VERSION ""

NS_ :

BS_:

BU_: VCM TCM ECM EBS ACM

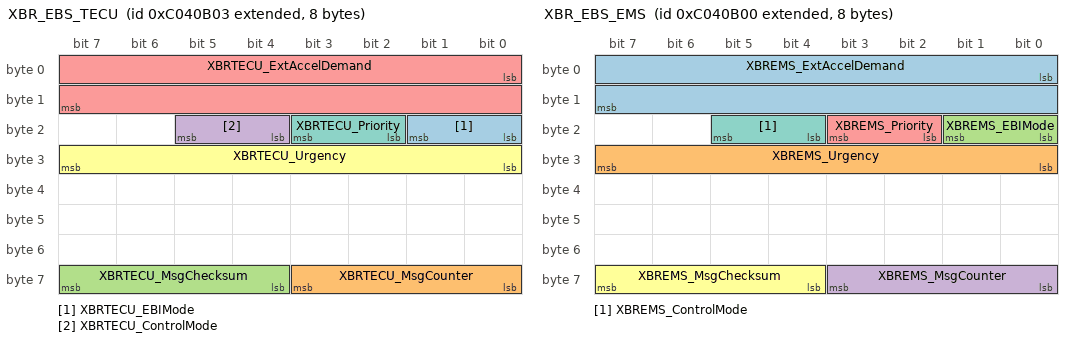
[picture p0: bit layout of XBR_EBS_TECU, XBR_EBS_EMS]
BO_ 2349075203 XBR_EBS_TECU: 8 TCM
 SG_ XBRTECU_EBIMode : 16|2@1+ (1,0) [0|0] ""  ECM,EBS,VCM
 SG_ XBRTECU_MsgCounter : 56|4@1+ (1,0) [0|15] "Count"  VCM,EBS,ECM
 SG_ XBRTECU_MsgChecksum : 60|4@1+ (1,0) [0|15] "Count"  EBS,VCM,ECM
 SG_ XBRTECU_ControlMode : 20|2@1+ (1,0) [0|0] ""  VCM,ECM,EBS
 SG_ XBRTECU_ExtAccelDemand : 0|16@1+ (0.00048828125,-15.687) [-15.687|16.31251171875] "m_per_s_squared"  ECM,VCM,EBS
 SG_ XBRTECU_Urgency : 24|8@1+ (0.4,0) [0|102] "Percent"  ECM,EBS,VCM
 SG_ XBRTECU_Priority : 18|2@1+ (1,0) [0|0] ""  EBS,VCM,ECM

BO_ 2349075200 XBR_EBS_EMS: 8 ECM
 SG_ XBREMS_ExtAccelDemand : 0|16@1+ (0.00048828125,-15.687) [-15.687|16.31251171875] "m_per_s_squared"  VCM,EBS
 SG_ XBREMS_Urgency : 24|8@1+ (0.4,0) [0|102] "Percent"  EBS,VCM
 SG_ XBREMS_EBIMode : 16|2@1+ (1,0) [0|0] ""  VCM,EBS
 SG_ XBREMS_MsgCounter : 56|4@1+ (1,0) [0|15] "Count"  VCM,EBS
 SG_ XBREMS_Priority : 18|2@1+ (1,0) [0|0] ""  VCM,EBS
 SG_ XBREMS_MsgChecksum : 60|4@1+ (1,0) [0|15] "Count"  EBS,VCM
 SG_ XBREMS_ControlMode : 20|2@1+ (1,0) [0|0] ""  EBS,VCM

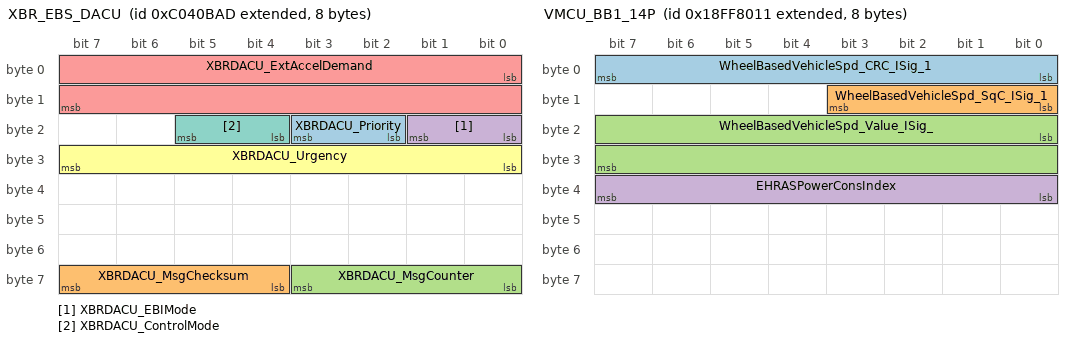
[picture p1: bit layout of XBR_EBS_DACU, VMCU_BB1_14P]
BO_ 2349075373 XBR_EBS_DACU: 8 VCM
 SG_ XBRDACU_Priority : 18|2@1+ (1,0) [0|0] ""  EBS,TCM
 SG_ XBRDACU_MsgChecksum : 60|4@1+ (1,0) [0|15] "Count"  EBS,TCM
 SG_ XBRDACU_MsgCounter : 56|4@1+ (1,0) [0|15] "Count"  EBS,TCM
 SG_ XBRDACU_EBIMode : 16|2@1+ (1,0) [0|0] ""  EBS,TCM
 SG_ XBRDACU_ExtAccelDemand : 0|16@1+ (0.00048828125,-15.687) [-15.687|16.31251171875] "m_per_s_squared"  EBS,TCM
 SG_ XBRDACU_Urgency : 24|8@1+ (0.4,0) [0|102] "Percent"  EBS,TCM
 SG_ XBRDACU_ControlMode : 20|2@1+ (1,0) [0|0] ""  TCM,EBS

BO_ 2566848256 WFI_X_EMS: 8 ECM
 SG_ WaterInFuelAlarm : 0|2@1+ (1,0) [0|0] ""  VCM

BO_ 2566845201 VP1_X_VMCU: 8 VCM
 SG_ VehiclePosSAE_Longitude : 32|32@1+ (1E-007,-210) [-210|219.4967295] "deg"  TCM
 SG_ VehiclePosSAE_Latitude : 0|32@1+ (1E-007,-210) [-210|219.4967295] "deg"  TCM

BO_ 2566881297 VMCU_BB1_14P: 8 VCM
 SG_ WheelBasedVehicleSpd_CRC_ISig_1 : 0|8@1+ (1,0) [0|255] ""  EBS
 SG_ WheelBasedVehicleSpd_SqC_ISig_1 : 8|4@1+ (1,0) [0|14] "NotApplicable"  EBS
 SG_ WheelBasedVehicleSpd_Value_ISig_ : 16|16@1+ (0.00390625,0) [0|255.99609375] "Km_per_h"  EBS
 SG_ EHRASPowerConsIndex : 32|8@1+ (0.5,0) [0|127.5] "Percent"  EBS

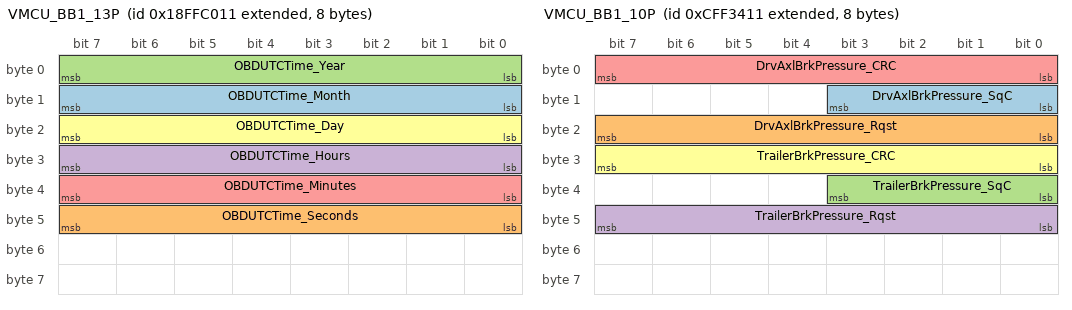
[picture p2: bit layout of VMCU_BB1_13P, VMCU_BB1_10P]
BO_ 2566897681 VMCU_BB1_13P: 8 VCM
 SG_ OBDUTCTime_Month : 8|8@1+ (1,0) [0|255] "Months"  ECM,ACM
 SG_ OBDUTCTime_Seconds : 40|8@1+ (0.25,0) [0|63.75] "s"  ECM,ACM
 SG_ OBDUTCTime_Year : 0|8@1+ (1,1985) [1985|2240] "Years"  ACM,ECM
 SG_ OBDUTCTime_Hours : 24|8@1+ (1,0) [0|255] "h"  ECM,ACM
 SG_ OBDUTCTime_Minutes : 32|8@1+ (1,0) [0|255] "min"  ECM,ACM
 SG_ OBDUTCTime_Day : 16|8@1+ (0.25,0) [0|63.75] "Days"  ACM,ECM

BO_ 2365535249 VMCU_BB1_10P: 8 VCM
 SG_ DrvAxlBrkPressure_SqC : 8|4@1+ (1,0) [0|14] "NotApplicable"  EBS
 SG_ DrvAxlBrkPressure_Rqst : 16|8@1+ (5,0) [0|1275] "kPa"  EBS
 SG_ TrailerBrkPressure_SqC : 32|4@1+ (1,0) [0|14] "NotApplicable"  EBS
 SG_ TrailerBrkPressure_Rqst : 40|8@1+ (5,0) [0|1275] "kPa"  EBS
 SG_ DrvAxlBrkPressure_CRC : 0|8@1+ (1,0) [0|255] ""  EBS
 SG_ TrailerBrkPressure_CRC : 24|8@1+ (1,0) [0|255] ""  EBS

BO_ 2499788567 VMCU_BB1_08P: 8 VCM
 SG_ DrvrRetarderBrakeBlending_rqst_I : 10|2@1+ (1,0) [0|0] ""  TCM,EBS
 SG_ Trailer2LiftAxle2PosReq : 44|2@1+ (1,0) [0|0] ""  EBS
 SG_ Trailer4LiftAxle2PosReq : 52|2@1+ (1,0) [0|0] ""  EBS
 SG_ GearLeverPositionBackup : 12|4@1+ (1,0) [0|0] ""  TCM
 SG_ Trailer2LiftAxle1PosReq : 42|2@1+ (1,0) [0|0] ""  EBS
 SG_ Trailer5LiftAxle2PosReq : 56|2@1+ (1,0) [0|0] ""  EBS
 SG_ GearLeverPos2Backup_CRC : 16|8@1+ (1,0) [0|255] ""  TCM
 SG_ DriverRetarderRequest_ISig_1 : 3|3@1+ (1,0) [0|0] ""  EBS,ECM,TCM,ACM
 SG_ Trailer1LiftAxl2ePosReq : 40|2@1+ (1,0) [0|0] ""  EBS
 SG_ GearLeverPos2Backup_SqC : 24|4@1+ (1,0) [0|14] "NotApplicable"  TCM
 SG_ Trailer1LiftAxle1PosReq : 38|2@1+ (1,0) [0|0] ""  EBS
 SG_ DrvrRetarderBrakeProgram_rqst_IS : 8|2@1+ (1,0) [0|0] ""  TCM
 SG_ Trailer4LiftAxle1PosReq : 50|2@1+ (1,0) [0|0] ""  EBS
 SG_ EHERearAxleSteeringFuncStatus : 35|3@1+ (1,0) [0|0] ""  EBS
 SG_ EHRearAxleSteeringFuncStatus : 32|3@1+ (1,0) [0|0] ""  EBS
 SG_ Trailer5LiftAxle1PosReq : 54|2@1+ (1,0) [0|0] ""  EBS
 SG_ Trailer3LiftAxle1PosReq : 46|2@1+ (1,0) [0|0] ""  EBS
 SG_ GearLeverPos2Backup_Rqst : 28|4@1+ (1,0) [0|0] ""  TCM
 SG_ Trailer3LiftAxle2PosReq : 48|2@1+ (1,0) [0|0] ""  EBS

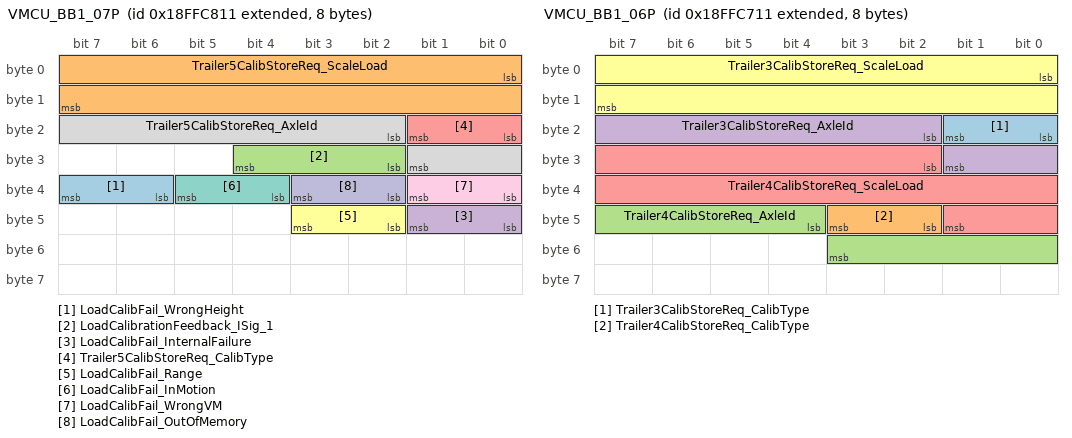
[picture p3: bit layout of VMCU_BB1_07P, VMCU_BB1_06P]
BO_ 2566899729 VMCU_BB1_07P: 8 VCM
 SG_ LoadCalibFail_WrongHeight : 38|2@1+ (1,0) [0|0] ""  EBS
 SG_ Trailer5CalibStoreReq_ScaleLoad : 0|16@1+ (1,0) [0|65535] "kg"  EBS
 SG_ LoadCalibrationFeedback_ISig_1 : 26|3@1+ (1,0) [0|0] ""  EBS
 SG_ LoadCalibFail_InternalFailure : 40|2@1+ (1,0) [0|0] ""  EBS
 SG_ Trailer5CalibStoreReq_CalibType : 16|2@1+ (1,0) [0|0] ""  EBS
 SG_ LoadCalibFail_Range : 42|2@1+ (1,0) [0|0] ""  EBS
 SG_ LoadCalibFail_InMotion : 36|2@1+ (1,0) [0|0] ""  EBS
 SG_ Trailer5CalibStoreReq_AxleId : 18|8@1+ (1,0) [0|255] "NotApplicable"  EBS
 SG_ LoadCalibFail_WrongVM : 32|2@1+ (1,0) [0|0] ""  EBS
 SG_ LoadCalibFail_OutOfMemory : 34|2@1+ (1,0) [0|0] ""  EBS

BO_ 2566899473 VMCU_BB1_06P: 8 VCM
 SG_ Trailer3CalibStoreReq_CalibType : 16|2@1+ (1,0) [0|0] ""  EBS
 SG_ Trailer4CalibStoreReq_CalibType : 42|2@1+ (1,0) [0|0] ""  EBS
 SG_ Trailer4CalibStoreReq_AxleId : 44|8@1+ (1,0) [0|255] "NotApplicable"  EBS
 SG_ Trailer3CalibStoreReq_AxleId : 18|8@1+ (1,0) [0|255] "NotApplicable"  EBS
 SG_ Trailer4CalibStoreReq_ScaleLoad : 26|16@1+ (1,0) [0|65535] "kg"  EBS
 SG_ Trailer3CalibStoreReq_ScaleLoad : 0|16@1+ (1,0) [0|65535] "kg"  EBS

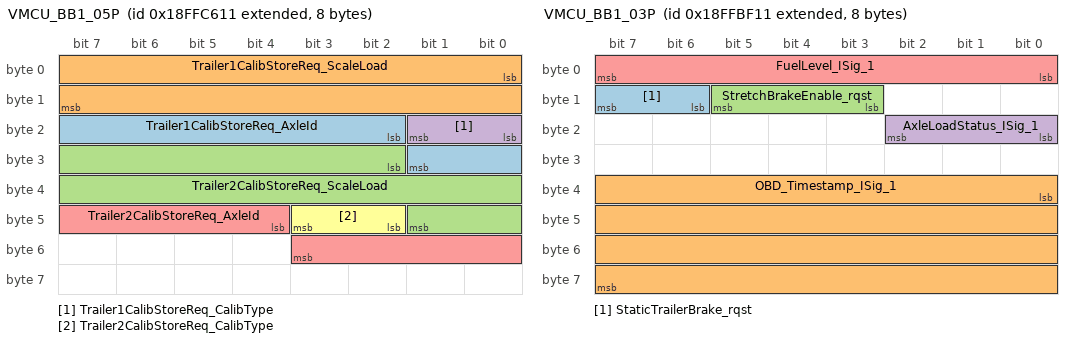
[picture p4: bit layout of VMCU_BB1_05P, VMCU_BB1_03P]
BO_ 2566899217 VMCU_BB1_05P: 8 VCM
 SG_ Trailer1CalibStoreReq_AxleId : 18|8@1+ (1,0) [0|255] "NotApplicable"  EBS
 SG_ Trailer1CalibStoreReq_ScaleLoad : 0|16@1+ (1,0) [0|65535] "kg"  EBS
 SG_ Trailer2CalibStoreReq_ScaleLoad : 26|16@1+ (1,0) [0|65535] "kg"  EBS
 SG_ Trailer1CalibStoreReq_CalibType : 16|2@1+ (1,0) [0|0] ""  EBS
 SG_ Trailer2CalibStoreReq_AxleId : 44|8@1+ (1,0) [0|255] "NotApplicable"  EBS
 SG_ Trailer2CalibStoreReq_CalibType : 42|2@1+ (1,0) [0|0] ""  EBS

BO_ 2499751697 VMCU_BB1_04P: 8 VCM
 SG_ EngineStopReqBackup : 12|2@1+ (1,0) [0|0] ""  ECM
 SG_ TrailerWithoutABS_ISig_1 : 18|2@1+ (1,0) [0|0] ""  ECM,TCM,EBS
 SG_ LowAirPressureAlert_ISig_1 : 10|2@1+ (1,0) [0|0] ""  ECM
 SG_ ACC_SGO_Status_ISig_1 : 14|4@1+ (1,0) [0|0] ""  EBS,TCM
 SG_ DifferentialLockStateFrAxle2 : 38|2@1+ (1,0) [0|0] ""  EBS
 SG_ SetHSAOperation_ISig_1 : 40|3@1+ (1,0) [0|0] ""  EBS
 SG_ CtaBs_HSABbRequest : 36|2@1+ (1,0) [0|0] ""  EBS
 SG_ AWBEnableRequest_ISig_1 : 43|2@1+ (1,0) [0|0] ""  ECM,TCM
 SG_ RearPropulsionStat_Rear2Axle_ISi : 28|4@1+ (1,0) [0|0] ""  TCM,ECM,EBS
 SG_ DifferentialLockStateCentral_ISi : 6|2@1+ (1,0) [0|0] ""  TCM,ECM,EBS
 SG_ CentralRearDiffLock_stat_ISig_1 : 4|2@1+ (1,0) [0|0] ""  TCM
 SG_ ACCHSARequest : 45|3@1+ (1,0) [0|0] ""  EBS
 SG_ DifferentialLockStateFrAxle1_ISi : 8|2@1+ (1,0) [0|0] ""  EBS
 SG_ RearAxle2DiffLock_stat_ISig_1 : 2|2@1+ (1,0) [0|0] ""  TCM
 SG_ TrailerConnected_ISig_1 : 21|2@1+ (1,0) [0|0] ""  EBS
 SG_ DifferentialLockStateCentral2 : 48|2@1+ (1,0) [0|0] ""  EBS
 SG_ RearPropulsionStat_Rear3Axle_ISi : 32|4@1+ (1,0) [0|0] ""  EBS,ECM,TCM
 SG_ RearPropulsionStat_Rear1Axle_ISi : 24|4@1+ (1,0) [0|0] ""  EBS,ECM,TCM
 SG_ RearAxle1DiffLock_stat_ISig_1 : 0|2@1+ (1,0) [0|0] ""  TCM

BO_ 2566897425 VMCU_BB1_03P: 8 VCM
 SG_ StaticTrailerBrake_rqst : 14|2@1+ (1,0) [0|0] ""  EBS
 SG_ OBD_Timestamp_ISig_1 : 32|32@1+ (1,0) [0|4294967295] "s"  EBS
 SG_ StretchBrakeEnable_rqst : 11|3@1+ (1,0) [0|0] ""  EBS
 SG_ AxleLoadStatus_ISig_1 : 16|3@1+ (1,0) [0|0] ""  TCM,EBS
 SG_ FuelLevel_ISig_1 : 0|8@1+ (0.4,0) [0|102] "Percent"  ECM,EBS

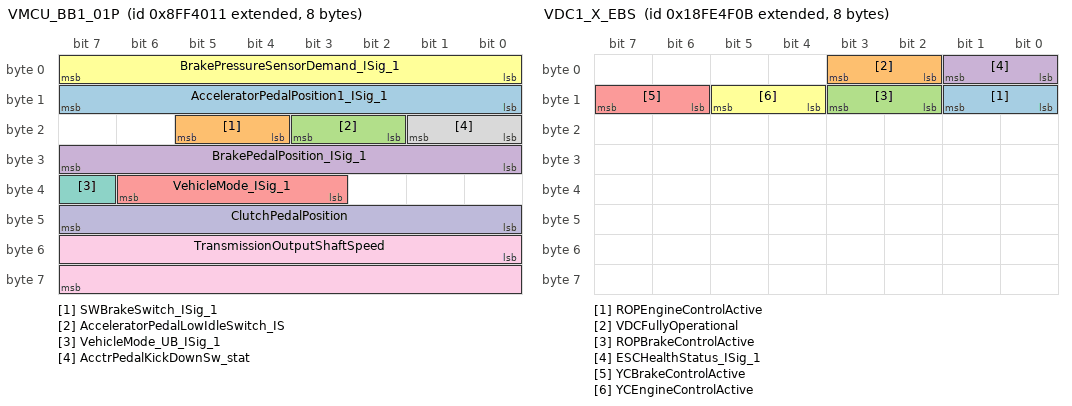
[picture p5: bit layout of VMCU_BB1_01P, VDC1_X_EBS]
BO_ 2298429457 VMCU_BB1_01P: 8 VCM
 SG_ AcceleratorPedalPosition1_ISig_1 : 8|8@1+ (0.4,0) [0|102] "Percent"  EBS,TCM,ECM
 SG_ SWBrakeSwitch_ISig_1 : 20|2@1+ (1,0) [0|0] ""  EBS
 SG_ AcceleratorPedalLowIdleSwitch_IS : 18|2@1+ (1,0) [0|0] ""  TCM
 SG_ BrakePedalPosition_ISig_1 : 24|8@1+ (0.4,0) [0|102] "Percent"  TCM,EBS
 SG_ VehicleMode_ISig_1 : 35|4@1+ (1,0) [0|0] ""  ACM,TCM,ECM,EBS
 SG_ BrakePressureSensorDemand_ISig_1 : 0|8@1+ (1,0) [0|255] "Percent"  EBS
 SG_ VehicleMode_UB_ISig_1 : 39|1@1+ (1,0) [0|0] ""  ACM,ECM,EBS,TCM
 SG_ AcctrPedalKickDownSw_stat : 16|2@1+ (1,0) [0|0] ""  TCM,ECM
 SG_ TransmissionOutputShaftSpeed : 48|16@1+ (0.125,0) [0|8191.875] "rpm"  ECM,ACM
 SG_ ClutchPedalPosition : 40|8@1+ (0.4,0) [0|102] "Percent"  EBS

BO_ 2566832401 VDHR_X_VMCU: 8 VCM
 SG_ TotalVehicleDistanceHighRes_ISig : 0|32@1+ (5,0) [0|21474836475] "m"  TCM,EBS,ACM,ECM

BO_ 2364541195 VDC2_X_EBS: 8 EBS
 SG_ SteeringWheelAngle_ISig_1 : 0|16@1+ (0.0009765625,-31.374) [-31.374|32.6250234375] "rad"  ECM
 SG_ YawRate_ISig_1 : 24|16@1+ (0.000122,-3.92) [-3.92|4.07527] "Rad_per_s"  TCM

BO_ 2566803211 VDC1_X_EBS: 8 EBS
 SG_ ROPEngineControlActive : 8|2@1+ (1,0) [0|0] ""  TCM,VCM
 SG_ VDCFullyOperational : 2|2@1+ (1,0) [0|0] ""  VCM
 SG_ ROPBrakeControlActive : 10|2@1+ (1,0) [0|0] ""  VCM,TCM
 SG_ ESCHealthStatus_ISig_1 : 0|2@1+ (1,0) [0|0] ""  VCM
 SG_ YCBrakeControlActive : 14|2@1+ (1,0) [0|0] ""  TCM,VCM
 SG_ YCEngineControlActive : 12|2@1+ (1,0) [0|0] ""  TCM,VCM

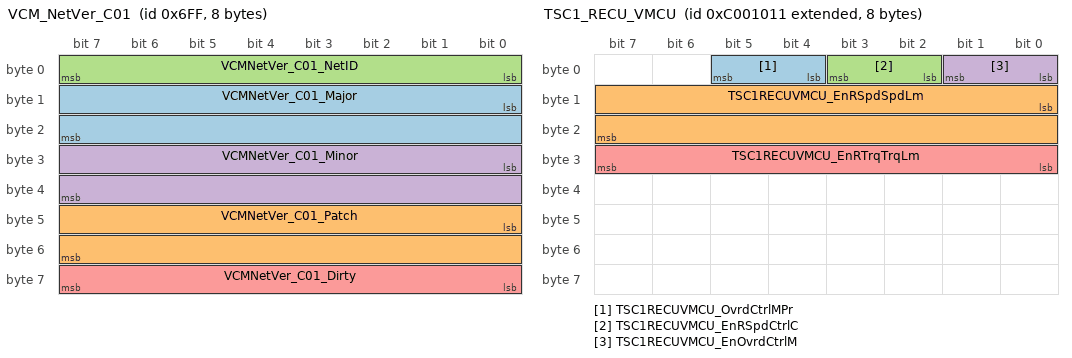
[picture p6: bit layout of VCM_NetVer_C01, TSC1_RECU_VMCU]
BO_ 1791 VCM_NetVer_C01: 8 VCM
 SG_ VCMNetVer_C01_Major : 8|16@1+ (1,0) [0|65535] "Not Applicable" Vector__XXX
 SG_ VCMNetVer_C01_Patch : 40|16@1+ (1,0) [0|65535] "Not Applicable" Vector__XXX
 SG_ VCMNetVer_C01_NetID : 0|8@1+ (1,0) [0|255] "NotApplicable" Vector__XXX
 SG_ VCMNetVer_C01_Minor : 24|16@1+ (1,0) [0|65535] "Not Applicable" Vector__XXX
 SG_ VCMNetVer_C01_Dirty : 56|8@1+ (1,0) [0|255] "NotApplicable" Vector__XXX

BO_ 2365524497 VCM_02P_C01: 8 VCM
 SG_ DoorsAjar_stat_ISig_1 : 3|3@1+ (1,0) [0|0] ""  EBS

BO_ 2671902706 TesterFuncDiagMsg_C01: 8 VCM
 SG_ FuncDiagDataTester_ISig_1 : 0|64@1+ (1,0) [0|0] ""  EBS,ACM

BO_ 2671902708 TesterFuncDiagMsgF4_C01: 8 VCM
 SG_ FuncDiagDataIntTesterF4_ISig_1 : 0|64@1+ (1,0) [0|0] ""  ACM,EBS

BO_ 2348814353 TSC1_RECU_VMCU: 8 VCM
 SG_ TSC1RECUVMCU_OvrdCtrlMPr : 4|2@1+ (1,0) [0|0] ""  ACM,EBS
 SG_ TSC1RECUVMCU_EnRSpdSpdLm : 8|16@1+ (0.125,0) [0|8191.875] "rpm"  EBS,ACM
 SG_ TSC1RECUVMCU_EnRSpdCtrlC : 2|2@1+ (1,0) [0|0] ""  EBS,ACM
 SG_ TSC1RECUVMCU_EnOvrdCtrlM : 0|2@1+ (1,0) [0|0] ""  EBS,ACM
 SG_ TSC1RECUVMCU_EnRTrqTrqLm : 24|8@1+ (1,-125) [-125|130] "Percent"  EBS,ACM

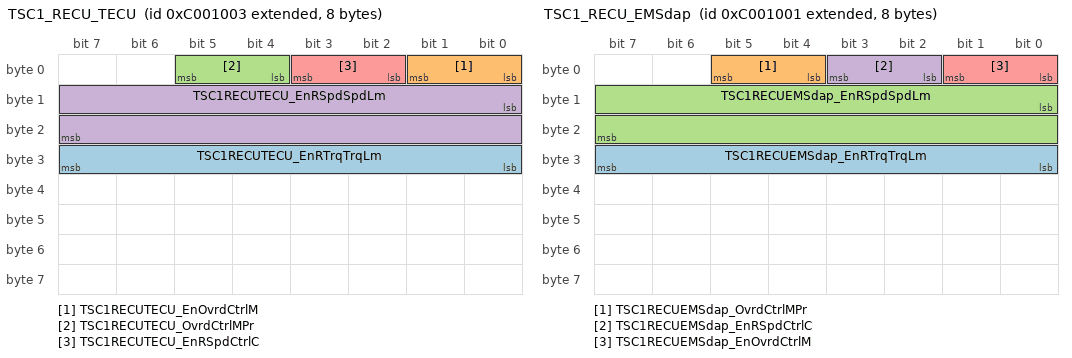
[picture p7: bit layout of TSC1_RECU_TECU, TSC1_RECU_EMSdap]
BO_ 2348814339 TSC1_RECU_TECU: 8 TCM
 SG_ TSC1RECUTECU_EnRTrqTrqLm : 24|8@1+ (1,-125) [-125|130] "Percent"  VCM,ECM,ACM
 SG_ TSC1RECUTECU_EnOvrdCtrlM : 0|2@1+ (1,0) [0|0] ""  ECM,ACM,VCM
 SG_ TSC1RECUTECU_OvrdCtrlMPr : 4|2@1+ (1,0) [0|0] ""  ECM,VCM,ACM
 SG_ TSC1RECUTECU_EnRSpdSpdLm : 8|16@1+ (0.125,0) [0|8191.875] "rpm"  VCM,ACM,ECM
 SG_ TSC1RECUTECU_EnRSpdCtrlC : 2|2@1+ (1,0) [0|0] ""  ACM,VCM,ECM

BO_ 2348814337 TSC1_RECU_EMSdap: 8 ECM
 SG_ TSC1RECUEMSdap_EnRTrqTrqLm : 24|8@1+ (1,-125) [-125|130] "Percent"  ACM,VCM
 SG_ TSC1RECUEMSdap_OvrdCtrlMPr : 4|2@1+ (1,0) [0|0] ""  ACM,VCM
 SG_ TSC1RECUEMSdap_EnRSpdSpdLm : 8|16@1+ (0.125,0) [0|8191.875] "rpm"  VCM,ACM
 SG_ TSC1RECUEMSdap_EnRSpdCtrlC : 2|2@1+ (1,0) [0|0] ""  ACM,VCM
 SG_ TSC1RECUEMSdap_EnOvrdCtrlM : 0|2@1+ (1,0) [0|0] ""  VCM,ACM

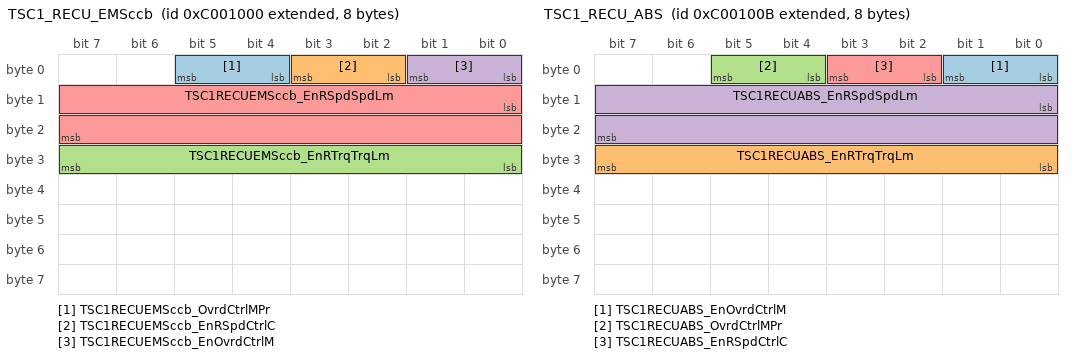
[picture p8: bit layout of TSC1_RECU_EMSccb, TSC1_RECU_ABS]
BO_ 2348814336 TSC1_RECU_EMSccb: 8 ECM
 SG_ TSC1RECUEMSccb_OvrdCtrlMPr : 4|2@1+ (1,0) [0|0] ""  ACM,VCM
 SG_ TSC1RECUEMSccb_EnRSpdCtrlC : 2|2@1+ (1,0) [0|0] ""  VCM,ACM
 SG_ TSC1RECUEMSccb_EnRTrqTrqLm : 24|8@1+ (1,-125) [-125|130] "Percent"  ACM,VCM
 SG_ TSC1RECUEMSccb_EnOvrdCtrlM : 0|2@1+ (1,0) [0|0] ""  VCM,ACM
 SG_ TSC1RECUEMSccb_EnRSpdSpdLm : 8|16@1+ (0.125,0) [0|8191.875] "rpm"  ACM,VCM

BO_ 2348814347 TSC1_RECU_ABS: 8 EBS
 SG_ TSC1RECUABS_EnOvrdCtrlM : 0|2@1+ (1,0) [0|0] ""  TCM,ACM
 SG_ TSC1RECUABS_EnRTrqTrqLm : 24|8@1+ (1,-125) [-125|130] "Percent"  ACM,TCM
 SG_ TSC1RECUABS_OvrdCtrlMPr : 4|2@1+ (1,0) [0|0] ""  ACM,TCM
 SG_ TSC1RECUABS_EnRSpdSpdLm : 8|16@1+ (0.125,0) [0|8191.875] "rpm"  ACM,TCM
 SG_ TSC1RECUABS_EnRSpdCtrlC : 2|2@1+ (1,0) [0|0] ""  ACM,TCM

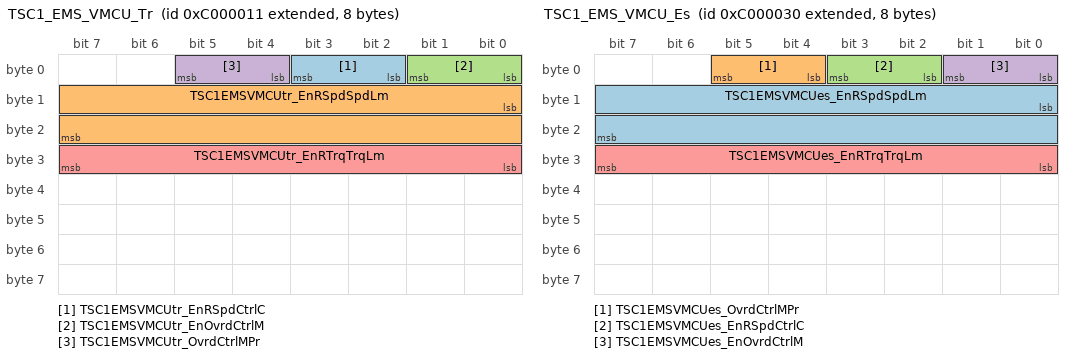
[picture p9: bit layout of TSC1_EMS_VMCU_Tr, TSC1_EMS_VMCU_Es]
BO_ 2348810257 TSC1_EMS_VMCU_Tr: 8 VCM
 SG_ TSC1EMSVMCUtr_EnRSpdCtrlC : 2|2@1+ (1,0) [0|0] ""  ECM
 SG_ TSC1EMSVMCUtr_EnRSpdSpdLm : 8|16@1+ (0.125,0) [0|8191.875] "rpm"  ECM
 SG_ TSC1EMSVMCUtr_EnOvrdCtrlM : 0|2@1+ (1,0) [0|0] ""  ECM
 SG_ TSC1EMSVMCUtr_OvrdCtrlMPr : 4|2@1+ (1,0) [0|0] ""  ECM
 SG_ TSC1EMSVMCUtr_EnRTrqTrqLm : 24|8@1+ (1,-125) [-125|130] "Percent"  ECM

BO_ 2348810288 TSC1_EMS_VMCU_Es: 8 VCM
 SG_ TSC1EMSVMCUes_EnRSpdSpdLm : 8|16@1+ (0.125,0) [0|8191.875] "rpm"  TCM,ECM
 SG_ TSC1EMSVMCUes_OvrdCtrlMPr : 4|2@1+ (1,0) [0|0] ""  ECM,TCM
 SG_ TSC1EMSVMCUes_EnRSpdCtrlC : 2|2@1+ (1,0) [0|0] ""  ECM,TCM
 SG_ TSC1EMSVMCUes_EnOvrdCtrlM : 0|2@1+ (1,0) [0|0] ""  ECM,TCM
 SG_ TSC1EMSVMCUes_EnRTrqTrqLm : 24|8@1+ (1,-125) [-125|130] "Percent"  ECM,TCM

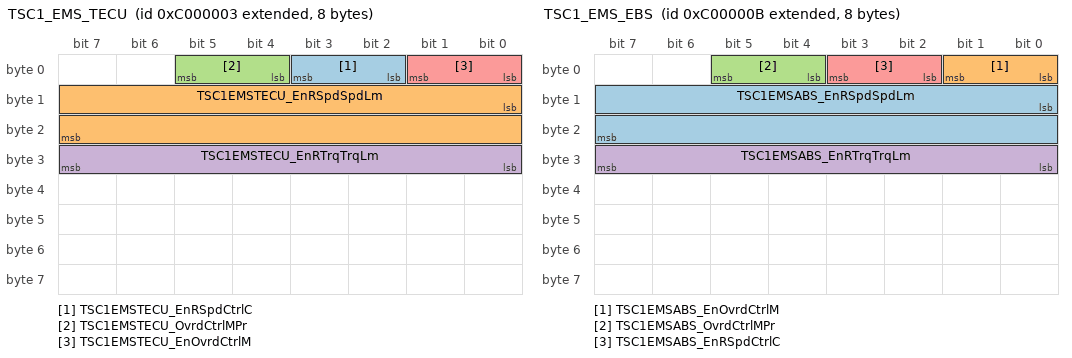
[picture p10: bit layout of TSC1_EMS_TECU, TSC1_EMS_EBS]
BO_ 2348810243 TSC1_EMS_TECU: 8 TCM
 SG_ TSC1EMSTECU_EnRSpdCtrlC : 2|2@1+ (1,0) [0|0] ""  VCM,ECM
 SG_ TSC1EMSTECU_EnRSpdSpdLm : 8|16@1+ (0.125,0) [0|8191.875] "rpm"  VCM,ECM
 SG_ TSC1EMSTECU_OvrdCtrlMPr : 4|2@1+ (1,0) [0|0] ""  VCM,ECM
 SG_ TSC1EMSTECU_EnRTrqTrqLm : 24|8@1+ (1,-125) [-125|130] "Percent"  VCM,ECM
 SG_ TSC1EMSTECU_EnOvrdCtrlM : 0|2@1+ (1,0) [0|0] ""  VCM,ECM

BO_ 2348810251 TSC1_EMS_EBS: 8 EBS
 SG_ TSC1EMSABS_EnRSpdSpdLm : 8|16@1+ (0.125,0) [0|8191.875] "rpm"  ECM
 SG_ TSC1EMSABS_EnOvrdCtrlM : 0|2@1+ (1,0) [0|0] ""  ECM
 SG_ TSC1EMSABS_OvrdCtrlMPr : 4|2@1+ (1,0) [0|0] ""  ECM
 SG_ TSC1EMSABS_EnRTrqTrqLm : 24|8@1+ (1,-125) [-125|130] "Percent"  ECM
 SG_ TSC1EMSABS_EnRSpdCtrlC : 2|2@1+ (1,0) [0|0] ""  ECM

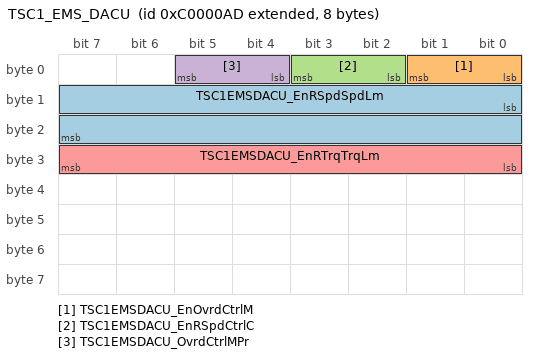
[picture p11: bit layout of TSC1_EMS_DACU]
BO_ 2348810413 TSC1_EMS_DACU: 8 VCM
 SG_ TSC1EMSDACU_EnRSpdSpdLm : 8|16@1+ (0.125,0) [0|8191.875] "rpm"  ECM
 SG_ TSC1EMSDACU_EnOvrdCtrlM : 0|2@1+ (1,0) [0|0] ""  ECM
 SG_ TSC1EMSDACU_EnRSpdCtrlC : 2|2@1+ (1,0) [0|0] ""  ECM
 SG_ TSC1EMSDACU_OvrdCtrlMPr : 4|2@1+ (1,0) [0|0] ""  ECM
 SG_ TSC1EMSDACU_EnRTrqTrqLm : 24|8@1+ (1,-125) [-125|130] "Percent"  ECM

CM_ "COM_MATRIX_T3_2.3.0";
CM_ BU_ VCM "Vehicle Control Module";
CM_ BU_ TCM "Transmission Control Module";
CM_ BU_ ECM "Engine Control Module";
CM_ BU_ EBS "Electronic Braking System";
CM_ BU_ ACM "Aftertreatment Control Module";
CM_ BO_ 2349075203 "PGN 1024 External Brake Request";
CM_ SG_ 2349075203 XBRTECU_ExtAccelDemand "65024 - 65279 Error ; 65280 - 65535 Not available";
CM_ SG_ 2349075203 XBRTECU_Urgency "254 Error ; 255 Not available";
CM_ BO_ 2349075200 "PGN 1024 External Brake Request";
CM_ BO_ 2349075373 "PGN 1024 External Brake Request";
CM_ SG_ 2349075373 XBRDACU_ExtAccelDemand "65024 - 65279 Error ; 65280 - 65535 Not available";
CM_ SG_ 2349075373 XBRDACU_Urgency "254 Error ; 255 Not available";
CM_ BO_ 2566848256 "PGN 65279 Water in Fuel Indicator";
CM_ BO_ 2566845201 "PGN 65267 Vehicle Position";
CM_ BO_ 2566832401 "PGN 65217 High Resolution Vehicle Distance";
CM_ BO_ 2364541195 "PGN 61449 Vehicle Dynamic Stability Control 2";
CM_ BO_ 2566803211 "PGN 65103 Vehicle Dynamic Stability Control 1";
CM_ BO_ 2348814353 "PGN 0 Torque/Speed Control 1, From VMCU to RECU";
CM_ SG_ 2348814353 TSC1RECUVMCU_EnRSpdSpdLm "65024 - 65279 Error ; 65280 - 65535 Not available";
CM_ SG_ 2348814353 TSC1RECUVMCU_EnRTrqTrqLm "254 Error ; 255 Not available";
CM_ BO_ 2348814339 "PGN 0 Torque/Speed Control 1";
CM_ BO_ 2348814337 "PGN 0 Torque/Speed Control 1";
CM_ SG_ 2348814337 TSC1RECUEMSdap_EnRTrqTrqLm "254 Error ; 255 Not available";
CM_ SG_ 2348814337 TSC1RECUEMSdap_EnRSpdSpdLm "65024 - 65279 Error ; 65280 - 65535 Not available";
CM_ BO_ 2348814336 "PGN 0 Torque/Speed Control 1";
CM_ SG_ 2348814336 TSC1RECUEMSccb_EnRTrqTrqLm "254 Error ; 255 Not available";
CM_ SG_ 2348814336 TSC1RECUEMSccb_EnRSpdSpdLm "65024 - 65279 Error ; 65280 - 65535 Not available";
CM_ SG_ 2348814347 TSC1RECUABS_EnRTrqTrqLm "254 Error ; 255 Not available";
CM_ SG_ 2348814347 TSC1RECUABS_EnRSpdSpdLm "65024 - 65279 Error ; 65280 - 65535 Not available";
CM_ BO_ 2348810257 "PGN 0 Torque/Speed Control 1, Torque control, From VMCU to EMS";
CM_ SG_ 2348810257 TSC1EMSVMCUtr_EnRSpdSpdLm "65024 - 65279 Error ; 65280 - 65535 Not available";
CM_ SG_ 2348810257 TSC1EMSVMCUtr_EnRTrqTrqLm "254 Error ; 255 Not available";
CM_ BO_ 2348810288 "PGN 0 Torque/Speed Control 1, Engine speed control, From VMCU to EMS";
CM_ SG_ 2348810288 TSC1EMSVMCUes_EnRSpdSpdLm "65024 - 65279 Error ; 65280 - 65535 Not available";
CM_ SG_ 2348810288 TSC1EMSVMCUes_EnRTrqTrqLm "254 Error ; 255 Not available";
CM_ BO_ 2348810243 "PGN 0 Torque/Speed Control 1, From TECU to EMS";
CM_ SG_ 2348810243 TSC1EMSTECU_EnRSpdSpdLm "65024 - 65279 Error ; 65280 - 65535 Not available";
CM_ SG_ 2348810243 TSC1EMSTECU_EnRTrqTrqLm "254 Error ; 255 Not available";
CM_ BO_ 2348810251 "PGN 0 Torque/Speed Control 1, From EBS to EMS";
CM_ SG_ 2348810251 TSC1EMSABS_EnRSpdSpdLm "65024 - 65279 Error ; 65280 - 65535 Not available";
CM_ SG_ 2348810251 TSC1EMSABS_EnRTrqTrqLm "254 Error ; 255 Not available";
CM_ BO_ 2348810413 "PGN 0 Torque/Speed Control 1, From DACU to EMS";
CM_ SG_ 2348810413 TSC1EMSDACU_EnRSpdSpdLm "65024 - 65279 Error ; 65280 - 65535 Not available";
CM_ SG_ 2348810413 TSC1EMSDACU_EnRTrqTrqLm "254 Error ; 255 Not available";
BA_DEF_ BO_  "GenMsgStartDelayTime" INT 0 0;
BA_DEF_ BO_  "GenMsgDelayTime" INT 0 0;
BA_DEF_ BO_  "GenMsgNrOfRepetition" INT 0 0;
BA_DEF_ BO_  "GenMsgCycleTimeFast" INT 0 0;
BA_DEF_ BO_  "GenMsgCycleTime" INT 0 0;
BA_DEF_ BO_  "GenMsgSendType" ENUM  "Cyclic","NotUsed","NotUsed","NotUsed","NotUsed","NotUsed","NotUsed","IfActive","NoMsgSendType","NotUsed";
BA_DEF_ SG_  "GenSigStartValue" INT 0 0;
BA_DEF_ SG_  "GenSigCycleTimeActive" INT 0 0;
BA_DEF_ SG_  "GenSigCycleTime" INT 0 0;
BA_DEF_ SG_  "GenSigSendType" ENUM  "Cyclic","OnWrite","OnWriteWithRepetition","OnChange","OnChangeWithRepetition","IfActive","IfActiveWithRepetition","NoSigSendType","NotUsed","NotUsed","NotUsed","NotUsed","NotUsed";
BA_DEF_  "Baudrate" INT 0 1000000;
BA_DEF_  "NmType" STRING ;
BA_DEF_  "Manufacturer" STRING ;
BA_DEF_  "VersionYear" INT 0 99;
BA_DEF_  "VersionNumber" INT 0 99;
BA_DEF_  "VersionMonth" INT 1 12;
BA_DEF_  "VersionDay" INT 1 31;
BA_DEF_ BO_  "VFrameFormat" ENUM  "StandardCAN","ExtendedCAN","reserved","J1939PG","reserved","reserved","reserved","reserved","reserved","reserved","reserved","reserved","reserved","reserved","StandardCAN_FD","ExtendedCAN_FD";
BA_DEF_ BU_  "TpOwnSystemEcuNumber" HEX 0 255;
BA_DEF_ BO_  "TpJ1939VarDlc" ENUM  "No","Yes";
BA_DEF_ SG_  "SigType" ENUM  "Default","Range","RangeSigned","ASCII","Discrete","Control","ReferencePGN","DTC","StringDelimiter","StringLength","StringLengthControl";
BA_DEF_ SG_  "SeToolVersion_SIGNAL" STRING ;
BA_DEF_ SG_  "SeToolUniqueID_SIGNAL" STRING ;
BA_DEF_ SG_  "SeToolOwnerSigGroup_SIGNAL" STRING ;
BA_DEF_ SG_  "SeToolOwnerSigGroupID_SIGNAL" STRING ;
BA_DEF_ SG_  "SeToolName_SIGNAL" STRING ;
BA_DEF_ SG_  "SeToolItemID_SIGNAL" STRING ;
BA_DEF_ SG_  "SeToolAncestorID_SIGNAL" STRING ;
BA_DEF_ BU_  "ReRoutJ1939ToCom" ENUM  "No","Yes";
BA_DEF_  "ProtocolType" STRING ;
BA_DEF_ SG_  "Platform_VMCU1_Sig" ENUM  "No","Yes";
BA_DEF_ BU_  "NmStationAddress" INT 0 255;
BA_DEF_ BU_  "NmJ1939IdentityNumber" INT 0 2097151;
BA_DEF_  "NmAsrWaitBusSleepTime" INT 0 65535;
BA_DEF_  "NmAsrTimeoutTime" INT 0 65535;
BA_DEF_  "NmAsrRepeatMessageTime" INT 0 65535;
BA_DEF_ BU_  "NmAsrNodeIdentifier" HEX 0 253;
BA_DEF_ BU_  "NmAsrNode" ENUM  "No","Yes";
BA_DEF_  "NmAsrMessageCount" INT 1 256;
BA_DEF_  "NmAsrCanMsgCycleTime" INT 0 65535;
BA_DEF_  "NmAsrBaseAddress" HEX 0 536870911;
BA_DEF_ SG_  "NeedsUpdateBit" ENUM  "No","Yes";
BA_DEF_ BU_  "IsOBDrelevant" ENUM  "No","Yes";
BA_DEF_ SG_  "GenSigMaxLatency" INT 0 65535;
BA_DEF_ SG_  "GenSigILSupport" ENUM  "Yes","No";
BA_DEF_ BO_  "GenMsgILSupport" ENUM  "No","Yes";
BA_DEF_ SG_  "E2EProfile" STRING ;
BA_DEF_  "E2EP05WindowSize" INT 0 65535;
BA_DEF_  "E2EP05ProfileName" STRING ;
BA_DEF_  "E2EP05MinOkStateValid" INT 0 65535;
BA_DEF_  "E2EP05MinOkStateInvalid" INT 0 65535;
BA_DEF_  "E2EP05MinOkStateInit" INT 0 65535;
BA_DEF_  "E2EP05MaxErrorStateValid" INT 0 65535;
BA_DEF_  "E2EP05MaxErrorStateInvalid" INT 0 65535;
BA_DEF_  "E2EP05MaxErrorStateInit" INT 0 65535;
BA_DEF_  "E2EP05MaxDeltaCounter" INT 0 65535;
BA_DEF_  "E2EP01WindowSize" INT 0 65535;
BA_DEF_  "E2EP01SyncCounterInit" INT 0 65535;
BA_DEF_  "E2EP01ProfileName" STRING ;
BA_DEF_  "E2EP01MinOkStateValid" INT 0 65535;
BA_DEF_  "E2EP01MinOkStateInvalid" INT 0 65535;
BA_DEF_  "E2EP01MinOkStateInit" INT 0 65535;
BA_DEF_  "E2EP01MaxNoNewOrRepeatedData" INT 0 65535;
BA_DEF_  "E2EP01MaxErrorStateValid" INT 0 65535;
BA_DEF_  "E2EP01MaxErrorStateInvalid" INT 0 65535;
BA_DEF_  "E2EP01MaxErrorStateInit" INT 0 65535;
BA_DEF_  "E2EP01MaxDeltaCounter" INT 0 65535;
BA_DEF_  "E2EP01DataIdMode" ENUM  "all16Bit","alternating8Bit","lower12Bit","lower8Bit";
BA_DEF_  "E2EP01CounterOffset" INT 0 65535;
BA_DEF_ SG_  "E2EDataLength" INT 0 65535;
BA_DEF_ SG_  "E2EDataId" INT 0 65535;
BA_DEF_ BU_  "DiagnosticClientAddress" HEX 0 255;
BA_DEF_ BO_  "DiagUUDTResponse" ENUM  "No","Yes";
BA_DEF_ BO_  "DiagState" ENUM  "No","Yes";
BA_DEF_ BU_  "DiagRole" ENUM  "None","OBDTester","ExternalTester","InternalTester";
BA_DEF_ BO_  "DiagResponse" ENUM  "No","Yes";
BA_DEF_ BO_  "DiagRequest" ENUM  "No","Yes";
BA_DEF_ BO_  "DiagConnection" HEX 0 65535;
BA_DEF_  "DBName" STRING ;
BA_DEF_ BO_  "CanTpFcFrameId" HEX 0 2147483647;
BA_DEF_ BO_  "CanTpBs" INT 0 255;
BA_DEF_  "BusType" STRING ;
BA_DEF_ SG_  "SystemSignalLongSymbol" STRING ;
BA_DEF_REL_ BU_SG_REL_  "GenSigTimeoutTime" INT 0 65535;
BA_DEF_REL_ BU_SG_REL_  "GenSigFirstTimeoutTime" INT 0 65535;
BA_DEF_DEF_  "GenMsgStartDelayTime" 0;
BA_DEF_DEF_  "GenMsgDelayTime" 0;
BA_DEF_DEF_  "GenMsgNrOfRepetition" 0;
BA_DEF_DEF_  "GenMsgCycleTimeFast" 0;
BA_DEF_DEF_  "GenMsgCycleTime" 0;
BA_DEF_DEF_  "GenMsgSendType" "Cyclic";
BA_DEF_DEF_  "GenSigStartValue" 0;
BA_DEF_DEF_  "GenSigCycleTimeActive" 0;
BA_DEF_DEF_  "GenSigCycleTime" 0;
BA_DEF_DEF_  "GenSigSendType" "Cyclic";
BA_DEF_DEF_  "Baudrate" 500000;
BA_DEF_DEF_  "NmType" "";
BA_DEF_DEF_  "Manufacturer" "VOLVO_AB";
BA_DEF_DEF_  "VersionYear" 0;
BA_DEF_DEF_  "VersionNumber" 0;
BA_DEF_DEF_  "VersionMonth" 1;
BA_DEF_DEF_  "VersionDay" 1;
BA_DEF_DEF_  "VFrameFormat" "ExtendedCAN";
BA_DEF_DEF_  "TpOwnSystemEcuNumber" 0;
BA_DEF_DEF_  "TpJ1939VarDlc" "No";
BA_DEF_DEF_  "SigType" "Default";
BA_DEF_DEF_  "SeToolVersion_SIGNAL" "";
BA_DEF_DEF_  "SeToolUniqueID_SIGNAL" "";
BA_DEF_DEF_  "SeToolOwnerSigGroup_SIGNAL" "";
BA_DEF_DEF_  "SeToolOwnerSigGroupID_SIGNAL" "";
BA_DEF_DEF_  "SeToolName_SIGNAL" "";
BA_DEF_DEF_  "SeToolItemID_SIGNAL" "";
BA_DEF_DEF_  "SeToolAncestorID_SIGNAL" "";
BA_DEF_DEF_  "ReRoutJ1939ToCom" "No";
BA_DEF_DEF_  "ProtocolType" "";
BA_DEF_DEF_  "Platform_VMCU1_Sig" "No";
BA_DEF_DEF_  "NmStationAddress" 254;
BA_DEF_DEF_  "NmJ1939IdentityNumber" 0;
BA_DEF_DEF_  "NmAsrWaitBusSleepTime" 750;
BA_DEF_DEF_  "NmAsrTimeoutTime" 5000;
BA_DEF_DEF_  "NmAsrRepeatMessageTime" 300;
BA_DEF_DEF_  "NmAsrNodeIdentifier" 0;
BA_DEF_DEF_  "NmAsrNode" "Yes";
BA_DEF_DEF_  "NmAsrMessageCount" 256;
BA_DEF_DEF_  "NmAsrCanMsgCycleTime" 200;
BA_DEF_DEF_  "NmAsrBaseAddress" 486506496;
BA_DEF_DEF_  "NeedsUpdateBit" "No";
BA_DEF_DEF_  "IsOBDrelevant" "No";
BA_DEF_DEF_  "GenSigMaxLatency" 0;
BA_DEF_DEF_  "GenSigILSupport" "Yes";
BA_DEF_DEF_  "GenMsgILSupport" "Yes";
BA_DEF_DEF_  "E2EProfile" "none";
BA_DEF_DEF_  "E2EP05WindowSize" 5;
BA_DEF_DEF_  "E2EP05ProfileName" "PROFILE_05";
BA_DEF_DEF_  "E2EP05MinOkStateValid" 1;
BA_DEF_DEF_  "E2EP05MinOkStateInvalid" 3;
BA_DEF_DEF_  "E2EP05MinOkStateInit" 1;
BA_DEF_DEF_  "E2EP05MaxErrorStateValid" 3;
BA_DEF_DEF_  "E2EP05MaxErrorStateInvalid" 1;
BA_DEF_DEF_  "E2EP05MaxErrorStateInit" 2;
BA_DEF_DEF_  "E2EP05MaxDeltaCounter" 3;
BA_DEF_DEF_  "E2EP01WindowSize" 5;
BA_DEF_DEF_  "E2EP01SyncCounterInit" 1;
BA_DEF_DEF_  "E2EP01ProfileName" "PROFILE_01";
BA_DEF_DEF_  "E2EP01MinOkStateValid" 1;
BA_DEF_DEF_  "E2EP01MinOkStateInvalid" 3;
BA_DEF_DEF_  "E2EP01MinOkStateInit" 1;
BA_DEF_DEF_  "E2EP01MaxNoNewOrRepeatedData" 5;
BA_DEF_DEF_  "E2EP01MaxErrorStateValid" 3;
BA_DEF_DEF_  "E2EP01MaxErrorStateInvalid" 1;
BA_DEF_DEF_  "E2EP01MaxErrorStateInit" 2;
BA_DEF_DEF_  "E2EP01MaxDeltaCounter" 3;
BA_DEF_DEF_  "E2EP01DataIdMode" "all16Bit";
BA_DEF_DEF_  "E2EP01CounterOffset" 8;
BA_DEF_DEF_  "E2EDataLength" 0;
BA_DEF_DEF_  "E2EDataId" 0;
BA_DEF_DEF_  "DiagnosticClientAddress" 0;
BA_DEF_DEF_  "DiagUUDTResponse" "No";
BA_DEF_DEF_  "DiagState" "No";
BA_DEF_DEF_  "DiagRole" "None";
BA_DEF_DEF_  "DiagResponse" "No";
BA_DEF_DEF_  "DiagRequest" "No";
BA_DEF_DEF_  "DiagConnection" 0;
BA_DEF_DEF_  "DBName" "";
BA_DEF_DEF_  "CanTpFcFrameId" 2147483647;
BA_DEF_DEF_  "CanTpBs" 255;
BA_DEF_DEF_  "BusType" "";
BA_DEF_DEF_REL_ "GenSigTimeoutTime" 0;
BA_DEF_DEF_REL_ "GenSigFirstTimeoutTime" 0;
BA_DEF_DEF_  "SystemSignalLongSymbol" "";
BA_ "BusType" "CAN";
BA_ "ProtocolType" "J1939";
BA_ "VersionDay" 27;
BA_ "VersionMonth" 2;
BA_ "VersionNumber" 1;
BA_ "VersionYear" 23;
BA_ "DBName" "CAN01";
BA_ "DiagRole" BU_ VCM 3;
BA_ "DiagnosticClientAddress" BU_ VCM 244;
BA_ "IsOBDrelevant" BU_ VCM 1;
BA_ "TpOwnSystemEcuNumber" BU_ VCM 36;
BA_ "NmAsrNode" BU_ VCM 0;
BA_ "NmAsrNodeIdentifier" BU_ VCM 36;
BA_ "NmJ1939IdentityNumber" BU_ VCM 17;
BA_ "NmStationAddress" BU_ VCM 17;
BA_ "TpOwnSystemEcuNumber" BU_ TCM 24;
BA_ "NmAsrNode" BU_ TCM 0;
BA_ "NmAsrNodeIdentifier" BU_ TCM 24;
BA_ "NmJ1939IdentityNumber" BU_ TCM 3;
BA_ "NmStationAddress" BU_ TCM 3;
BA_ "ReRoutJ1939ToCom" BU_ TCM 1;
BA_ "IsOBDrelevant" BU_ ECM 1;
BA_ "TpOwnSystemEcuNumber" BU_ ECM 16;
BA_ "NmAsrNode" BU_ ECM 0;
BA_ "NmAsrNodeIdentifier" BU_ ECM 16;
BA_ "NmStationAddress" BU_ ECM 0;
BA_ "ReRoutJ1939ToCom" BU_ ECM 1;
BA_ "TpOwnSystemEcuNumber" BU_ EBS 40;
BA_ "NmAsrNode" BU_ EBS 0;
BA_ "NmAsrNodeIdentifier" BU_ EBS 40;
BA_ "NmJ1939IdentityNumber" BU_ EBS 11;
BA_ "NmStationAddress" BU_ EBS 11;
BA_ "IsOBDrelevant" BU_ ACM 1;
BA_ "TpOwnSystemEcuNumber" BU_ ACM 17;
BA_ "NmAsrNode" BU_ ACM 0;
BA_ "NmAsrNodeIdentifier" BU_ ACM 17;
BA_ "NmJ1939IdentityNumber" BU_ ACM 61;
BA_ "NmStationAddress" BU_ ACM 61;
BA_ "ReRoutJ1939ToCom" BU_ ACM 1;
BA_ "GenMsgSendType" BO_ 2349075203 8;
BA_ "GenMsgDelayTime" BO_ 2349075203 15;
BA_ "VFrameFormat" BO_ 2349075203 3;
BA_ "GenMsgSendType" BO_ 2349075200 8;
BA_ "GenMsgDelayTime" BO_ 2349075200 15;
BA_ "VFrameFormat" BO_ 2349075200 3;
BA_ "GenMsgSendType" BO_ 2349075373 8;
BA_ "GenMsgDelayTime" BO_ 2349075373 15;
BA_ "VFrameFormat" BO_ 2349075373 3;
BA_ "GenMsgCycleTime" BO_ 2566848256 10000;
BA_ "GenMsgStartDelayTime" BO_ 2566848256 2660;
BA_ "VFrameFormat" BO_ 2566848256 3;
BA_ "GenMsgCycleTime" BO_ 2566845201 250;
BA_ "GenMsgStartDelayTime" BO_ 2566845201 50;
BA_ "VFrameFormat" BO_ 2566845201 3;
BA_ "GenMsgCycleTime" BO_ 2566881297 100;
BA_ "GenMsgStartDelayTime" BO_ 2566881297 25;
BA_ "VFrameFormat" BO_ 2566881297 3;
BA_ "GenMsgCycleTime" BO_ 2566897681 500;
BA_ "GenMsgStartDelayTime" BO_ 2566897681 230;
BA_ "VFrameFormat" BO_ 2566897681 3;
BA_ "GenMsgCycleTime" BO_ 2365535249 50;
BA_ "GenMsgStartDelayTime" BO_ 2365535249 30;
BA_ "VFrameFormat" BO_ 2365535249 3;
BA_ "GenMsgCycleTime" BO_ 2499788567 75;
BA_ "GenMsgStartDelayTime" BO_ 2499788567 15;
BA_ "VFrameFormat" BO_ 2499788567 3;
BA_ "GenMsgCycleTime" BO_ 2566899729 1000;
BA_ "GenMsgStartDelayTime" BO_ 2566899729 250;
BA_ "VFrameFormat" BO_ 2566899729 3;
BA_ "GenMsgCycleTime" BO_ 2566899473 1000;
BA_ "GenMsgStartDelayTime" BO_ 2566899473 225;
BA_ "VFrameFormat" BO_ 2566899473 3;
BA_ "GenMsgCycleTime" BO_ 2566899217 1000;
BA_ "GenMsgStartDelayTime" BO_ 2566899217 110;
BA_ "VFrameFormat" BO_ 2566899217 3;
BA_ "GenMsgCycleTime" BO_ 2499751697 100;
BA_ "GenMsgStartDelayTime" BO_ 2499751697 40;
BA_ "VFrameFormat" BO_ 2499751697 3;
BA_ "GenMsgCycleTime" BO_ 2566897425 500;
BA_ "GenMsgStartDelayTime" BO_ 2566897425 15;
BA_ "VFrameFormat" BO_ 2566897425 3;
BA_ "GenMsgCycleTime" BO_ 2298429457 10;
BA_ "GenMsgStartDelayTime" BO_ 2298429457 5;
BA_ "VFrameFormat" BO_ 2298429457 3;
BA_ "GenMsgCycleTime" BO_ 2566832401 1000;
BA_ "GenMsgStartDelayTime" BO_ 2566832401 335;
BA_ "VFrameFormat" BO_ 2566832401 3;
BA_ "GenMsgCycleTime" BO_ 2364541195 10;
BA_ "GenMsgStartDelayTime" BO_ 2364541195 5;
BA_ "VFrameFormat" BO_ 2364541195 3;
BA_ "GenMsgCycleTime" BO_ 2566803211 100;
BA_ "GenMsgStartDelayTime" BO_ 2566803211 55;
BA_ "VFrameFormat" BO_ 2566803211 3;
BA_ "VFrameFormat" BO_ 1791 0;
BA_ "GenMsgCycleTime" BO_ 1791 1000;
BA_ "GenMsgCycleTime" BO_ 2365524497 25;
BA_ "GenMsgStartDelayTime" BO_ 2365524497 10;
BA_ "VFrameFormat" BO_ 2365524497 3;
BA_ "DiagConnection" BO_ 2671902706 61992;
BA_ "DiagState" BO_ 2671902706 1;
BA_ "GenMsgILSupport" BO_ 2671902706 0;
BA_ "GenMsgSendType" BO_ 2671902706 8;
BA_ "VFrameFormat" BO_ 2671902706 3;
BA_ "DiagConnection" BO_ 2671902708 62719;
BA_ "DiagState" BO_ 2671902708 1;
BA_ "GenMsgILSupport" BO_ 2671902708 0;
BA_ "GenMsgSendType" BO_ 2671902708 8;
BA_ "VFrameFormat" BO_ 2671902708 3;
BA_ "GenMsgSendType" BO_ 2348814353 7;
BA_ "GenMsgCycleTimeFast" BO_ 2348814353 50;
BA_ "GenMsgNrOfRepetition" BO_ 2348814353 3;
BA_ "VFrameFormat" BO_ 2348814353 3;
BA_ "GenMsgSendType" BO_ 2348814339 7;
BA_ "GenMsgCycleTimeFast" BO_ 2348814339 50;
BA_ "GenMsgNrOfRepetition" BO_ 2348814339 3;
BA_ "VFrameFormat" BO_ 2348814339 3;
BA_ "GenMsgSendType" BO_ 2348814337 7;
BA_ "GenMsgCycleTimeFast" BO_ 2348814337 50;
BA_ "GenMsgNrOfRepetition" BO_ 2348814337 3;
BA_ "VFrameFormat" BO_ 2348814337 3;
BA_ "GenMsgSendType" BO_ 2348814336 7;
BA_ "GenMsgCycleTimeFast" BO_ 2348814336 50;
BA_ "GenMsgNrOfRepetition" BO_ 2348814336 3;
BA_ "VFrameFormat" BO_ 2348814336 3;
BA_ "GenMsgSendType" BO_ 2348814347 7;
BA_ "GenMsgCycleTimeFast" BO_ 2348814347 50;
BA_ "GenMsgNrOfRepetition" BO_ 2348814347 3;
BA_ "VFrameFormat" BO_ 2348814347 3;
BA_ "GenMsgSendType" BO_ 2348810257 7;
BA_ "GenMsgCycleTimeFast" BO_ 2348810257 20;
BA_ "GenMsgNrOfRepetition" BO_ 2348810257 3;
BA_ "VFrameFormat" BO_ 2348810257 3;
BA_ "GenMsgSendType" BO_ 2348810288 7;
BA_ "GenMsgCycleTimeFast" BO_ 2348810288 20;
BA_ "GenMsgNrOfRepetition" BO_ 2348810288 3;
BA_ "VFrameFormat" BO_ 2348810288 3;
BA_ "GenMsgSendType" BO_ 2348810243 7;
BA_ "GenMsgCycleTimeFast" BO_ 2348810243 10;
BA_ "GenMsgNrOfRepetition" BO_ 2348810243 3;
BA_ "VFrameFormat" BO_ 2348810243 3;
BA_ "GenMsgSendType" BO_ 2348810251 7;
BA_ "GenMsgCycleTimeFast" BO_ 2348810251 10;
BA_ "GenMsgNrOfRepetition" BO_ 2348810251 3;
BA_ "VFrameFormat" BO_ 2348810251 3;
BA_ "GenMsgSendType" BO_ 2348810413 7;
BA_ "GenMsgCycleTimeFast" BO_ 2348810413 20;
BA_ "GenMsgNrOfRepetition" BO_ 2348810413 3;
BA_ "VFrameFormat" BO_ 2348810413 3;
BA_ "GenSigSendType" SG_ 2349075203 XBRTECU_EBIMode 1;
BA_ "GenSigCycleTime" SG_ 2349075203 XBRTECU_EBIMode 100;
BA_ "GenSigCycleTimeActive" SG_ 2349075203 XBRTECU_EBIMode 100;
BA_ "GenSigStartValue" SG_ 2349075203 XBRTECU_EBIMode 3;
BA_ "SeToolAncestorID_SIGNAL" SG_ 2349075203 XBRTECU_EBIMode "x0000001D0410D0BE";
BA_ "SeToolItemID_SIGNAL" SG_ 2349075203 XBRTECU_EBIMode "x0000001D0410D0BE";
BA_ "SeToolName_SIGNAL" SG_ 2349075203 XBRTECU_EBIMode "EBIMode";
BA_ "SeToolOwnerSigGroupID_SIGNAL" SG_ 2349075203 XBRTECU_EBIMode "x0000001D043D6E5C";
BA_ "SeToolOwnerSigGroup_SIGNAL" SG_ 2349075203 XBRTECU_EBIMode "XBRTECU";
BA_ "SeToolVersion_SIGNAL" SG_ 2349075203 XBRTECU_EBIMode "1";
BA_ "GenSigSendType" SG_ 2349075203 XBRTECU_MsgCounter 1;
BA_ "GenSigCycleTime" SG_ 2349075203 XBRTECU_MsgCounter 100;
BA_ "GenSigCycleTimeActive" SG_ 2349075203 XBRTECU_MsgCounter 100;
BA_ "SeToolAncestorID_SIGNAL" SG_ 2349075203 XBRTECU_MsgCounter "x0000001D043103C8";
BA_ "SeToolItemID_SIGNAL" SG_ 2349075203 XBRTECU_MsgCounter "x0000001D043103C8";
BA_ "SeToolName_SIGNAL" SG_ 2349075203 XBRTECU_MsgCounter "MsgCounter";
BA_ "SeToolOwnerSigGroupID_SIGNAL" SG_ 2349075203 XBRTECU_MsgCounter "x0000001D043D6E5C";
BA_ "SeToolOwnerSigGroup_SIGNAL" SG_ 2349075203 XBRTECU_MsgCounter "XBRTECU";
BA_ "SeToolVersion_SIGNAL" SG_ 2349075203 XBRTECU_MsgCounter "1";
BA_ "GenSigSendType" SG_ 2349075203 XBRTECU_MsgChecksum 1;
BA_ "GenSigCycleTime" SG_ 2349075203 XBRTECU_MsgChecksum 100;
BA_ "GenSigCycleTimeActive" SG_ 2349075203 XBRTECU_MsgChecksum 100;
BA_ "SeToolAncestorID_SIGNAL" SG_ 2349075203 XBRTECU_MsgChecksum "x0000001D043103C0";
BA_ "SeToolItemID_SIGNAL" SG_ 2349075203 XBRTECU_MsgChecksum "x0000001D043103C0";
BA_ "SeToolName_SIGNAL" SG_ 2349075203 XBRTECU_MsgChecksum "MsgChecksum";
BA_ "SeToolOwnerSigGroupID_SIGNAL" SG_ 2349075203 XBRTECU_MsgChecksum "x0000001D043D6E5C";
BA_ "SeToolOwnerSigGroup_SIGNAL" SG_ 2349075203 XBRTECU_MsgChecksum "XBRTECU";
BA_ "SeToolVersion_SIGNAL" SG_ 2349075203 XBRTECU_MsgChecksum "1";
BA_ "GenSigSendType" SG_ 2349075203 XBRTECU_ControlMode 1;
BA_ "GenSigCycleTime" SG_ 2349075203 XBRTECU_ControlMode 100;
BA_ "GenSigCycleTimeActive" SG_ 2349075203 XBRTECU_ControlMode 100;
BA_ "GenSigStartValue" SG_ 2349075203 XBRTECU_ControlMode 3;
BA_ "SeToolAncestorID_SIGNAL" SG_ 2349075203 XBRTECU_ControlMode "x0000001D0415DF83";
BA_ "SeToolItemID_SIGNAL" SG_ 2349075203 XBRTECU_ControlMode "x0000001D0415DF83";
BA_ "SeToolName_SIGNAL" SG_ 2349075203 XBRTECU_ControlMode "ControlMode";
BA_ "SeToolOwnerSigGroupID_SIGNAL" SG_ 2349075203 XBRTECU_ControlMode "x0000001D043D6E5C";
BA_ "SeToolOwnerSigGroup_SIGNAL" SG_ 2349075203 XBRTECU_ControlMode "XBRTECU";
BA_ "SeToolVersion_SIGNAL" SG_ 2349075203 XBRTECU_ControlMode "1";
BA_ "GenSigSendType" SG_ 2349075203 XBRTECU_ExtAccelDemand 1;
BA_ "GenSigCycleTime" SG_ 2349075203 XBRTECU_ExtAccelDemand 100;
BA_ "GenSigCycleTimeActive" SG_ 2349075203 XBRTECU_ExtAccelDemand 100;
BA_ "GenSigStartValue" SG_ 2349075203 XBRTECU_ExtAccelDemand 65535;
BA_ "SeToolAncestorID_SIGNAL" SG_ 2349075203 XBRTECU_ExtAccelDemand "x0000001D0410D936";
BA_ "SeToolItemID_SIGNAL" SG_ 2349075203 XBRTECU_ExtAccelDemand "x0000001D0410D936";
BA_ "SeToolName_SIGNAL" SG_ 2349075203 XBRTECU_ExtAccelDemand "ExtAccelDemand";
BA_ "SeToolOwnerSigGroupID_SIGNAL" SG_ 2349075203 XBRTECU_ExtAccelDemand "x0000001D043D6E5C";
BA_ "SeToolOwnerSigGroup_SIGNAL" SG_ 2349075203 XBRTECU_ExtAccelDemand "XBRTECU";
BA_ "SeToolVersion_SIGNAL" SG_ 2349075203 XBRTECU_ExtAccelDemand "1";
BA_ "GenSigSendType" SG_ 2349075203 XBRTECU_Urgency 1;
BA_ "GenSigCycleTime" SG_ 2349075203 XBRTECU_Urgency 100;
BA_ "GenSigCycleTimeActive" SG_ 2349075203 XBRTECU_Urgency 100;
BA_ "GenSigStartValue" SG_ 2349075203 XBRTECU_Urgency 255;
BA_ "SeToolAncestorID_SIGNAL" SG_ 2349075203 XBRTECU_Urgency "x0000001D04162231";
BA_ "SeToolItemID_SIGNAL" SG_ 2349075203 XBRTECU_Urgency "x0000001D04162231";
BA_ "SeToolName_SIGNAL" SG_ 2349075203 XBRTECU_Urgency "Urgency";
BA_ "SeToolOwnerSigGroupID_SIGNAL" SG_ 2349075203 XBRTECU_Urgency "x0000001D043D6E5C";
BA_ "SeToolOwnerSigGroup_SIGNAL" SG_ 2349075203 XBRTECU_Urgency "XBRTECU";
BA_ "SeToolVersion_SIGNAL" SG_ 2349075203 XBRTECU_Urgency "1";
BA_ "GenSigSendType" SG_ 2349075203 XBRTECU_Priority 1;
BA_ "GenSigCycleTime" SG_ 2349075203 XBRTECU_Priority 100;
BA_ "GenSigCycleTimeActive" SG_ 2349075203 XBRTECU_Priority 100;
BA_ "GenSigStartValue" SG_ 2349075203 XBRTECU_Priority 3;
BA_ "SeToolAncestorID_SIGNAL" SG_ 2349075203 XBRTECU_Priority "x0000001D0415DF81";
BA_ "SeToolItemID_SIGNAL" SG_ 2349075203 XBRTECU_Priority "x0000001D0415DF81";
BA_ "SeToolName_SIGNAL" SG_ 2349075203 XBRTECU_Priority "Priority";
BA_ "SeToolOwnerSigGroupID_SIGNAL" SG_ 2349075203 XBRTECU_Priority "x0000001D043D6E5C";
BA_ "SeToolOwnerSigGroup_SIGNAL" SG_ 2349075203 XBRTECU_Priority "XBRTECU";
BA_ "SeToolVersion_SIGNAL" SG_ 2349075203 XBRTECU_Priority "1";
BA_ "GenSigSendType" SG_ 2349075200 XBREMS_ExtAccelDemand 1;
BA_ "GenSigCycleTime" SG_ 2349075200 XBREMS_ExtAccelDemand 100;
BA_ "GenSigCycleTimeActive" SG_ 2349075200 XBREMS_ExtAccelDemand 100;
BA_ "GenSigStartValue" SG_ 2349075200 XBREMS_ExtAccelDemand 65535;
BA_ "GenSigSendType" SG_ 2349075200 XBREMS_Urgency 1;
BA_ "GenSigCycleTime" SG_ 2349075200 XBREMS_Urgency 100;
BA_ "GenSigCycleTimeActive" SG_ 2349075200 XBREMS_Urgency 100;
BA_ "GenSigStartValue" SG_ 2349075200 XBREMS_Urgency 255;
BA_ "GenSigSendType" SG_ 2349075200 XBREMS_EBIMode 1;
BA_ "GenSigCycleTime" SG_ 2349075200 XBREMS_EBIMode 100;
BA_ "GenSigCycleTimeActive" SG_ 2349075200 XBREMS_EBIMode 100;
BA_ "GenSigStartValue" SG_ 2349075200 XBREMS_EBIMode 3;
BA_ "GenSigSendType" SG_ 2349075200 XBREMS_MsgCounter 1;
BA_ "GenSigCycleTime" SG_ 2349075200 XBREMS_MsgCounter 100;
BA_ "GenSigCycleTimeActive" SG_ 2349075200 XBREMS_MsgCounter 100;
BA_ "GenSigStartValue" SG_ 2349075200 XBREMS_MsgCounter 15;
BA_ "GenSigSendType" SG_ 2349075200 XBREMS_Priority 1;
BA_ "GenSigCycleTime" SG_ 2349075200 XBREMS_Priority 100;
BA_ "GenSigCycleTimeActive" SG_ 2349075200 XBREMS_Priority 100;
BA_ "GenSigStartValue" SG_ 2349075200 XBREMS_Priority 3;
BA_ "GenSigSendType" SG_ 2349075200 XBREMS_MsgChecksum 1;
BA_ "GenSigCycleTime" SG_ 2349075200 XBREMS_MsgChecksum 100;
BA_ "GenSigCycleTimeActive" SG_ 2349075200 XBREMS_MsgChecksum 100;
BA_ "GenSigStartValue" SG_ 2349075200 XBREMS_MsgChecksum 15;
BA_ "GenSigSendType" SG_ 2349075200 XBREMS_ControlMode 1;
BA_ "GenSigCycleTime" SG_ 2349075200 XBREMS_ControlMode 100;
BA_ "GenSigCycleTimeActive" SG_ 2349075200 XBREMS_ControlMode 100;
BA_ "GenSigStartValue" SG_ 2349075200 XBREMS_ControlMode 3;
BA_ "GenSigSendType" SG_ 2349075373 XBRDACU_Priority 1;
BA_ "GenSigCycleTime" SG_ 2349075373 XBRDACU_Priority 100;
BA_ "GenSigCycleTimeActive" SG_ 2349075373 XBRDACU_Priority 100;
BA_ "GenSigStartValue" SG_ 2349075373 XBRDACU_Priority 3;
BA_ "SeToolAncestorID_SIGNAL" SG_ 2349075373 XBRDACU_Priority "x0000001D0415DF81";
BA_ "SeToolItemID_SIGNAL" SG_ 2349075373 XBRDACU_Priority "x0000001D0415DF81";
BA_ "SeToolName_SIGNAL" SG_ 2349075373 XBRDACU_Priority "Priority";
BA_ "SeToolOwnerSigGroupID_SIGNAL" SG_ 2349075373 XBRDACU_Priority "x0000001D043D6E8E";
BA_ "SeToolOwnerSigGroup_SIGNAL" SG_ 2349075373 XBRDACU_Priority "XBRDACU";
BA_ "SeToolVersion_SIGNAL" SG_ 2349075373 XBRDACU_Priority "1";
BA_ "GenSigSendType" SG_ 2349075373 XBRDACU_MsgChecksum 1;
BA_ "GenSigCycleTime" SG_ 2349075373 XBRDACU_MsgChecksum 100;
BA_ "GenSigCycleTimeActive" SG_ 2349075373 XBRDACU_MsgChecksum 100;
BA_ "SeToolAncestorID_SIGNAL" SG_ 2349075373 XBRDACU_MsgChecksum "x0000001D043103C0";
BA_ "SeToolItemID_SIGNAL" SG_ 2349075373 XBRDACU_MsgChecksum "x0000001D043103C0";
BA_ "SeToolName_SIGNAL" SG_ 2349075373 XBRDACU_MsgChecksum "MsgChecksum";
BA_ "SeToolOwnerSigGroupID_SIGNAL" SG_ 2349075373 XBRDACU_MsgChecksum "x0000001D043D6E8E";
BA_ "SeToolOwnerSigGroup_SIGNAL" SG_ 2349075373 XBRDACU_MsgChecksum "XBRDACU";
BA_ "SeToolVersion_SIGNAL" SG_ 2349075373 XBRDACU_MsgChecksum "1";
BA_ "GenSigSendType" SG_ 2349075373 XBRDACU_MsgCounter 1;
BA_ "GenSigCycleTime" SG_ 2349075373 XBRDACU_MsgCounter 100;
BA_ "GenSigCycleTimeActive" SG_ 2349075373 XBRDACU_MsgCounter 100;
BA_ "SeToolAncestorID_SIGNAL" SG_ 2349075373 XBRDACU_MsgCounter "x0000001D043103C8";
BA_ "SeToolItemID_SIGNAL" SG_ 2349075373 XBRDACU_MsgCounter "x0000001D043103C8";
BA_ "SeToolName_SIGNAL" SG_ 2349075373 XBRDACU_MsgCounter "MsgCounter";
BA_ "SeToolOwnerSigGroupID_SIGNAL" SG_ 2349075373 XBRDACU_MsgCounter "x0000001D043D6E8E";
BA_ "SeToolOwnerSigGroup_SIGNAL" SG_ 2349075373 XBRDACU_MsgCounter "XBRDACU";
BA_ "SeToolVersion_SIGNAL" SG_ 2349075373 XBRDACU_MsgCounter "1";
BA_ "GenSigSendType" SG_ 2349075373 XBRDACU_EBIMode 1;
BA_ "GenSigCycleTime" SG_ 2349075373 XBRDACU_EBIMode 100;
BA_ "GenSigCycleTimeActive" SG_ 2349075373 XBRDACU_EBIMode 100;
BA_ "GenSigStartValue" SG_ 2349075373 XBRDACU_EBIMode 3;
BA_ "SeToolAncestorID_SIGNAL" SG_ 2349075373 XBRDACU_EBIMode "x0000001D0410D0BE";
BA_ "SeToolItemID_SIGNAL" SG_ 2349075373 XBRDACU_EBIMode "x0000001D0410D0BE";
BA_ "SeToolName_SIGNAL" SG_ 2349075373 XBRDACU_EBIMode "EBIMode";
BA_ "SeToolOwnerSigGroupID_SIGNAL" SG_ 2349075373 XBRDACU_EBIMode "x0000001D043D6E8E";
BA_ "SeToolOwnerSigGroup_SIGNAL" SG_ 2349075373 XBRDACU_EBIMode "XBRDACU";
BA_ "SeToolVersion_SIGNAL" SG_ 2349075373 XBRDACU_EBIMode "1";
BA_ "GenSigSendType" SG_ 2349075373 XBRDACU_ExtAccelDemand 1;
BA_ "GenSigCycleTime" SG_ 2349075373 XBRDACU_ExtAccelDemand 100;
BA_ "GenSigCycleTimeActive" SG_ 2349075373 XBRDACU_ExtAccelDemand 100;
BA_ "GenSigStartValue" SG_ 2349075373 XBRDACU_ExtAccelDemand 65535;
BA_ "SeToolAncestorID_SIGNAL" SG_ 2349075373 XBRDACU_ExtAccelDemand "x0000001D0410D936";
BA_ "SeToolItemID_SIGNAL" SG_ 2349075373 XBRDACU_ExtAccelDemand "x0000001D0410D936";
BA_ "SeToolName_SIGNAL" SG_ 2349075373 XBRDACU_ExtAccelDemand "ExtAccelDemand";
BA_ "SeToolOwnerSigGroupID_SIGNAL" SG_ 2349075373 XBRDACU_ExtAccelDemand "x0000001D043D6E8E";
BA_ "SeToolOwnerSigGroup_SIGNAL" SG_ 2349075373 XBRDACU_ExtAccelDemand "XBRDACU";
BA_ "SeToolVersion_SIGNAL" SG_ 2349075373 XBRDACU_ExtAccelDemand "1";
BA_ "GenSigSendType" SG_ 2349075373 XBRDACU_Urgency 1;
BA_ "GenSigCycleTime" SG_ 2349075373 XBRDACU_Urgency 100;
BA_ "GenSigCycleTimeActive" SG_ 2349075373 XBRDACU_Urgency 100;
BA_ "GenSigStartValue" SG_ 2349075373 XBRDACU_Urgency 255;
BA_ "SeToolAncestorID_SIGNAL" SG_ 2349075373 XBRDACU_Urgency "x0000001D04162231";
BA_ "SeToolItemID_SIGNAL" SG_ 2349075373 XBRDACU_Urgency "x0000001D04162231";
BA_ "SeToolName_SIGNAL" SG_ 2349075373 XBRDACU_Urgency "Urgency";
BA_ "SeToolOwnerSigGroupID_SIGNAL" SG_ 2349075373 XBRDACU_Urgency "x0000001D043D6E8E";
BA_ "SeToolOwnerSigGroup_SIGNAL" SG_ 2349075373 XBRDACU_Urgency "XBRDACU";
BA_ "SeToolVersion_SIGNAL" SG_ 2349075373 XBRDACU_Urgency "1";
BA_ "GenSigSendType" SG_ 2349075373 XBRDACU_ControlMode 1;
BA_ "GenSigCycleTime" SG_ 2349075373 XBRDACU_ControlMode 100;
BA_ "GenSigCycleTimeActive" SG_ 2349075373 XBRDACU_ControlMode 100;
BA_ "GenSigStartValue" SG_ 2349075373 XBRDACU_ControlMode 3;
BA_ "SeToolAncestorID_SIGNAL" SG_ 2349075373 XBRDACU_ControlMode "x0000001D0415DF83";
BA_ "SeToolItemID_SIGNAL" SG_ 2349075373 XBRDACU_ControlMode "x0000001D0415DF83";
BA_ "SeToolName_SIGNAL" SG_ 2349075373 XBRDACU_ControlMode "ControlMode";
BA_ "SeToolOwnerSigGroupID_SIGNAL" SG_ 2349075373 XBRDACU_ControlMode "x0000001D043D6E8E";
BA_ "SeToolOwnerSigGroup_SIGNAL" SG_ 2349075373 XBRDACU_ControlMode "XBRDACU";
BA_ "SeToolVersion_SIGNAL" SG_ 2349075373 XBRDACU_ControlMode "1";
BA_ "GenSigCycleTime" SG_ 2566848256 WaterInFuelAlarm 100;
BA_ "GenSigCycleTimeActive" SG_ 2566848256 WaterInFuelAlarm 100;
BA_ "GenSigStartValue" SG_ 2566848256 WaterInFuelAlarm 3;
BA_ "GenSigCycleTime" SG_ 2566845201 VehiclePosSAE_Longitude 100;
BA_ "GenSigCycleTimeActive" SG_ 2566845201 VehiclePosSAE_Longitude 100;
BA_ "GenSigStartValue" SG_ 2566845201 VehiclePosSAE_Longitude 4294967295;
BA_ "GenSigCycleTime" SG_ 2566845201 VehiclePosSAE_Latitude 100;
BA_ "GenSigCycleTimeActive" SG_ 2566845201 VehiclePosSAE_Latitude 100;
BA_ "GenSigStartValue" SG_ 2566845201 VehiclePosSAE_Latitude 4294967295;
BA_ "GenSigCycleTime" SG_ 2566881297 WheelBasedVehicleSpd_CRC_ISig_1 100;
BA_ "GenSigCycleTimeActive" SG_ 2566881297 WheelBasedVehicleSpd_CRC_ISig_1 100;
BA_ "GenSigStartValue" SG_ 2566881297 WheelBasedVehicleSpd_CRC_ISig_1 255;
BA_ "E2EDataId" SG_ 2566881297 WheelBasedVehicleSpd_CRC_ISig_1 178;
BA_ "E2EDataLength" SG_ 2566881297 WheelBasedVehicleSpd_CRC_ISig_1 32;
BA_ "E2EProfile" SG_ 2566881297 WheelBasedVehicleSpd_CRC_ISig_1 "P01";
BA_ "GenSigCycleTime" SG_ 2566881297 WheelBasedVehicleSpd_SqC_ISig_1 100;
BA_ "GenSigCycleTimeActive" SG_ 2566881297 WheelBasedVehicleSpd_SqC_ISig_1 100;
BA_ "GenSigStartValue" SG_ 2566881297 WheelBasedVehicleSpd_SqC_ISig_1 14;
BA_ "GenSigCycleTime" SG_ 2566881297 WheelBasedVehicleSpd_Value_ISig_ 100;
BA_ "GenSigCycleTimeActive" SG_ 2566881297 WheelBasedVehicleSpd_Value_ISig_ 100;
BA_ "GenSigStartValue" SG_ 2566881297 WheelBasedVehicleSpd_Value_ISig_ 65535;
BA_ "SystemSignalLongSymbol" SG_ 2566881297 WheelBasedVehicleSpd_Value_ISig_ "WheelBasedVehicleSpd_Value_ISig_1";
BA_ "GenSigCycleTime" SG_ 2566881297 EHRASPowerConsIndex 100;
BA_ "GenSigCycleTimeActive" SG_ 2566881297 EHRASPowerConsIndex 100;
BA_ "GenSigStartValue" SG_ 2566881297 EHRASPowerConsIndex 255;
BA_ "Platform_VMCU1_Sig" SG_ 2566881297 EHRASPowerConsIndex 1;
BA_ "GenSigCycleTime" SG_ 2566897681 OBDUTCTime_Month 100;
BA_ "GenSigCycleTimeActive" SG_ 2566897681 OBDUTCTime_Month 100;
BA_ "GenSigStartValue" SG_ 2566897681 OBDUTCTime_Month 255;
BA_ "GenSigCycleTime" SG_ 2566897681 OBDUTCTime_Seconds 100;
BA_ "GenSigCycleTimeActive" SG_ 2566897681 OBDUTCTime_Seconds 100;
BA_ "GenSigStartValue" SG_ 2566897681 OBDUTCTime_Seconds 255;
BA_ "GenSigCycleTime" SG_ 2566897681 OBDUTCTime_Year 100;
BA_ "GenSigCycleTimeActive" SG_ 2566897681 OBDUTCTime_Year 100;
BA_ "GenSigStartValue" SG_ 2566897681 OBDUTCTime_Year 255;
BA_ "GenSigCycleTime" SG_ 2566897681 OBDUTCTime_Hours 100;
BA_ "GenSigCycleTimeActive" SG_ 2566897681 OBDUTCTime_Hours 100;
BA_ "GenSigStartValue" SG_ 2566897681 OBDUTCTime_Hours 255;
BA_ "GenSigCycleTime" SG_ 2566897681 OBDUTCTime_Minutes 100;
BA_ "GenSigCycleTimeActive" SG_ 2566897681 OBDUTCTime_Minutes 100;
BA_ "GenSigStartValue" SG_ 2566897681 OBDUTCTime_Minutes 255;
BA_ "GenSigCycleTime" SG_ 2566897681 OBDUTCTime_Day 100;
BA_ "GenSigCycleTimeActive" SG_ 2566897681 OBDUTCTime_Day 100;
BA_ "GenSigStartValue" SG_ 2566897681 OBDUTCTime_Day 255;
BA_ "GenSigCycleTime" SG_ 2365535249 DrvAxlBrkPressure_SqC 100;
BA_ "GenSigCycleTimeActive" SG_ 2365535249 DrvAxlBrkPressure_SqC 100;
BA_ "GenSigStartValue" SG_ 2365535249 DrvAxlBrkPressure_SqC 14;
BA_ "GenSigCycleTime" SG_ 2365535249 DrvAxlBrkPressure_Rqst 100;
BA_ "GenSigCycleTimeActive" SG_ 2365535249 DrvAxlBrkPressure_Rqst 100;
BA_ "GenSigStartValue" SG_ 2365535249 DrvAxlBrkPressure_Rqst 255;
BA_ "GenSigCycleTime" SG_ 2365535249 TrailerBrkPressure_SqC 100;
BA_ "GenSigCycleTimeActive" SG_ 2365535249 TrailerBrkPressure_SqC 100;
BA_ "GenSigStartValue" SG_ 2365535249 TrailerBrkPressure_SqC 14;
BA_ "GenSigCycleTime" SG_ 2365535249 TrailerBrkPressure_Rqst 100;
BA_ "GenSigCycleTimeActive" SG_ 2365535249 TrailerBrkPressure_Rqst 100;
BA_ "GenSigStartValue" SG_ 2365535249 TrailerBrkPressure_Rqst 255;
BA_ "GenSigCycleTime" SG_ 2365535249 DrvAxlBrkPressure_CRC 100;
BA_ "GenSigCycleTimeActive" SG_ 2365535249 DrvAxlBrkPressure_CRC 100;
BA_ "GenSigStartValue" SG_ 2365535249 DrvAxlBrkPressure_CRC 255;
BA_ "E2EDataId" SG_ 2365535249 DrvAxlBrkPressure_CRC 16;
BA_ "E2EDataLength" SG_ 2365535249 DrvAxlBrkPressure_CRC 24;
BA_ "E2EProfile" SG_ 2365535249 DrvAxlBrkPressure_CRC "P01";
BA_ "GenSigCycleTime" SG_ 2365535249 TrailerBrkPressure_CRC 100;
BA_ "GenSigCycleTimeActive" SG_ 2365535249 TrailerBrkPressure_CRC 100;
BA_ "GenSigStartValue" SG_ 2365535249 TrailerBrkPressure_CRC 255;
BA_ "E2EDataId" SG_ 2365535249 TrailerBrkPressure_CRC 15;
BA_ "E2EDataLength" SG_ 2365535249 TrailerBrkPressure_CRC 24;
BA_ "E2EProfile" SG_ 2365535249 TrailerBrkPressure_CRC "P01";
BA_ "GenSigCycleTime" SG_ 2499788567 DrvrRetarderBrakeBlending_rqst_I 100;
BA_ "GenSigCycleTimeActive" SG_ 2499788567 DrvrRetarderBrakeBlending_rqst_I 100;
BA_ "GenSigStartValue" SG_ 2499788567 DrvrRetarderBrakeBlending_rqst_I 3;
BA_ "SystemSignalLongSymbol" SG_ 2499788567 DrvrRetarderBrakeBlending_rqst_I "DrvrRetarderBrakeBlending_rqst_ISig_1";
BA_ "GenSigCycleTime" SG_ 2499788567 Trailer2LiftAxle2PosReq 100;
BA_ "GenSigCycleTimeActive" SG_ 2499788567 Trailer2LiftAxle2PosReq 100;
BA_ "GenSigStartValue" SG_ 2499788567 Trailer2LiftAxle2PosReq 3;
BA_ "GenSigCycleTime" SG_ 2499788567 Trailer4LiftAxle2PosReq 100;
BA_ "GenSigCycleTimeActive" SG_ 2499788567 Trailer4LiftAxle2PosReq 100;
BA_ "GenSigStartValue" SG_ 2499788567 Trailer4LiftAxle2PosReq 3;
BA_ "GenSigCycleTime" SG_ 2499788567 GearLeverPositionBackup 100;
BA_ "GenSigCycleTimeActive" SG_ 2499788567 GearLeverPositionBackup 100;
BA_ "GenSigStartValue" SG_ 2499788567 GearLeverPositionBackup 15;
BA_ "GenSigCycleTime" SG_ 2499788567 Trailer2LiftAxle1PosReq 100;
BA_ "GenSigCycleTimeActive" SG_ 2499788567 Trailer2LiftAxle1PosReq 100;
BA_ "GenSigStartValue" SG_ 2499788567 Trailer2LiftAxle1PosReq 3;
BA_ "GenSigCycleTime" SG_ 2499788567 Trailer5LiftAxle2PosReq 100;
BA_ "GenSigCycleTimeActive" SG_ 2499788567 Trailer5LiftAxle2PosReq 100;
BA_ "GenSigStartValue" SG_ 2499788567 Trailer5LiftAxle2PosReq 3;
BA_ "GenSigCycleTime" SG_ 2499788567 GearLeverPos2Backup_CRC 100;
BA_ "GenSigCycleTimeActive" SG_ 2499788567 GearLeverPos2Backup_CRC 100;
BA_ "E2EDataId" SG_ 2499788567 GearLeverPos2Backup_CRC 12;
BA_ "E2EDataLength" SG_ 2499788567 GearLeverPos2Backup_CRC 16;
BA_ "E2EProfile" SG_ 2499788567 GearLeverPos2Backup_CRC "P01";
BA_ "GenSigCycleTime" SG_ 2499788567 DriverRetarderRequest_ISig_1 100;
BA_ "GenSigCycleTimeActive" SG_ 2499788567 DriverRetarderRequest_ISig_1 100;
BA_ "GenSigStartValue" SG_ 2499788567 DriverRetarderRequest_ISig_1 7;
BA_ "GenSigCycleTime" SG_ 2499788567 Trailer1LiftAxl2ePosReq 100;
BA_ "GenSigCycleTimeActive" SG_ 2499788567 Trailer1LiftAxl2ePosReq 100;
BA_ "GenSigStartValue" SG_ 2499788567 Trailer1LiftAxl2ePosReq 3;
BA_ "GenSigCycleTime" SG_ 2499788567 GearLeverPos2Backup_SqC 100;
BA_ "GenSigCycleTimeActive" SG_ 2499788567 GearLeverPos2Backup_SqC 100;
BA_ "GenSigCycleTime" SG_ 2499788567 Trailer1LiftAxle1PosReq 100;
BA_ "GenSigCycleTimeActive" SG_ 2499788567 Trailer1LiftAxle1PosReq 100;
BA_ "GenSigStartValue" SG_ 2499788567 Trailer1LiftAxle1PosReq 3;
BA_ "GenSigCycleTime" SG_ 2499788567 DrvrRetarderBrakeProgram_rqst_IS 100;
BA_ "GenSigCycleTimeActive" SG_ 2499788567 DrvrRetarderBrakeProgram_rqst_IS 100;
BA_ "GenSigStartValue" SG_ 2499788567 DrvrRetarderBrakeProgram_rqst_IS 3;
BA_ "SystemSignalLongSymbol" SG_ 2499788567 DrvrRetarderBrakeProgram_rqst_IS "DrvrRetarderBrakeProgram_rqst_ISig_1";
BA_ "GenSigCycleTime" SG_ 2499788567 Trailer4LiftAxle1PosReq 100;
BA_ "GenSigCycleTimeActive" SG_ 2499788567 Trailer4LiftAxle1PosReq 100;
BA_ "GenSigStartValue" SG_ 2499788567 Trailer4LiftAxle1PosReq 3;
BA_ "GenSigCycleTime" SG_ 2499788567 EHERearAxleSteeringFuncStatus 100;
BA_ "GenSigCycleTimeActive" SG_ 2499788567 EHERearAxleSteeringFuncStatus 100;
BA_ "GenSigStartValue" SG_ 2499788567 EHERearAxleSteeringFuncStatus 7;
BA_ "GenSigCycleTime" SG_ 2499788567 EHRearAxleSteeringFuncStatus 100;
BA_ "GenSigCycleTimeActive" SG_ 2499788567 EHRearAxleSteeringFuncStatus 100;
BA_ "GenSigStartValue" SG_ 2499788567 EHRearAxleSteeringFuncStatus 7;
BA_ "GenSigCycleTime" SG_ 2499788567 Trailer5LiftAxle1PosReq 100;
BA_ "GenSigCycleTimeActive" SG_ 2499788567 Trailer5LiftAxle1PosReq 100;
BA_ "GenSigStartValue" SG_ 2499788567 Trailer5LiftAxle1PosReq 3;
BA_ "GenSigCycleTime" SG_ 2499788567 Trailer3LiftAxle1PosReq 100;
BA_ "GenSigCycleTimeActive" SG_ 2499788567 Trailer3LiftAxle1PosReq 100;
BA_ "GenSigStartValue" SG_ 2499788567 Trailer3LiftAxle1PosReq 3;
BA_ "GenSigCycleTime" SG_ 2499788567 GearLeverPos2Backup_Rqst 100;
BA_ "GenSigCycleTimeActive" SG_ 2499788567 GearLeverPos2Backup_Rqst 100;
BA_ "GenSigStartValue" SG_ 2499788567 GearLeverPos2Backup_Rqst 15;
BA_ "GenSigCycleTime" SG_ 2499788567 Trailer3LiftAxle2PosReq 100;
BA_ "GenSigCycleTimeActive" SG_ 2499788567 Trailer3LiftAxle2PosReq 100;
BA_ "GenSigStartValue" SG_ 2499788567 Trailer3LiftAxle2PosReq 3;
BA_ "GenSigCycleTime" SG_ 2566899729 LoadCalibFail_WrongHeight 100;
BA_ "GenSigCycleTimeActive" SG_ 2566899729 LoadCalibFail_WrongHeight 100;
BA_ "GenSigStartValue" SG_ 2566899729 LoadCalibFail_WrongHeight 3;
BA_ "GenSigCycleTime" SG_ 2566899729 Trailer5CalibStoreReq_ScaleLoad 100;
BA_ "GenSigCycleTimeActive" SG_ 2566899729 Trailer5CalibStoreReq_ScaleLoad 100;
BA_ "GenSigStartValue" SG_ 2566899729 Trailer5CalibStoreReq_ScaleLoad 65535;
BA_ "GenSigCycleTime" SG_ 2566899729 LoadCalibrationFeedback_ISig_1 100;
BA_ "GenSigCycleTimeActive" SG_ 2566899729 LoadCalibrationFeedback_ISig_1 100;
BA_ "GenSigStartValue" SG_ 2566899729 LoadCalibrationFeedback_ISig_1 7;
BA_ "GenSigCycleTime" SG_ 2566899729 LoadCalibFail_InternalFailure 100;
BA_ "GenSigCycleTimeActive" SG_ 2566899729 LoadCalibFail_InternalFailure 100;
BA_ "GenSigStartValue" SG_ 2566899729 LoadCalibFail_InternalFailure 3;
BA_ "GenSigCycleTime" SG_ 2566899729 Trailer5CalibStoreReq_CalibType 100;
BA_ "GenSigCycleTimeActive" SG_ 2566899729 Trailer5CalibStoreReq_CalibType 100;
BA_ "GenSigStartValue" SG_ 2566899729 Trailer5CalibStoreReq_CalibType 3;
BA_ "GenSigCycleTime" SG_ 2566899729 LoadCalibFail_Range 100;
BA_ "GenSigCycleTimeActive" SG_ 2566899729 LoadCalibFail_Range 100;
BA_ "GenSigStartValue" SG_ 2566899729 LoadCalibFail_Range 3;
BA_ "GenSigCycleTime" SG_ 2566899729 LoadCalibFail_InMotion 100;
BA_ "GenSigCycleTimeActive" SG_ 2566899729 LoadCalibFail_InMotion 100;
BA_ "GenSigStartValue" SG_ 2566899729 LoadCalibFail_InMotion 3;
BA_ "GenSigCycleTime" SG_ 2566899729 Trailer5CalibStoreReq_AxleId 100;
BA_ "GenSigCycleTimeActive" SG_ 2566899729 Trailer5CalibStoreReq_AxleId 100;
BA_ "GenSigStartValue" SG_ 2566899729 Trailer5CalibStoreReq_AxleId 255;
BA_ "GenSigCycleTime" SG_ 2566899729 LoadCalibFail_WrongVM 100;
BA_ "GenSigCycleTimeActive" SG_ 2566899729 LoadCalibFail_WrongVM 100;
BA_ "GenSigStartValue" SG_ 2566899729 LoadCalibFail_WrongVM 3;
BA_ "GenSigCycleTime" SG_ 2566899729 LoadCalibFail_OutOfMemory 100;
BA_ "GenSigCycleTimeActive" SG_ 2566899729 LoadCalibFail_OutOfMemory 100;
BA_ "GenSigStartValue" SG_ 2566899729 LoadCalibFail_OutOfMemory 3;
BA_ "GenSigCycleTime" SG_ 2566899473 Trailer3CalibStoreReq_CalibType 100;
BA_ "GenSigCycleTimeActive" SG_ 2566899473 Trailer3CalibStoreReq_CalibType 100;
BA_ "GenSigStartValue" SG_ 2566899473 Trailer3CalibStoreReq_CalibType 3;
BA_ "GenSigCycleTime" SG_ 2566899473 Trailer4CalibStoreReq_CalibType 100;
BA_ "GenSigCycleTimeActive" SG_ 2566899473 Trailer4CalibStoreReq_CalibType 100;
BA_ "GenSigStartValue" SG_ 2566899473 Trailer4CalibStoreReq_CalibType 3;
BA_ "GenSigCycleTime" SG_ 2566899473 Trailer4CalibStoreReq_AxleId 100;
BA_ "GenSigCycleTimeActive" SG_ 2566899473 Trailer4CalibStoreReq_AxleId 100;
BA_ "GenSigStartValue" SG_ 2566899473 Trailer4CalibStoreReq_AxleId 255;
BA_ "GenSigCycleTime" SG_ 2566899473 Trailer3CalibStoreReq_AxleId 100;
BA_ "GenSigCycleTimeActive" SG_ 2566899473 Trailer3CalibStoreReq_AxleId 100;
BA_ "GenSigStartValue" SG_ 2566899473 Trailer3CalibStoreReq_AxleId 255;
BA_ "GenSigCycleTime" SG_ 2566899473 Trailer4CalibStoreReq_ScaleLoad 100;
BA_ "GenSigCycleTimeActive" SG_ 2566899473 Trailer4CalibStoreReq_ScaleLoad 100;
BA_ "GenSigStartValue" SG_ 2566899473 Trailer4CalibStoreReq_ScaleLoad 65535;
BA_ "GenSigCycleTime" SG_ 2566899473 Trailer3CalibStoreReq_ScaleLoad 100;
BA_ "GenSigCycleTimeActive" SG_ 2566899473 Trailer3CalibStoreReq_ScaleLoad 100;
BA_ "GenSigStartValue" SG_ 2566899473 Trailer3CalibStoreReq_ScaleLoad 65535;
BA_ "GenSigCycleTime" SG_ 2566899217 Trailer1CalibStoreReq_AxleId 100;
BA_ "GenSigCycleTimeActive" SG_ 2566899217 Trailer1CalibStoreReq_AxleId 100;
BA_ "GenSigStartValue" SG_ 2566899217 Trailer1CalibStoreReq_AxleId 255;
BA_ "GenSigCycleTime" SG_ 2566899217 Trailer1CalibStoreReq_ScaleLoad 100;
BA_ "GenSigCycleTimeActive" SG_ 2566899217 Trailer1CalibStoreReq_ScaleLoad 100;
BA_ "GenSigStartValue" SG_ 2566899217 Trailer1CalibStoreReq_ScaleLoad 65535;
BA_ "GenSigCycleTime" SG_ 2566899217 Trailer2CalibStoreReq_ScaleLoad 100;
BA_ "GenSigCycleTimeActive" SG_ 2566899217 Trailer2CalibStoreReq_ScaleLoad 100;
BA_ "GenSigStartValue" SG_ 2566899217 Trailer2CalibStoreReq_ScaleLoad 65535;
BA_ "GenSigCycleTime" SG_ 2566899217 Trailer1CalibStoreReq_CalibType 100;
BA_ "GenSigCycleTimeActive" SG_ 2566899217 Trailer1CalibStoreReq_CalibType 100;
BA_ "GenSigStartValue" SG_ 2566899217 Trailer1CalibStoreReq_CalibType 3;
BA_ "GenSigCycleTime" SG_ 2566899217 Trailer2CalibStoreReq_AxleId 100;
BA_ "GenSigCycleTimeActive" SG_ 2566899217 Trailer2CalibStoreReq_AxleId 100;
BA_ "GenSigStartValue" SG_ 2566899217 Trailer2CalibStoreReq_AxleId 255;
BA_ "GenSigCycleTime" SG_ 2566899217 Trailer2CalibStoreReq_CalibType 100;
BA_ "GenSigCycleTimeActive" SG_ 2566899217 Trailer2CalibStoreReq_CalibType 100;
BA_ "GenSigStartValue" SG_ 2566899217 Trailer2CalibStoreReq_CalibType 3;
BA_ "GenSigCycleTime" SG_ 2499751697 EngineStopReqBackup 100;
BA_ "GenSigCycleTimeActive" SG_ 2499751697 EngineStopReqBackup 100;
BA_ "GenSigStartValue" SG_ 2499751697 EngineStopReqBackup 3;
BA_ "GenSigCycleTime" SG_ 2499751697 TrailerWithoutABS_ISig_1 100;
BA_ "GenSigCycleTimeActive" SG_ 2499751697 TrailerWithoutABS_ISig_1 100;
BA_ "GenSigStartValue" SG_ 2499751697 TrailerWithoutABS_ISig_1 3;
BA_ "GenSigCycleTime" SG_ 2499751697 LowAirPressureAlert_ISig_1 100;
BA_ "GenSigCycleTimeActive" SG_ 2499751697 LowAirPressureAlert_ISig_1 100;
BA_ "GenSigStartValue" SG_ 2499751697 LowAirPressureAlert_ISig_1 3;
BA_ "GenSigCycleTime" SG_ 2499751697 ACC_SGO_Status_ISig_1 100;
BA_ "GenSigCycleTimeActive" SG_ 2499751697 ACC_SGO_Status_ISig_1 100;
BA_ "GenSigStartValue" SG_ 2499751697 ACC_SGO_Status_ISig_1 15;
BA_ "GenSigMaxLatency" SG_ 2499751697 ACC_SGO_Status_ISig_1 100;
BA_ "GenSigCycleTime" SG_ 2499751697 DifferentialLockStateFrAxle2 100;
BA_ "GenSigCycleTimeActive" SG_ 2499751697 DifferentialLockStateFrAxle2 100;
BA_ "GenSigStartValue" SG_ 2499751697 DifferentialLockStateFrAxle2 3;
BA_ "GenSigCycleTime" SG_ 2499751697 SetHSAOperation_ISig_1 100;
BA_ "GenSigCycleTimeActive" SG_ 2499751697 SetHSAOperation_ISig_1 100;
BA_ "GenSigStartValue" SG_ 2499751697 SetHSAOperation_ISig_1 7;
BA_ "GenSigCycleTime" SG_ 2499751697 CtaBs_HSABbRequest 100;
BA_ "GenSigCycleTimeActive" SG_ 2499751697 CtaBs_HSABbRequest 100;
BA_ "GenSigStartValue" SG_ 2499751697 CtaBs_HSABbRequest 3;
BA_ "GenSigMaxLatency" SG_ 2499751697 CtaBs_HSABbRequest 100;
BA_ "GenSigCycleTime" SG_ 2499751697 AWBEnableRequest_ISig_1 100;
BA_ "GenSigCycleTimeActive" SG_ 2499751697 AWBEnableRequest_ISig_1 100;
BA_ "GenSigStartValue" SG_ 2499751697 AWBEnableRequest_ISig_1 3;
BA_ "GenSigMaxLatency" SG_ 2499751697 AWBEnableRequest_ISig_1 500;
BA_ "GenSigCycleTime" SG_ 2499751697 RearPropulsionStat_Rear2Axle_ISi 100;
BA_ "GenSigCycleTimeActive" SG_ 2499751697 RearPropulsionStat_Rear2Axle_ISi 100;
BA_ "GenSigStartValue" SG_ 2499751697 RearPropulsionStat_Rear2Axle_ISi 15;
BA_ "SystemSignalLongSymbol" SG_ 2499751697 RearPropulsionStat_Rear2Axle_ISi "RearPropulsionStat_Rear2Axle_ISig_1";
BA_ "GenSigCycleTime" SG_ 2499751697 DifferentialLockStateCentral_ISi 100;
BA_ "GenSigCycleTimeActive" SG_ 2499751697 DifferentialLockStateCentral_ISi 100;
BA_ "GenSigStartValue" SG_ 2499751697 DifferentialLockStateCentral_ISi 3;
BA_ "SystemSignalLongSymbol" SG_ 2499751697 DifferentialLockStateCentral_ISi "DifferentialLockStateCentral_ISig_1";
BA_ "GenSigCycleTime" SG_ 2499751697 CentralRearDiffLock_stat_ISig_1 100;
BA_ "GenSigCycleTimeActive" SG_ 2499751697 CentralRearDiffLock_stat_ISig_1 100;
BA_ "GenSigStartValue" SG_ 2499751697 CentralRearDiffLock_stat_ISig_1 3;
BA_ "GenSigCycleTime" SG_ 2499751697 ACCHSARequest 100;
BA_ "GenSigCycleTimeActive" SG_ 2499751697 ACCHSARequest 100;
BA_ "GenSigStartValue" SG_ 2499751697 ACCHSARequest 7;
BA_ "GenSigMaxLatency" SG_ 2499751697 ACCHSARequest 100;
BA_ "GenSigCycleTime" SG_ 2499751697 DifferentialLockStateFrAxle1_ISi 100;
BA_ "GenSigCycleTimeActive" SG_ 2499751697 DifferentialLockStateFrAxle1_ISi 100;
BA_ "GenSigStartValue" SG_ 2499751697 DifferentialLockStateFrAxle1_ISi 3;
BA_ "SystemSignalLongSymbol" SG_ 2499751697 DifferentialLockStateFrAxle1_ISi "DifferentialLockStateFrAxle1_ISig_1";
BA_ "GenSigCycleTime" SG_ 2499751697 RearAxle2DiffLock_stat_ISig_1 100;
BA_ "GenSigCycleTimeActive" SG_ 2499751697 RearAxle2DiffLock_stat_ISig_1 100;
BA_ "GenSigStartValue" SG_ 2499751697 RearAxle2DiffLock_stat_ISig_1 3;
BA_ "GenSigCycleTime" SG_ 2499751697 TrailerConnected_ISig_1 100;
BA_ "GenSigCycleTimeActive" SG_ 2499751697 TrailerConnected_ISig_1 100;
BA_ "GenSigStartValue" SG_ 2499751697 TrailerConnected_ISig_1 3;
BA_ "GenSigCycleTime" SG_ 2499751697 DifferentialLockStateCentral2 100;
BA_ "GenSigCycleTimeActive" SG_ 2499751697 DifferentialLockStateCentral2 100;
BA_ "GenSigStartValue" SG_ 2499751697 DifferentialLockStateCentral2 3;
BA_ "GenSigCycleTime" SG_ 2499751697 RearPropulsionStat_Rear3Axle_ISi 100;
BA_ "GenSigCycleTimeActive" SG_ 2499751697 RearPropulsionStat_Rear3Axle_ISi 100;
BA_ "GenSigStartValue" SG_ 2499751697 RearPropulsionStat_Rear3Axle_ISi 15;
BA_ "SystemSignalLongSymbol" SG_ 2499751697 RearPropulsionStat_Rear3Axle_ISi "RearPropulsionStat_Rear3Axle_ISig_1";
BA_ "GenSigCycleTime" SG_ 2499751697 RearPropulsionStat_Rear1Axle_ISi 100;
BA_ "GenSigCycleTimeActive" SG_ 2499751697 RearPropulsionStat_Rear1Axle_ISi 100;
BA_ "GenSigStartValue" SG_ 2499751697 RearPropulsionStat_Rear1Axle_ISi 15;
BA_ "SystemSignalLongSymbol" SG_ 2499751697 RearPropulsionStat_Rear1Axle_ISi "RearPropulsionStat_Rear1Axle_ISig_1";
BA_ "GenSigCycleTime" SG_ 2499751697 RearAxle1DiffLock_stat_ISig_1 100;
BA_ "GenSigCycleTimeActive" SG_ 2499751697 RearAxle1DiffLock_stat_ISig_1 100;
BA_ "GenSigStartValue" SG_ 2499751697 RearAxle1DiffLock_stat_ISig_1 3;
BA_ "GenSigCycleTime" SG_ 2566897425 StaticTrailerBrake_rqst 100;
BA_ "GenSigCycleTimeActive" SG_ 2566897425 StaticTrailerBrake_rqst 100;
BA_ "GenSigStartValue" SG_ 2566897425 StaticTrailerBrake_rqst 3;
BA_ "GenSigCycleTime" SG_ 2566897425 OBD_Timestamp_ISig_1 100;
BA_ "GenSigCycleTimeActive" SG_ 2566897425 OBD_Timestamp_ISig_1 100;
BA_ "GenSigStartValue" SG_ 2566897425 OBD_Timestamp_ISig_1 4294967295;
BA_ "GenSigCycleTime" SG_ 2566897425 StretchBrakeEnable_rqst 100;
BA_ "GenSigCycleTimeActive" SG_ 2566897425 StretchBrakeEnable_rqst 100;
BA_ "GenSigStartValue" SG_ 2566897425 StretchBrakeEnable_rqst 7;
BA_ "GenSigCycleTime" SG_ 2566897425 AxleLoadStatus_ISig_1 100;
BA_ "GenSigCycleTimeActive" SG_ 2566897425 AxleLoadStatus_ISig_1 100;
BA_ "GenSigStartValue" SG_ 2566897425 AxleLoadStatus_ISig_1 7;
BA_ "GenSigCycleTime" SG_ 2566897425 FuelLevel_ISig_1 100;
BA_ "GenSigCycleTimeActive" SG_ 2566897425 FuelLevel_ISig_1 100;
BA_ "GenSigStartValue" SG_ 2566897425 FuelLevel_ISig_1 255;
BA_ "GenSigCycleTime" SG_ 2298429457 AcceleratorPedalPosition1_ISig_1 100;
BA_ "GenSigCycleTimeActive" SG_ 2298429457 AcceleratorPedalPosition1_ISig_1 100;
BA_ "GenSigStartValue" SG_ 2298429457 AcceleratorPedalPosition1_ISig_1 255;
BA_ "GenSigCycleTime" SG_ 2298429457 SWBrakeSwitch_ISig_1 100;
BA_ "GenSigCycleTimeActive" SG_ 2298429457 SWBrakeSwitch_ISig_1 100;
BA_ "GenSigStartValue" SG_ 2298429457 SWBrakeSwitch_ISig_1 3;
BA_ "GenSigCycleTime" SG_ 2298429457 AcceleratorPedalLowIdleSwitch_IS 100;
BA_ "GenSigCycleTimeActive" SG_ 2298429457 AcceleratorPedalLowIdleSwitch_IS 100;
BA_ "GenSigStartValue" SG_ 2298429457 AcceleratorPedalLowIdleSwitch_IS 3;
BA_ "SystemSignalLongSymbol" SG_ 2298429457 AcceleratorPedalLowIdleSwitch_IS "AcceleratorPedalLowIdleSwitch_ISig_1";
BA_ "GenSigCycleTime" SG_ 2298429457 BrakePedalPosition_ISig_1 100;
BA_ "GenSigCycleTimeActive" SG_ 2298429457 BrakePedalPosition_ISig_1 100;
BA_ "GenSigStartValue" SG_ 2298429457 BrakePedalPosition_ISig_1 255;
BA_ "GenSigCycleTime" SG_ 2298429457 VehicleMode_ISig_1 100;
BA_ "GenSigCycleTimeActive" SG_ 2298429457 VehicleMode_ISig_1 100;
BA_ "GenSigStartValue" SG_ 2298429457 VehicleMode_ISig_1 15;
BA_ "NeedsUpdateBit" SG_ 2298429457 VehicleMode_ISig_1 1;
BA_ "GenSigCycleTime" SG_ 2298429457 BrakePressureSensorDemand_ISig_1 100;
BA_ "GenSigCycleTimeActive" SG_ 2298429457 BrakePressureSensorDemand_ISig_1 100;
BA_ "GenSigStartValue" SG_ 2298429457 BrakePressureSensorDemand_ISig_1 255;
BA_ "GenSigSendType" SG_ 2298429457 VehicleMode_UB_ISig_1 7;
BA_ "GenSigCycleTime" SG_ 2298429457 AcctrPedalKickDownSw_stat 100;
BA_ "GenSigCycleTimeActive" SG_ 2298429457 AcctrPedalKickDownSw_stat 100;
BA_ "GenSigStartValue" SG_ 2298429457 AcctrPedalKickDownSw_stat 3;
BA_ "GenSigCycleTime" SG_ 2298429457 TransmissionOutputShaftSpeed 100;
BA_ "GenSigCycleTimeActive" SG_ 2298429457 TransmissionOutputShaftSpeed 100;
BA_ "GenSigStartValue" SG_ 2298429457 TransmissionOutputShaftSpeed 65535;
BA_ "GenSigCycleTime" SG_ 2298429457 ClutchPedalPosition 100;
BA_ "GenSigCycleTimeActive" SG_ 2298429457 ClutchPedalPosition 100;
BA_ "GenSigStartValue" SG_ 2298429457 ClutchPedalPosition 255;
BA_ "GenSigCycleTime" SG_ 2566832401 TotalVehicleDistanceHighRes_ISig 100;
BA_ "GenSigCycleTimeActive" SG_ 2566832401 TotalVehicleDistanceHighRes_ISig 100;
BA_ "GenSigStartValue" SG_ 2566832401 TotalVehicleDistanceHighRes_ISig 4294967295;
BA_ "SystemSignalLongSymbol" SG_ 2566832401 TotalVehicleDistanceHighRes_ISig "TotalVehicleDistanceHighRes_ISig_1";
BA_ "GenSigCycleTime" SG_ 2364541195 SteeringWheelAngle_ISig_1 100;
BA_ "GenSigCycleTimeActive" SG_ 2364541195 SteeringWheelAngle_ISig_1 100;
BA_ "GenSigStartValue" SG_ 2364541195 SteeringWheelAngle_ISig_1 65535;
BA_ "GenSigCycleTime" SG_ 2364541195 YawRate_ISig_1 100;
BA_ "GenSigCycleTimeActive" SG_ 2364541195 YawRate_ISig_1 100;
BA_ "GenSigStartValue" SG_ 2364541195 YawRate_ISig_1 65535;
BA_ "GenSigCycleTime" SG_ 2566803211 ROPEngineControlActive 100;
BA_ "GenSigCycleTimeActive" SG_ 2566803211 ROPEngineControlActive 100;
BA_ "GenSigStartValue" SG_ 2566803211 ROPEngineControlActive 3;
BA_ "GenSigCycleTime" SG_ 2566803211 VDCFullyOperational 100;
BA_ "GenSigCycleTimeActive" SG_ 2566803211 VDCFullyOperational 100;
BA_ "GenSigStartValue" SG_ 2566803211 VDCFullyOperational 3;
BA_ "GenSigCycleTime" SG_ 2566803211 ROPBrakeControlActive 100;
BA_ "GenSigCycleTimeActive" SG_ 2566803211 ROPBrakeControlActive 100;
BA_ "GenSigStartValue" SG_ 2566803211 ROPBrakeControlActive 3;
BA_ "GenSigCycleTime" SG_ 2566803211 ESCHealthStatus_ISig_1 100;
BA_ "GenSigCycleTimeActive" SG_ 2566803211 ESCHealthStatus_ISig_1 100;
BA_ "GenSigStartValue" SG_ 2566803211 ESCHealthStatus_ISig_1 3;
BA_ "GenSigCycleTime" SG_ 2566803211 YCBrakeControlActive 100;
BA_ "GenSigCycleTimeActive" SG_ 2566803211 YCBrakeControlActive 100;
BA_ "GenSigStartValue" SG_ 2566803211 YCBrakeControlActive 3;
BA_ "GenSigCycleTime" SG_ 2566803211 YCEngineControlActive 100;
BA_ "GenSigCycleTimeActive" SG_ 2566803211 YCEngineControlActive 100;
BA_ "GenSigStartValue" SG_ 2566803211 YCEngineControlActive 3;
BA_ "GenSigCycleTime" SG_ 1791 VCMNetVer_C01_Major 100;
BA_ "GenSigCycleTimeActive" SG_ 1791 VCMNetVer_C01_Major 100;
BA_ "GenSigStartValue" SG_ 1791 VCMNetVer_C01_Major 2;
BA_ "GenSigCycleTime" SG_ 1791 VCMNetVer_C01_Patch 100;
BA_ "GenSigCycleTimeActive" SG_ 1791 VCMNetVer_C01_Patch 100;
BA_ "GenSigCycleTime" SG_ 1791 VCMNetVer_C01_NetID 100;
BA_ "GenSigCycleTimeActive" SG_ 1791 VCMNetVer_C01_NetID 100;
BA_ "GenSigStartValue" SG_ 1791 VCMNetVer_C01_NetID 1;
BA_ "GenSigCycleTime" SG_ 1791 VCMNetVer_C01_Minor 100;
BA_ "GenSigCycleTimeActive" SG_ 1791 VCMNetVer_C01_Minor 100;
BA_ "GenSigStartValue" SG_ 1791 VCMNetVer_C01_Minor 3;
BA_ "GenSigCycleTime" SG_ 1791 VCMNetVer_C01_Dirty 100;
BA_ "GenSigCycleTimeActive" SG_ 1791 VCMNetVer_C01_Dirty 100;
BA_ "GenSigCycleTime" SG_ 2365524497 DoorsAjar_stat_ISig_1 100;
BA_ "GenSigCycleTimeActive" SG_ 2365524497 DoorsAjar_stat_ISig_1 100;
BA_ "GenSigStartValue" SG_ 2365524497 DoorsAjar_stat_ISig_1 7;
BA_ "GenSigMaxLatency" SG_ 2365524497 DoorsAjar_stat_ISig_1 50;
BA_ "GenSigSendType" SG_ 2671902706 FuncDiagDataTester_ISig_1 7;
BA_ "GenSigSendType" SG_ 2671902708 FuncDiagDataIntTesterF4_ISig_1 7;
BA_ "GenSigSendType" SG_ 2348814353 TSC1RECUVMCU_OvrdCtrlMPr 7;
BA_ "GenSigCycleTime" SG_ 2348814353 TSC1RECUVMCU_OvrdCtrlMPr 100;
BA_ "GenSigCycleTimeActive" SG_ 2348814353 TSC1RECUVMCU_OvrdCtrlMPr 100;
BA_ "GenSigStartValue" SG_ 2348814353 TSC1RECUVMCU_OvrdCtrlMPr 3;
BA_ "GenSigSendType" SG_ 2348814353 TSC1RECUVMCU_EnRSpdSpdLm 7;
BA_ "GenSigCycleTime" SG_ 2348814353 TSC1RECUVMCU_EnRSpdSpdLm 100;
BA_ "GenSigCycleTimeActive" SG_ 2348814353 TSC1RECUVMCU_EnRSpdSpdLm 100;
BA_ "GenSigStartValue" SG_ 2348814353 TSC1RECUVMCU_EnRSpdSpdLm 65535;
BA_ "GenSigSendType" SG_ 2348814353 TSC1RECUVMCU_EnRSpdCtrlC 7;
BA_ "GenSigCycleTime" SG_ 2348814353 TSC1RECUVMCU_EnRSpdCtrlC 100;
BA_ "GenSigCycleTimeActive" SG_ 2348814353 TSC1RECUVMCU_EnRSpdCtrlC 100;
BA_ "GenSigSendType" SG_ 2348814353 TSC1RECUVMCU_EnOvrdCtrlM 6;
BA_ "GenSigCycleTime" SG_ 2348814353 TSC1RECUVMCU_EnOvrdCtrlM 100;
BA_ "GenSigCycleTimeActive" SG_ 2348814353 TSC1RECUVMCU_EnOvrdCtrlM 100;
BA_ "GenSigSendType" SG_ 2348814353 TSC1RECUVMCU_EnRTrqTrqLm 7;
BA_ "GenSigCycleTime" SG_ 2348814353 TSC1RECUVMCU_EnRTrqTrqLm 100;
BA_ "GenSigCycleTimeActive" SG_ 2348814353 TSC1RECUVMCU_EnRTrqTrqLm 100;
BA_ "GenSigStartValue" SG_ 2348814353 TSC1RECUVMCU_EnRTrqTrqLm 255;
BA_ "GenSigSendType" SG_ 2348814339 TSC1RECUTECU_EnRTrqTrqLm 7;
BA_ "GenSigCycleTime" SG_ 2348814339 TSC1RECUTECU_EnRTrqTrqLm 100;
BA_ "GenSigCycleTimeActive" SG_ 2348814339 TSC1RECUTECU_EnRTrqTrqLm 100;
BA_ "GenSigStartValue" SG_ 2348814339 TSC1RECUTECU_EnRTrqTrqLm 255;
BA_ "GenSigSendType" SG_ 2348814339 TSC1RECUTECU_EnOvrdCtrlM 6;
BA_ "GenSigCycleTime" SG_ 2348814339 TSC1RECUTECU_EnOvrdCtrlM 100;
BA_ "GenSigCycleTimeActive" SG_ 2348814339 TSC1RECUTECU_EnOvrdCtrlM 100;
BA_ "GenSigSendType" SG_ 2348814339 TSC1RECUTECU_OvrdCtrlMPr 7;
BA_ "GenSigCycleTime" SG_ 2348814339 TSC1RECUTECU_OvrdCtrlMPr 100;
BA_ "GenSigCycleTimeActive" SG_ 2348814339 TSC1RECUTECU_OvrdCtrlMPr 100;
BA_ "GenSigStartValue" SG_ 2348814339 TSC1RECUTECU_OvrdCtrlMPr 3;
BA_ "GenSigSendType" SG_ 2348814339 TSC1RECUTECU_EnRSpdSpdLm 7;
BA_ "GenSigCycleTime" SG_ 2348814339 TSC1RECUTECU_EnRSpdSpdLm 100;
BA_ "GenSigCycleTimeActive" SG_ 2348814339 TSC1RECUTECU_EnRSpdSpdLm 100;
BA_ "GenSigStartValue" SG_ 2348814339 TSC1RECUTECU_EnRSpdSpdLm 65535;
BA_ "GenSigSendType" SG_ 2348814339 TSC1RECUTECU_EnRSpdCtrlC 7;
BA_ "GenSigCycleTime" SG_ 2348814339 TSC1RECUTECU_EnRSpdCtrlC 100;
BA_ "GenSigCycleTimeActive" SG_ 2348814339 TSC1RECUTECU_EnRSpdCtrlC 100;
BA_ "GenSigSendType" SG_ 2348814337 TSC1RECUEMSdap_EnRTrqTrqLm 7;
BA_ "GenSigCycleTime" SG_ 2348814337 TSC1RECUEMSdap_EnRTrqTrqLm 100;
BA_ "GenSigCycleTimeActive" SG_ 2348814337 TSC1RECUEMSdap_EnRTrqTrqLm 100;
BA_ "GenSigStartValue" SG_ 2348814337 TSC1RECUEMSdap_EnRTrqTrqLm 255;
BA_ "GenSigSendType" SG_ 2348814337 TSC1RECUEMSdap_OvrdCtrlMPr 7;
BA_ "GenSigCycleTime" SG_ 2348814337 TSC1RECUEMSdap_OvrdCtrlMPr 100;
BA_ "GenSigCycleTimeActive" SG_ 2348814337 TSC1RECUEMSdap_OvrdCtrlMPr 100;
BA_ "GenSigStartValue" SG_ 2348814337 TSC1RECUEMSdap_OvrdCtrlMPr 3;
BA_ "GenSigSendType" SG_ 2348814337 TSC1RECUEMSdap_EnRSpdSpdLm 7;
BA_ "GenSigCycleTime" SG_ 2348814337 TSC1RECUEMSdap_EnRSpdSpdLm 100;
BA_ "GenSigCycleTimeActive" SG_ 2348814337 TSC1RECUEMSdap_EnRSpdSpdLm 100;
BA_ "GenSigStartValue" SG_ 2348814337 TSC1RECUEMSdap_EnRSpdSpdLm 65535;
BA_ "GenSigSendType" SG_ 2348814337 TSC1RECUEMSdap_EnRSpdCtrlC 7;
BA_ "GenSigCycleTime" SG_ 2348814337 TSC1RECUEMSdap_EnRSpdCtrlC 100;
BA_ "GenSigCycleTimeActive" SG_ 2348814337 TSC1RECUEMSdap_EnRSpdCtrlC 100;
BA_ "GenSigSendType" SG_ 2348814337 TSC1RECUEMSdap_EnOvrdCtrlM 6;
BA_ "GenSigCycleTime" SG_ 2348814337 TSC1RECUEMSdap_EnOvrdCtrlM 100;
BA_ "GenSigCycleTimeActive" SG_ 2348814337 TSC1RECUEMSdap_EnOvrdCtrlM 100;
BA_ "GenSigSendType" SG_ 2348814336 TSC1RECUEMSccb_OvrdCtrlMPr 7;
BA_ "GenSigCycleTime" SG_ 2348814336 TSC1RECUEMSccb_OvrdCtrlMPr 100;
BA_ "GenSigCycleTimeActive" SG_ 2348814336 TSC1RECUEMSccb_OvrdCtrlMPr 100;
BA_ "GenSigStartValue" SG_ 2348814336 TSC1RECUEMSccb_OvrdCtrlMPr 3;
BA_ "GenSigSendType" SG_ 2348814336 TSC1RECUEMSccb_EnRSpdCtrlC 7;
BA_ "GenSigCycleTime" SG_ 2348814336 TSC1RECUEMSccb_EnRSpdCtrlC 100;
BA_ "GenSigCycleTimeActive" SG_ 2348814336 TSC1RECUEMSccb_EnRSpdCtrlC 100;
BA_ "GenSigSendType" SG_ 2348814336 TSC1RECUEMSccb_EnRTrqTrqLm 7;
BA_ "GenSigCycleTime" SG_ 2348814336 TSC1RECUEMSccb_EnRTrqTrqLm 100;
BA_ "GenSigCycleTimeActive" SG_ 2348814336 TSC1RECUEMSccb_EnRTrqTrqLm 100;
BA_ "GenSigStartValue" SG_ 2348814336 TSC1RECUEMSccb_EnRTrqTrqLm 255;
BA_ "GenSigSendType" SG_ 2348814336 TSC1RECUEMSccb_EnOvrdCtrlM 6;
BA_ "GenSigCycleTime" SG_ 2348814336 TSC1RECUEMSccb_EnOvrdCtrlM 100;
BA_ "GenSigCycleTimeActive" SG_ 2348814336 TSC1RECUEMSccb_EnOvrdCtrlM 100;
BA_ "GenSigSendType" SG_ 2348814336 TSC1RECUEMSccb_EnRSpdSpdLm 7;
BA_ "GenSigCycleTime" SG_ 2348814336 TSC1RECUEMSccb_EnRSpdSpdLm 100;
BA_ "GenSigCycleTimeActive" SG_ 2348814336 TSC1RECUEMSccb_EnRSpdSpdLm 100;
BA_ "GenSigStartValue" SG_ 2348814336 TSC1RECUEMSccb_EnRSpdSpdLm 65535;
BA_ "GenSigSendType" SG_ 2348814347 TSC1RECUABS_EnOvrdCtrlM 6;
BA_ "GenSigCycleTime" SG_ 2348814347 TSC1RECUABS_EnOvrdCtrlM 100;
BA_ "GenSigCycleTimeActive" SG_ 2348814347 TSC1RECUABS_EnOvrdCtrlM 100;
BA_ "GenSigStartValue" SG_ 2348814347 TSC1RECUABS_EnOvrdCtrlM 3;
BA_ "GenSigSendType" SG_ 2348814347 TSC1RECUABS_EnRTrqTrqLm 7;
BA_ "GenSigCycleTime" SG_ 2348814347 TSC1RECUABS_EnRTrqTrqLm 100;
BA_ "GenSigCycleTimeActive" SG_ 2348814347 TSC1RECUABS_EnRTrqTrqLm 100;
BA_ "GenSigStartValue" SG_ 2348814347 TSC1RECUABS_EnRTrqTrqLm 255;
BA_ "GenSigSendType" SG_ 2348814347 TSC1RECUABS_OvrdCtrlMPr 7;
BA_ "GenSigCycleTime" SG_ 2348814347 TSC1RECUABS_OvrdCtrlMPr 100;
BA_ "GenSigCycleTimeActive" SG_ 2348814347 TSC1RECUABS_OvrdCtrlMPr 100;
BA_ "GenSigStartValue" SG_ 2348814347 TSC1RECUABS_OvrdCtrlMPr 3;
BA_ "GenSigSendType" SG_ 2348814347 TSC1RECUABS_EnRSpdSpdLm 7;
BA_ "GenSigCycleTime" SG_ 2348814347 TSC1RECUABS_EnRSpdSpdLm 100;
BA_ "GenSigCycleTimeActive" SG_ 2348814347 TSC1RECUABS_EnRSpdSpdLm 100;
BA_ "GenSigStartValue" SG_ 2348814347 TSC1RECUABS_EnRSpdSpdLm 65535;
BA_ "GenSigSendType" SG_ 2348814347 TSC1RECUABS_EnRSpdCtrlC 7;
BA_ "GenSigCycleTime" SG_ 2348814347 TSC1RECUABS_EnRSpdCtrlC 100;
BA_ "GenSigCycleTimeActive" SG_ 2348814347 TSC1RECUABS_EnRSpdCtrlC 100;
BA_ "GenSigStartValue" SG_ 2348814347 TSC1RECUABS_EnRSpdCtrlC 3;
BA_ "GenSigSendType" SG_ 2348810257 TSC1EMSVMCUtr_EnRSpdCtrlC 7;
BA_ "GenSigCycleTime" SG_ 2348810257 TSC1EMSVMCUtr_EnRSpdCtrlC 100;
BA_ "GenSigCycleTimeActive" SG_ 2348810257 TSC1EMSVMCUtr_EnRSpdCtrlC 100;
BA_ "SeToolAncestorID_SIGNAL" SG_ 2348810257 TSC1EMSVMCUtr_EnRSpdCtrlC "x0000001D042564C9";
BA_ "SeToolItemID_SIGNAL" SG_ 2348810257 TSC1EMSVMCUtr_EnRSpdCtrlC "x0000001D042564C9";
BA_ "SeToolName_SIGNAL" SG_ 2348810257 TSC1EMSVMCUtr_EnRSpdCtrlC "EnRSpdCtrlC";
BA_ "SeToolOwnerSigGroupID_SIGNAL" SG_ 2348810257 TSC1EMSVMCUtr_EnRSpdCtrlC "x0000001D043FB710";
BA_ "SeToolOwnerSigGroup_SIGNAL" SG_ 2348810257 TSC1EMSVMCUtr_EnRSpdCtrlC "TSC1EMSVMCUtr";
BA_ "SeToolVersion_SIGNAL" SG_ 2348810257 TSC1EMSVMCUtr_EnRSpdCtrlC "1";
BA_ "GenSigSendType" SG_ 2348810257 TSC1EMSVMCUtr_EnRSpdSpdLm 7;
BA_ "GenSigCycleTime" SG_ 2348810257 TSC1EMSVMCUtr_EnRSpdSpdLm 100;
BA_ "GenSigCycleTimeActive" SG_ 2348810257 TSC1EMSVMCUtr_EnRSpdSpdLm 100;
BA_ "GenSigStartValue" SG_ 2348810257 TSC1EMSVMCUtr_EnRSpdSpdLm 65535;
BA_ "SeToolAncestorID_SIGNAL" SG_ 2348810257 TSC1EMSVMCUtr_EnRSpdSpdLm "x0000001D042564D1";
BA_ "SeToolItemID_SIGNAL" SG_ 2348810257 TSC1EMSVMCUtr_EnRSpdSpdLm "x0000001D042564D1";
BA_ "SeToolName_SIGNAL" SG_ 2348810257 TSC1EMSVMCUtr_EnRSpdSpdLm "EnRSpdSpdLm";
BA_ "SeToolOwnerSigGroupID_SIGNAL" SG_ 2348810257 TSC1EMSVMCUtr_EnRSpdSpdLm "x0000001D043FB710";
BA_ "SeToolOwnerSigGroup_SIGNAL" SG_ 2348810257 TSC1EMSVMCUtr_EnRSpdSpdLm "TSC1EMSVMCUtr";
BA_ "SeToolVersion_SIGNAL" SG_ 2348810257 TSC1EMSVMCUtr_EnRSpdSpdLm "1";
BA_ "GenSigSendType" SG_ 2348810257 TSC1EMSVMCUtr_EnOvrdCtrlM 6;
BA_ "GenSigCycleTime" SG_ 2348810257 TSC1EMSVMCUtr_EnOvrdCtrlM 100;
BA_ "GenSigCycleTimeActive" SG_ 2348810257 TSC1EMSVMCUtr_EnOvrdCtrlM 100;
BA_ "SeToolAncestorID_SIGNAL" SG_ 2348810257 TSC1EMSVMCUtr_EnOvrdCtrlM "x0000001D042564C7";
BA_ "SeToolItemID_SIGNAL" SG_ 2348810257 TSC1EMSVMCUtr_EnOvrdCtrlM "x0000001D042564C7";
BA_ "SeToolName_SIGNAL" SG_ 2348810257 TSC1EMSVMCUtr_EnOvrdCtrlM "EnOvrdCtrlM";
BA_ "SeToolOwnerSigGroupID_SIGNAL" SG_ 2348810257 TSC1EMSVMCUtr_EnOvrdCtrlM "x0000001D043FB710";
BA_ "SeToolOwnerSigGroup_SIGNAL" SG_ 2348810257 TSC1EMSVMCUtr_EnOvrdCtrlM "TSC1EMSVMCUtr";
BA_ "SeToolVersion_SIGNAL" SG_ 2348810257 TSC1EMSVMCUtr_EnOvrdCtrlM "1";
BA_ "GenSigSendType" SG_ 2348810257 TSC1EMSVMCUtr_OvrdCtrlMPr 7;
BA_ "GenSigCycleTime" SG_ 2348810257 TSC1EMSVMCUtr_OvrdCtrlMPr 100;
BA_ "GenSigCycleTimeActive" SG_ 2348810257 TSC1EMSVMCUtr_OvrdCtrlMPr 100;
BA_ "GenSigStartValue" SG_ 2348810257 TSC1EMSVMCUtr_OvrdCtrlMPr 3;
BA_ "SeToolAncestorID_SIGNAL" SG_ 2348810257 TSC1EMSVMCUtr_OvrdCtrlMPr "x0000001D042564CE";
BA_ "SeToolItemID_SIGNAL" SG_ 2348810257 TSC1EMSVMCUtr_OvrdCtrlMPr "x0000001D042564CE";
BA_ "SeToolName_SIGNAL" SG_ 2348810257 TSC1EMSVMCUtr_OvrdCtrlMPr "OvrdCtrlMPr";
BA_ "SeToolOwnerSigGroupID_SIGNAL" SG_ 2348810257 TSC1EMSVMCUtr_OvrdCtrlMPr "x0000001D043FB710";
BA_ "SeToolOwnerSigGroup_SIGNAL" SG_ 2348810257 TSC1EMSVMCUtr_OvrdCtrlMPr "TSC1EMSVMCUtr";
BA_ "SeToolVersion_SIGNAL" SG_ 2348810257 TSC1EMSVMCUtr_OvrdCtrlMPr "1";
BA_ "GenSigSendType" SG_ 2348810257 TSC1EMSVMCUtr_EnRTrqTrqLm 7;
BA_ "GenSigCycleTime" SG_ 2348810257 TSC1EMSVMCUtr_EnRTrqTrqLm 100;
BA_ "GenSigCycleTimeActive" SG_ 2348810257 TSC1EMSVMCUtr_EnRTrqTrqLm 100;
BA_ "GenSigStartValue" SG_ 2348810257 TSC1EMSVMCUtr_EnRTrqTrqLm 255;
BA_ "SeToolAncestorID_SIGNAL" SG_ 2348810257 TSC1EMSVMCUtr_EnRTrqTrqLm "x0000001D042564D4";
BA_ "SeToolItemID_SIGNAL" SG_ 2348810257 TSC1EMSVMCUtr_EnRTrqTrqLm "x0000001D042564D4";
BA_ "SeToolName_SIGNAL" SG_ 2348810257 TSC1EMSVMCUtr_EnRTrqTrqLm "EnRTrqTrqLm";
BA_ "SeToolOwnerSigGroupID_SIGNAL" SG_ 2348810257 TSC1EMSVMCUtr_EnRTrqTrqLm "x0000001D043FB710";
BA_ "SeToolOwnerSigGroup_SIGNAL" SG_ 2348810257 TSC1EMSVMCUtr_EnRTrqTrqLm "TSC1EMSVMCUtr";
BA_ "SeToolVersion_SIGNAL" SG_ 2348810257 TSC1EMSVMCUtr_EnRTrqTrqLm "1";
BA_ "GenSigSendType" SG_ 2348810288 TSC1EMSVMCUes_EnRSpdSpdLm 7;
BA_ "GenSigCycleTime" SG_ 2348810288 TSC1EMSVMCUes_EnRSpdSpdLm 100;
BA_ "GenSigCycleTimeActive" SG_ 2348810288 TSC1EMSVMCUes_EnRSpdSpdLm 100;
BA_ "GenSigStartValue" SG_ 2348810288 TSC1EMSVMCUes_EnRSpdSpdLm 65535;
BA_ "SeToolAncestorID_SIGNAL" SG_ 2348810288 TSC1EMSVMCUes_EnRSpdSpdLm "x0000001D042564D1";
BA_ "SeToolItemID_SIGNAL" SG_ 2348810288 TSC1EMSVMCUes_EnRSpdSpdLm "x0000001D042564D1";
BA_ "SeToolName_SIGNAL" SG_ 2348810288 TSC1EMSVMCUes_EnRSpdSpdLm "EnRSpdSpdLm";
BA_ "SeToolOwnerSigGroupID_SIGNAL" SG_ 2348810288 TSC1EMSVMCUes_EnRSpdSpdLm "x0000001D0436B0FF";
BA_ "SeToolOwnerSigGroup_SIGNAL" SG_ 2348810288 TSC1EMSVMCUes_EnRSpdSpdLm "TSC1EMSVMCUes";
BA_ "SeToolVersion_SIGNAL" SG_ 2348810288 TSC1EMSVMCUes_EnRSpdSpdLm "1";
BA_ "GenSigSendType" SG_ 2348810288 TSC1EMSVMCUes_OvrdCtrlMPr 7;
BA_ "GenSigCycleTime" SG_ 2348810288 TSC1EMSVMCUes_OvrdCtrlMPr 100;
BA_ "GenSigCycleTimeActive" SG_ 2348810288 TSC1EMSVMCUes_OvrdCtrlMPr 100;
BA_ "GenSigStartValue" SG_ 2348810288 TSC1EMSVMCUes_OvrdCtrlMPr 3;
BA_ "SeToolAncestorID_SIGNAL" SG_ 2348810288 TSC1EMSVMCUes_OvrdCtrlMPr "x0000001D042564CE";
BA_ "SeToolItemID_SIGNAL" SG_ 2348810288 TSC1EMSVMCUes_OvrdCtrlMPr "x0000001D042564CE";
BA_ "SeToolName_SIGNAL" SG_ 2348810288 TSC1EMSVMCUes_OvrdCtrlMPr "OvrdCtrlMPr";
BA_ "SeToolOwnerSigGroupID_SIGNAL" SG_ 2348810288 TSC1EMSVMCUes_OvrdCtrlMPr "x0000001D0436B0FF";
BA_ "SeToolOwnerSigGroup_SIGNAL" SG_ 2348810288 TSC1EMSVMCUes_OvrdCtrlMPr "TSC1EMSVMCUes";
BA_ "SeToolVersion_SIGNAL" SG_ 2348810288 TSC1EMSVMCUes_OvrdCtrlMPr "1";
BA_ "GenSigSendType" SG_ 2348810288 TSC1EMSVMCUes_EnRSpdCtrlC 7;
BA_ "GenSigCycleTime" SG_ 2348810288 TSC1EMSVMCUes_EnRSpdCtrlC 100;
BA_ "GenSigCycleTimeActive" SG_ 2348810288 TSC1EMSVMCUes_EnRSpdCtrlC 100;
BA_ "SeToolAncestorID_SIGNAL" SG_ 2348810288 TSC1EMSVMCUes_EnRSpdCtrlC "x0000001D042564C9";
BA_ "SeToolItemID_SIGNAL" SG_ 2348810288 TSC1EMSVMCUes_EnRSpdCtrlC "x0000001D042564C9";
BA_ "SeToolName_SIGNAL" SG_ 2348810288 TSC1EMSVMCUes_EnRSpdCtrlC "EnRSpdCtrlC";
BA_ "SeToolOwnerSigGroupID_SIGNAL" SG_ 2348810288 TSC1EMSVMCUes_EnRSpdCtrlC "x0000001D0436B0FF";
BA_ "SeToolOwnerSigGroup_SIGNAL" SG_ 2348810288 TSC1EMSVMCUes_EnRSpdCtrlC "TSC1EMSVMCUes";
BA_ "SeToolVersion_SIGNAL" SG_ 2348810288 TSC1EMSVMCUes_EnRSpdCtrlC "1";
BA_ "GenSigSendType" SG_ 2348810288 TSC1EMSVMCUes_EnOvrdCtrlM 6;
BA_ "GenSigCycleTime" SG_ 2348810288 TSC1EMSVMCUes_EnOvrdCtrlM 100;
BA_ "GenSigCycleTimeActive" SG_ 2348810288 TSC1EMSVMCUes_EnOvrdCtrlM 100;
BA_ "SeToolAncestorID_SIGNAL" SG_ 2348810288 TSC1EMSVMCUes_EnOvrdCtrlM "x0000001D042564C7";
BA_ "SeToolItemID_SIGNAL" SG_ 2348810288 TSC1EMSVMCUes_EnOvrdCtrlM "x0000001D042564C7";
BA_ "SeToolName_SIGNAL" SG_ 2348810288 TSC1EMSVMCUes_EnOvrdCtrlM "EnOvrdCtrlM";
BA_ "SeToolOwnerSigGroupID_SIGNAL" SG_ 2348810288 TSC1EMSVMCUes_EnOvrdCtrlM "x0000001D0436B0FF";
BA_ "SeToolOwnerSigGroup_SIGNAL" SG_ 2348810288 TSC1EMSVMCUes_EnOvrdCtrlM "TSC1EMSVMCUes";
BA_ "SeToolVersion_SIGNAL" SG_ 2348810288 TSC1EMSVMCUes_EnOvrdCtrlM "1";
BA_ "GenSigSendType" SG_ 2348810288 TSC1EMSVMCUes_EnRTrqTrqLm 7;
BA_ "GenSigCycleTime" SG_ 2348810288 TSC1EMSVMCUes_EnRTrqTrqLm 100;
BA_ "GenSigCycleTimeActive" SG_ 2348810288 TSC1EMSVMCUes_EnRTrqTrqLm 100;
BA_ "GenSigStartValue" SG_ 2348810288 TSC1EMSVMCUes_EnRTrqTrqLm 255;
BA_ "SeToolAncestorID_SIGNAL" SG_ 2348810288 TSC1EMSVMCUes_EnRTrqTrqLm "x0000001D042564D4";
BA_ "SeToolItemID_SIGNAL" SG_ 2348810288 TSC1EMSVMCUes_EnRTrqTrqLm "x0000001D042564D4";
BA_ "SeToolName_SIGNAL" SG_ 2348810288 TSC1EMSVMCUes_EnRTrqTrqLm "EnRTrqTrqLm";
BA_ "SeToolOwnerSigGroupID_SIGNAL" SG_ 2348810288 TSC1EMSVMCUes_EnRTrqTrqLm "x0000001D0436B0FF";
BA_ "SeToolOwnerSigGroup_SIGNAL" SG_ 2348810288 TSC1EMSVMCUes_EnRTrqTrqLm "TSC1EMSVMCUes";
BA_ "SeToolVersion_SIGNAL" SG_ 2348810288 TSC1EMSVMCUes_EnRTrqTrqLm "1";
BA_ "GenSigSendType" SG_ 2348810243 TSC1EMSTECU_EnRSpdCtrlC 7;
BA_ "GenSigCycleTime" SG_ 2348810243 TSC1EMSTECU_EnRSpdCtrlC 100;
BA_ "GenSigCycleTimeActive" SG_ 2348810243 TSC1EMSTECU_EnRSpdCtrlC 100;
BA_ "SeToolAncestorID_SIGNAL" SG_ 2348810243 TSC1EMSTECU_EnRSpdCtrlC "x0000001D042564C9";
BA_ "SeToolItemID_SIGNAL" SG_ 2348810243 TSC1EMSTECU_EnRSpdCtrlC "x0000001D042564C9";
BA_ "SeToolName_SIGNAL" SG_ 2348810243 TSC1EMSTECU_EnRSpdCtrlC "EnRSpdCtrlC";
BA_ "SeToolOwnerSigGroupID_SIGNAL" SG_ 2348810243 TSC1EMSTECU_EnRSpdCtrlC "x0000001D043D7655";
BA_ "SeToolOwnerSigGroup_SIGNAL" SG_ 2348810243 TSC1EMSTECU_EnRSpdCtrlC "TSC1_TECU_EMS";
BA_ "SeToolVersion_SIGNAL" SG_ 2348810243 TSC1EMSTECU_EnRSpdCtrlC "1";
BA_ "GenSigSendType" SG_ 2348810243 TSC1EMSTECU_EnRSpdSpdLm 7;
BA_ "GenSigCycleTime" SG_ 2348810243 TSC1EMSTECU_EnRSpdSpdLm 100;
BA_ "GenSigCycleTimeActive" SG_ 2348810243 TSC1EMSTECU_EnRSpdSpdLm 100;
BA_ "GenSigStartValue" SG_ 2348810243 TSC1EMSTECU_EnRSpdSpdLm 65535;
BA_ "SeToolAncestorID_SIGNAL" SG_ 2348810243 TSC1EMSTECU_EnRSpdSpdLm "x0000001D042564D1";
BA_ "SeToolItemID_SIGNAL" SG_ 2348810243 TSC1EMSTECU_EnRSpdSpdLm "x0000001D042564D1";
BA_ "SeToolName_SIGNAL" SG_ 2348810243 TSC1EMSTECU_EnRSpdSpdLm "EnRSpdSpdLm";
BA_ "SeToolOwnerSigGroupID_SIGNAL" SG_ 2348810243 TSC1EMSTECU_EnRSpdSpdLm "x0000001D043D7655";
BA_ "SeToolOwnerSigGroup_SIGNAL" SG_ 2348810243 TSC1EMSTECU_EnRSpdSpdLm "TSC1_TECU_EMS";
BA_ "SeToolVersion_SIGNAL" SG_ 2348810243 TSC1EMSTECU_EnRSpdSpdLm "1";
BA_ "GenSigSendType" SG_ 2348810243 TSC1EMSTECU_OvrdCtrlMPr 7;
BA_ "GenSigCycleTime" SG_ 2348810243 TSC1EMSTECU_OvrdCtrlMPr 100;
BA_ "GenSigCycleTimeActive" SG_ 2348810243 TSC1EMSTECU_OvrdCtrlMPr 100;
BA_ "GenSigStartValue" SG_ 2348810243 TSC1EMSTECU_OvrdCtrlMPr 3;
BA_ "SeToolAncestorID_SIGNAL" SG_ 2348810243 TSC1EMSTECU_OvrdCtrlMPr "x0000001D042564CE";
BA_ "SeToolItemID_SIGNAL" SG_ 2348810243 TSC1EMSTECU_OvrdCtrlMPr "x0000001D042564CE";
BA_ "SeToolName_SIGNAL" SG_ 2348810243 TSC1EMSTECU_OvrdCtrlMPr "OvrdCtrlMPr";
BA_ "SeToolOwnerSigGroupID_SIGNAL" SG_ 2348810243 TSC1EMSTECU_OvrdCtrlMPr "x0000001D043D7655";
BA_ "SeToolOwnerSigGroup_SIGNAL" SG_ 2348810243 TSC1EMSTECU_OvrdCtrlMPr "TSC1_TECU_EMS";
BA_ "SeToolVersion_SIGNAL" SG_ 2348810243 TSC1EMSTECU_OvrdCtrlMPr "1";
BA_ "GenSigSendType" SG_ 2348810243 TSC1EMSTECU_EnRTrqTrqLm 7;
BA_ "GenSigCycleTime" SG_ 2348810243 TSC1EMSTECU_EnRTrqTrqLm 100;
BA_ "GenSigCycleTimeActive" SG_ 2348810243 TSC1EMSTECU_EnRTrqTrqLm 100;
BA_ "GenSigStartValue" SG_ 2348810243 TSC1EMSTECU_EnRTrqTrqLm 255;
BA_ "SeToolAncestorID_SIGNAL" SG_ 2348810243 TSC1EMSTECU_EnRTrqTrqLm "x0000001D042564D4";
BA_ "SeToolItemID_SIGNAL" SG_ 2348810243 TSC1EMSTECU_EnRTrqTrqLm "x0000001D042564D4";
BA_ "SeToolName_SIGNAL" SG_ 2348810243 TSC1EMSTECU_EnRTrqTrqLm "EnRTrqTrqLm";
BA_ "SeToolOwnerSigGroupID_SIGNAL" SG_ 2348810243 TSC1EMSTECU_EnRTrqTrqLm "x0000001D043D7655";
BA_ "SeToolOwnerSigGroup_SIGNAL" SG_ 2348810243 TSC1EMSTECU_EnRTrqTrqLm "TSC1_TECU_EMS";
BA_ "SeToolVersion_SIGNAL" SG_ 2348810243 TSC1EMSTECU_EnRTrqTrqLm "1";
BA_ "GenSigSendType" SG_ 2348810243 TSC1EMSTECU_EnOvrdCtrlM 6;
BA_ "GenSigCycleTime" SG_ 2348810243 TSC1EMSTECU_EnOvrdCtrlM 100;
BA_ "GenSigCycleTimeActive" SG_ 2348810243 TSC1EMSTECU_EnOvrdCtrlM 100;
BA_ "SeToolAncestorID_SIGNAL" SG_ 2348810243 TSC1EMSTECU_EnOvrdCtrlM "x0000001D042564C7";
BA_ "SeToolItemID_SIGNAL" SG_ 2348810243 TSC1EMSTECU_EnOvrdCtrlM "x0000001D042564C7";
BA_ "SeToolName_SIGNAL" SG_ 2348810243 TSC1EMSTECU_EnOvrdCtrlM "EnOvrdCtrlM";
BA_ "SeToolOwnerSigGroupID_SIGNAL" SG_ 2348810243 TSC1EMSTECU_EnOvrdCtrlM "x0000001D043D7655";
BA_ "SeToolOwnerSigGroup_SIGNAL" SG_ 2348810243 TSC1EMSTECU_EnOvrdCtrlM "TSC1_TECU_EMS";
BA_ "SeToolVersion_SIGNAL" SG_ 2348810243 TSC1EMSTECU_EnOvrdCtrlM "1";
BA_ "GenSigSendType" SG_ 2348810251 TSC1EMSABS_EnRSpdSpdLm 7;
BA_ "GenSigStartValue" SG_ 2348810251 TSC1EMSABS_EnRSpdSpdLm 65535;
BA_ "SeToolAncestorID_SIGNAL" SG_ 2348810251 TSC1EMSABS_EnRSpdSpdLm "x0000001D042564D1";
BA_ "SeToolItemID_SIGNAL" SG_ 2348810251 TSC1EMSABS_EnRSpdSpdLm "x0000001D042564D1";
BA_ "SeToolName_SIGNAL" SG_ 2348810251 TSC1EMSABS_EnRSpdSpdLm "EnRSpdSpdLm";
BA_ "SeToolOwnerSigGroupID_SIGNAL" SG_ 2348810251 TSC1EMSABS_EnRSpdSpdLm "x0000001D043D6E46";
BA_ "SeToolOwnerSigGroup_SIGNAL" SG_ 2348810251 TSC1EMSABS_EnRSpdSpdLm "TSC1EMSABS";
BA_ "SeToolVersion_SIGNAL" SG_ 2348810251 TSC1EMSABS_EnRSpdSpdLm "1";
BA_ "GenSigSendType" SG_ 2348810251 TSC1EMSABS_EnOvrdCtrlM 6;
BA_ "GenSigCycleTime" SG_ 2348810251 TSC1EMSABS_EnOvrdCtrlM 100;
BA_ "GenSigCycleTimeActive" SG_ 2348810251 TSC1EMSABS_EnOvrdCtrlM 100;
BA_ "SeToolAncestorID_SIGNAL" SG_ 2348810251 TSC1EMSABS_EnOvrdCtrlM "x0000001D042564C7";
BA_ "SeToolItemID_SIGNAL" SG_ 2348810251 TSC1EMSABS_EnOvrdCtrlM "x0000001D042564C7";
BA_ "SeToolName_SIGNAL" SG_ 2348810251 TSC1EMSABS_EnOvrdCtrlM "EnOvrdCtrlM";
BA_ "SeToolOwnerSigGroupID_SIGNAL" SG_ 2348810251 TSC1EMSABS_EnOvrdCtrlM "x0000001D043D6E46";
BA_ "SeToolOwnerSigGroup_SIGNAL" SG_ 2348810251 TSC1EMSABS_EnOvrdCtrlM "TSC1EMSABS";
BA_ "SeToolVersion_SIGNAL" SG_ 2348810251 TSC1EMSABS_EnOvrdCtrlM "1";
BA_ "GenSigSendType" SG_ 2348810251 TSC1EMSABS_OvrdCtrlMPr 7;
BA_ "GenSigStartValue" SG_ 2348810251 TSC1EMSABS_OvrdCtrlMPr 3;
BA_ "SeToolAncestorID_SIGNAL" SG_ 2348810251 TSC1EMSABS_OvrdCtrlMPr "x0000001D042564CE";
BA_ "SeToolItemID_SIGNAL" SG_ 2348810251 TSC1EMSABS_OvrdCtrlMPr "x0000001D042564CE";
BA_ "SeToolName_SIGNAL" SG_ 2348810251 TSC1EMSABS_OvrdCtrlMPr "OvrdCtrlMPr";
BA_ "SeToolOwnerSigGroupID_SIGNAL" SG_ 2348810251 TSC1EMSABS_OvrdCtrlMPr "x0000001D043D6E46";
BA_ "SeToolOwnerSigGroup_SIGNAL" SG_ 2348810251 TSC1EMSABS_OvrdCtrlMPr "TSC1EMSABS";
BA_ "SeToolVersion_SIGNAL" SG_ 2348810251 TSC1EMSABS_OvrdCtrlMPr "1";
BA_ "GenSigSendType" SG_ 2348810251 TSC1EMSABS_EnRTrqTrqLm 7;
BA_ "GenSigStartValue" SG_ 2348810251 TSC1EMSABS_EnRTrqTrqLm 255;
BA_ "SeToolAncestorID_SIGNAL" SG_ 2348810251 TSC1EMSABS_EnRTrqTrqLm "x0000001D042564D4";
BA_ "SeToolItemID_SIGNAL" SG_ 2348810251 TSC1EMSABS_EnRTrqTrqLm "x0000001D042564D4";
BA_ "SeToolName_SIGNAL" SG_ 2348810251 TSC1EMSABS_EnRTrqTrqLm "EnRTrqTrqLm";
BA_ "SeToolOwnerSigGroupID_SIGNAL" SG_ 2348810251 TSC1EMSABS_EnRTrqTrqLm "x0000001D043D6E46";
BA_ "SeToolOwnerSigGroup_SIGNAL" SG_ 2348810251 TSC1EMSABS_EnRTrqTrqLm "TSC1EMSABS";
BA_ "SeToolVersion_SIGNAL" SG_ 2348810251 TSC1EMSABS_EnRTrqTrqLm "1";
BA_ "GenSigSendType" SG_ 2348810251 TSC1EMSABS_EnRSpdCtrlC 7;
BA_ "SeToolAncestorID_SIGNAL" SG_ 2348810251 TSC1EMSABS_EnRSpdCtrlC "x0000001D042564C9";
BA_ "SeToolItemID_SIGNAL" SG_ 2348810251 TSC1EMSABS_EnRSpdCtrlC "x0000001D042564C9";
BA_ "SeToolName_SIGNAL" SG_ 2348810251 TSC1EMSABS_EnRSpdCtrlC "EnRSpdCtrlC";
BA_ "SeToolOwnerSigGroupID_SIGNAL" SG_ 2348810251 TSC1EMSABS_EnRSpdCtrlC "x0000001D043D6E46";
BA_ "SeToolOwnerSigGroup_SIGNAL" SG_ 2348810251 TSC1EMSABS_EnRSpdCtrlC "TSC1EMSABS";
BA_ "SeToolVersion_SIGNAL" SG_ 2348810251 TSC1EMSABS_EnRSpdCtrlC "1";
BA_ "GenSigSendType" SG_ 2348810413 TSC1EMSDACU_EnRSpdSpdLm 7;
BA_ "GenSigCycleTime" SG_ 2348810413 TSC1EMSDACU_EnRSpdSpdLm 100;
BA_ "GenSigCycleTimeActive" SG_ 2348810413 TSC1EMSDACU_EnRSpdSpdLm 100;
BA_ "GenSigStartValue" SG_ 2348810413 TSC1EMSDACU_EnRSpdSpdLm 65535;
BA_ "SeToolAncestorID_SIGNAL" SG_ 2348810413 TSC1EMSDACU_EnRSpdSpdLm "x0000001D042564D1";
BA_ "SeToolItemID_SIGNAL" SG_ 2348810413 TSC1EMSDACU_EnRSpdSpdLm "x0000001D042564D1";
BA_ "SeToolName_SIGNAL" SG_ 2348810413 TSC1EMSDACU_EnRSpdSpdLm "EnRSpdSpdLm";
BA_ "SeToolOwnerSigGroupID_SIGNAL" SG_ 2348810413 TSC1EMSDACU_EnRSpdSpdLm "x0000001D0440D562";
BA_ "SeToolOwnerSigGroup_SIGNAL" SG_ 2348810413 TSC1EMSDACU_EnRSpdSpdLm "TSC1EMSDACU";
BA_ "SeToolVersion_SIGNAL" SG_ 2348810413 TSC1EMSDACU_EnRSpdSpdLm "1";
BA_ "GenSigSendType" SG_ 2348810413 TSC1EMSDACU_EnOvrdCtrlM 6;
BA_ "GenSigCycleTime" SG_ 2348810413 TSC1EMSDACU_EnOvrdCtrlM 100;
BA_ "GenSigCycleTimeActive" SG_ 2348810413 TSC1EMSDACU_EnOvrdCtrlM 100;
BA_ "SeToolAncestorID_SIGNAL" SG_ 2348810413 TSC1EMSDACU_EnOvrdCtrlM "x0000001D042564C7";
BA_ "SeToolItemID_SIGNAL" SG_ 2348810413 TSC1EMSDACU_EnOvrdCtrlM "x0000001D042564C7";
BA_ "SeToolName_SIGNAL" SG_ 2348810413 TSC1EMSDACU_EnOvrdCtrlM "EnOvrdCtrlM";
BA_ "SeToolOwnerSigGroupID_SIGNAL" SG_ 2348810413 TSC1EMSDACU_EnOvrdCtrlM "x0000001D0440D562";
BA_ "SeToolOwnerSigGroup_SIGNAL" SG_ 2348810413 TSC1EMSDACU_EnOvrdCtrlM "TSC1EMSDACU";
BA_ "SeToolVersion_SIGNAL" SG_ 2348810413 TSC1EMSDACU_EnOvrdCtrlM "1";
BA_ "GenSigSendType" SG_ 2348810413 TSC1EMSDACU_EnRSpdCtrlC 7;
BA_ "GenSigCycleTime" SG_ 2348810413 TSC1EMSDACU_EnRSpdCtrlC 100;
BA_ "GenSigCycleTimeActive" SG_ 2348810413 TSC1EMSDACU_EnRSpdCtrlC 100;
BA_ "SeToolAncestorID_SIGNAL" SG_ 2348810413 TSC1EMSDACU_EnRSpdCtrlC "x0000001D042564C9";
BA_ "SeToolItemID_SIGNAL" SG_ 2348810413 TSC1EMSDACU_EnRSpdCtrlC "x0000001D042564C9";
BA_ "SeToolName_SIGNAL" SG_ 2348810413 TSC1EMSDACU_EnRSpdCtrlC "EnRSpdCtrlC";
BA_ "SeToolOwnerSigGroupID_SIGNAL" SG_ 2348810413 TSC1EMSDACU_EnRSpdCtrlC "x0000001D0440D562";
BA_ "SeToolOwnerSigGroup_SIGNAL" SG_ 2348810413 TSC1EMSDACU_EnRSpdCtrlC "TSC1EMSDACU";
BA_ "SeToolVersion_SIGNAL" SG_ 2348810413 TSC1EMSDACU_EnRSpdCtrlC "1";
BA_ "GenSigSendType" SG_ 2348810413 TSC1EMSDACU_OvrdCtrlMPr 7;
BA_ "GenSigCycleTime" SG_ 2348810413 TSC1EMSDACU_OvrdCtrlMPr 100;
BA_ "GenSigCycleTimeActive" SG_ 2348810413 TSC1EMSDACU_OvrdCtrlMPr 100;
BA_ "GenSigStartValue" SG_ 2348810413 TSC1EMSDACU_OvrdCtrlMPr 3;
BA_ "SeToolAncestorID_SIGNAL" SG_ 2348810413 TSC1EMSDACU_OvrdCtrlMPr "x0000001D042564CE";
BA_ "SeToolItemID_SIGNAL" SG_ 2348810413 TSC1EMSDACU_OvrdCtrlMPr "x0000001D042564CE";
BA_ "SeToolName_SIGNAL" SG_ 2348810413 TSC1EMSDACU_OvrdCtrlMPr "OvrdCtrlMPr";
BA_ "SeToolOwnerSigGroupID_SIGNAL" SG_ 2348810413 TSC1EMSDACU_OvrdCtrlMPr "x0000001D0440D562";
BA_ "SeToolOwnerSigGroup_SIGNAL" SG_ 2348810413 TSC1EMSDACU_OvrdCtrlMPr "TSC1EMSDACU";
BA_ "SeToolVersion_SIGNAL" SG_ 2348810413 TSC1EMSDACU_OvrdCtrlMPr "1";
BA_ "GenSigSendType" SG_ 2348810413 TSC1EMSDACU_EnRTrqTrqLm 7;
BA_ "GenSigCycleTime" SG_ 2348810413 TSC1EMSDACU_EnRTrqTrqLm 100;
BA_ "GenSigCycleTimeActive" SG_ 2348810413 TSC1EMSDACU_EnRTrqTrqLm 100;
BA_ "GenSigStartValue" SG_ 2348810413 TSC1EMSDACU_EnRTrqTrqLm 255;
BA_ "SeToolAncestorID_SIGNAL" SG_ 2348810413 TSC1EMSDACU_EnRTrqTrqLm "x0000001D042564D4";
BA_ "SeToolItemID_SIGNAL" SG_ 2348810413 TSC1EMSDACU_EnRTrqTrqLm "x0000001D042564D4";
BA_ "SeToolName_SIGNAL" SG_ 2348810413 TSC1EMSDACU_EnRTrqTrqLm "EnRTrqTrqLm";
BA_ "SeToolOwnerSigGroupID_SIGNAL" SG_ 2348810413 TSC1EMSDACU_EnRTrqTrqLm "x0000001D0440D562";
BA_ "SeToolOwnerSigGroup_SIGNAL" SG_ 2348810413 TSC1EMSDACU_EnRTrqTrqLm "TSC1EMSDACU";
BA_ "SeToolVersion_SIGNAL" SG_ 2348810413 TSC1EMSDACU_EnRTrqTrqLm "1";
BA_REL_ "GenSigFirstTimeoutTime" BU_SG_REL_ ECM SG_ 2349075203 XBRTECU_EBIMode 4800;
BA_REL_ "GenSigTimeoutTime" BU_SG_REL_ ECM SG_ 2349075203 XBRTECU_EBIMode 1200;
BA_REL_ "GenSigFirstTimeoutTime" BU_SG_REL_ VCM SG_ 2349075203 XBRTECU_EBIMode 4800;
BA_REL_ "GenSigTimeoutTime" BU_SG_REL_ VCM SG_ 2349075203 XBRTECU_EBIMode 1200;
BA_REL_ "GenSigFirstTimeoutTime" BU_SG_REL_ VCM SG_ 2349075203 XBRTECU_MsgCounter 4800;
BA_REL_ "GenSigTimeoutTime" BU_SG_REL_ VCM SG_ 2349075203 XBRTECU_MsgCounter 1200;
BA_REL_ "GenSigFirstTimeoutTime" BU_SG_REL_ ECM SG_ 2349075203 XBRTECU_MsgCounter 4800;
BA_REL_ "GenSigTimeoutTime" BU_SG_REL_ ECM SG_ 2349075203 XBRTECU_MsgCounter 1200;
BA_REL_ "GenSigFirstTimeoutTime" BU_SG_REL_ VCM SG_ 2349075203 XBRTECU_MsgChecksum 4800;
BA_REL_ "GenSigTimeoutTime" BU_SG_REL_ VCM SG_ 2349075203 XBRTECU_MsgChecksum 1200;
BA_REL_ "GenSigFirstTimeoutTime" BU_SG_REL_ ECM SG_ 2349075203 XBRTECU_MsgChecksum 4800;
BA_REL_ "GenSigTimeoutTime" BU_SG_REL_ ECM SG_ 2349075203 XBRTECU_MsgChecksum 1200;
BA_REL_ "GenSigFirstTimeoutTime" BU_SG_REL_ VCM SG_ 2349075203 XBRTECU_ControlMode 4800;
BA_REL_ "GenSigTimeoutTime" BU_SG_REL_ VCM SG_ 2349075203 XBRTECU_ControlMode 1200;
BA_REL_ "GenSigFirstTimeoutTime" BU_SG_REL_ ECM SG_ 2349075203 XBRTECU_ControlMode 4800;
BA_REL_ "GenSigTimeoutTime" BU_SG_REL_ ECM SG_ 2349075203 XBRTECU_ControlMode 1200;
BA_REL_ "GenSigFirstTimeoutTime" BU_SG_REL_ ECM SG_ 2349075203 XBRTECU_ExtAccelDemand 4800;
BA_REL_ "GenSigTimeoutTime" BU_SG_REL_ ECM SG_ 2349075203 XBRTECU_ExtAccelDemand 1200;
BA_REL_ "GenSigFirstTimeoutTime" BU_SG_REL_ VCM SG_ 2349075203 XBRTECU_ExtAccelDemand 4800;
BA_REL_ "GenSigTimeoutTime" BU_SG_REL_ VCM SG_ 2349075203 XBRTECU_ExtAccelDemand 1200;
BA_REL_ "GenSigFirstTimeoutTime" BU_SG_REL_ ECM SG_ 2349075203 XBRTECU_Urgency 4800;
BA_REL_ "GenSigTimeoutTime" BU_SG_REL_ ECM SG_ 2349075203 XBRTECU_Urgency 1200;
BA_REL_ "GenSigFirstTimeoutTime" BU_SG_REL_ VCM SG_ 2349075203 XBRTECU_Urgency 4800;
BA_REL_ "GenSigTimeoutTime" BU_SG_REL_ VCM SG_ 2349075203 XBRTECU_Urgency 1200;
BA_REL_ "GenSigFirstTimeoutTime" BU_SG_REL_ VCM SG_ 2349075203 XBRTECU_Priority 4800;
BA_REL_ "GenSigTimeoutTime" BU_SG_REL_ VCM SG_ 2349075203 XBRTECU_Priority 1200;
BA_REL_ "GenSigFirstTimeoutTime" BU_SG_REL_ ECM SG_ 2349075203 XBRTECU_Priority 4800;
BA_REL_ "GenSigTimeoutTime" BU_SG_REL_ ECM SG_ 2349075203 XBRTECU_Priority 1200;
BA_REL_ "GenSigFirstTimeoutTime" BU_SG_REL_ VCM SG_ 2349075200 XBREMS_ExtAccelDemand 4800;
BA_REL_ "GenSigTimeoutTime" BU_SG_REL_ VCM SG_ 2349075200 XBREMS_ExtAccelDemand 1200;
BA_REL_ "GenSigFirstTimeoutTime" BU_SG_REL_ VCM SG_ 2349075200 XBREMS_Urgency 4800;
BA_REL_ "GenSigTimeoutTime" BU_SG_REL_ VCM SG_ 2349075200 XBREMS_Urgency 1200;
BA_REL_ "GenSigFirstTimeoutTime" BU_SG_REL_ VCM SG_ 2349075200 XBREMS_EBIMode 4800;
BA_REL_ "GenSigTimeoutTime" BU_SG_REL_ VCM SG_ 2349075200 XBREMS_EBIMode 1200;
BA_REL_ "GenSigFirstTimeoutTime" BU_SG_REL_ VCM SG_ 2349075200 XBREMS_MsgCounter 4800;
BA_REL_ "GenSigTimeoutTime" BU_SG_REL_ VCM SG_ 2349075200 XBREMS_MsgCounter 1200;
BA_REL_ "GenSigFirstTimeoutTime" BU_SG_REL_ VCM SG_ 2349075200 XBREMS_Priority 4800;
BA_REL_ "GenSigTimeoutTime" BU_SG_REL_ VCM SG_ 2349075200 XBREMS_Priority 1200;
BA_REL_ "GenSigFirstTimeoutTime" BU_SG_REL_ VCM SG_ 2349075200 XBREMS_MsgChecksum 4800;
BA_REL_ "GenSigTimeoutTime" BU_SG_REL_ VCM SG_ 2349075200 XBREMS_MsgChecksum 1200;
BA_REL_ "GenSigFirstTimeoutTime" BU_SG_REL_ VCM SG_ 2349075200 XBREMS_ControlMode 4800;
BA_REL_ "GenSigTimeoutTime" BU_SG_REL_ VCM SG_ 2349075200 XBREMS_ControlMode 1200;
BA_REL_ "GenSigFirstTimeoutTime" BU_SG_REL_ TCM SG_ 2349075373 XBRDACU_Priority 3000;
BA_REL_ "GenSigTimeoutTime" BU_SG_REL_ TCM SG_ 2349075373 XBRDACU_Priority 1200;
BA_REL_ "GenSigFirstTimeoutTime" BU_SG_REL_ TCM SG_ 2349075373 XBRDACU_MsgChecksum 3000;
BA_REL_ "GenSigTimeoutTime" BU_SG_REL_ TCM SG_ 2349075373 XBRDACU_MsgChecksum 1200;
BA_REL_ "GenSigFirstTimeoutTime" BU_SG_REL_ TCM SG_ 2349075373 XBRDACU_MsgCounter 3000;
BA_REL_ "GenSigTimeoutTime" BU_SG_REL_ TCM SG_ 2349075373 XBRDACU_MsgCounter 1200;
BA_REL_ "GenSigFirstTimeoutTime" BU_SG_REL_ TCM SG_ 2349075373 XBRDACU_EBIMode 3000;
BA_REL_ "GenSigTimeoutTime" BU_SG_REL_ TCM SG_ 2349075373 XBRDACU_EBIMode 1200;
BA_REL_ "GenSigFirstTimeoutTime" BU_SG_REL_ TCM SG_ 2349075373 XBRDACU_ExtAccelDemand 3000;
BA_REL_ "GenSigTimeoutTime" BU_SG_REL_ TCM SG_ 2349075373 XBRDACU_ExtAccelDemand 1200;
BA_REL_ "GenSigFirstTimeoutTime" BU_SG_REL_ TCM SG_ 2349075373 XBRDACU_Urgency 3000;
BA_REL_ "GenSigTimeoutTime" BU_SG_REL_ TCM SG_ 2349075373 XBRDACU_Urgency 1200;
BA_REL_ "GenSigFirstTimeoutTime" BU_SG_REL_ TCM SG_ 2349075373 XBRDACU_ControlMode 3000;
BA_REL_ "GenSigTimeoutTime" BU_SG_REL_ TCM SG_ 2349075373 XBRDACU_ControlMode 1200;
BA_REL_ "GenSigFirstTimeoutTime" BU_SG_REL_ VCM SG_ 2566848256 WaterInFuelAlarm 60000;
BA_REL_ "GenSigTimeoutTime" BU_SG_REL_ VCM SG_ 2566848256 WaterInFuelAlarm 60000;
BA_REL_ "GenSigFirstTimeoutTime" BU_SG_REL_ TCM SG_ 2566845201 VehiclePosSAE_Longitude 6000;
BA_REL_ "GenSigTimeoutTime" BU_SG_REL_ TCM SG_ 2566845201 VehiclePosSAE_Longitude 1500;
BA_REL_ "GenSigFirstTimeoutTime" BU_SG_REL_ TCM SG_ 2566845201 VehiclePosSAE_Latitude 6000;
BA_REL_ "GenSigTimeoutTime" BU_SG_REL_ TCM SG_ 2566845201 VehiclePosSAE_Latitude 1500;
BA_REL_ "GenSigFirstTimeoutTime" BU_SG_REL_ EBS SG_ 2566881297 WheelBasedVehicleSpd_CRC_ISig_1 3000;
BA_REL_ "GenSigTimeoutTime" BU_SG_REL_ EBS SG_ 2566881297 WheelBasedVehicleSpd_CRC_ISig_1 600;
BA_REL_ "GenSigFirstTimeoutTime" BU_SG_REL_ EBS SG_ 2566881297 WheelBasedVehicleSpd_SqC_ISig_1 3000;
BA_REL_ "GenSigTimeoutTime" BU_SG_REL_ EBS SG_ 2566881297 WheelBasedVehicleSpd_SqC_ISig_1 600;
BA_REL_ "GenSigFirstTimeoutTime" BU_SG_REL_ EBS SG_ 2566881297 WheelBasedVehicleSpd_Value_ISig_ 3000;
BA_REL_ "GenSigTimeoutTime" BU_SG_REL_ EBS SG_ 2566881297 WheelBasedVehicleSpd_Value_ISig_ 600;
BA_REL_ "GenSigFirstTimeoutTime" BU_SG_REL_ EBS SG_ 2566881297 EHRASPowerConsIndex 3000;
BA_REL_ "GenSigTimeoutTime" BU_SG_REL_ EBS SG_ 2566881297 EHRASPowerConsIndex 600;
BA_REL_ "GenSigFirstTimeoutTime" BU_SG_REL_ ECM SG_ 2566897681 OBDUTCTime_Month 12000;
BA_REL_ "GenSigTimeoutTime" BU_SG_REL_ ECM SG_ 2566897681 OBDUTCTime_Month 3000;
BA_REL_ "GenSigFirstTimeoutTime" BU_SG_REL_ ACM SG_ 2566897681 OBDUTCTime_Month 12000;
BA_REL_ "GenSigTimeoutTime" BU_SG_REL_ ACM SG_ 2566897681 OBDUTCTime_Month 3000;
BA_REL_ "GenSigFirstTimeoutTime" BU_SG_REL_ ECM SG_ 2566897681 OBDUTCTime_Seconds 12000;
BA_REL_ "GenSigTimeoutTime" BU_SG_REL_ ECM SG_ 2566897681 OBDUTCTime_Seconds 3000;
BA_REL_ "GenSigFirstTimeoutTime" BU_SG_REL_ ACM SG_ 2566897681 OBDUTCTime_Seconds 12000;
BA_REL_ "GenSigTimeoutTime" BU_SG_REL_ ACM SG_ 2566897681 OBDUTCTime_Seconds 3000;
BA_REL_ "GenSigFirstTimeoutTime" BU_SG_REL_ ACM SG_ 2566897681 OBDUTCTime_Year 12000;
BA_REL_ "GenSigTimeoutTime" BU_SG_REL_ ACM SG_ 2566897681 OBDUTCTime_Year 3000;
BA_REL_ "GenSigFirstTimeoutTime" BU_SG_REL_ ECM SG_ 2566897681 OBDUTCTime_Year 12000;
BA_REL_ "GenSigTimeoutTime" BU_SG_REL_ ECM SG_ 2566897681 OBDUTCTime_Year 3000;
BA_REL_ "GenSigFirstTimeoutTime" BU_SG_REL_ ECM SG_ 2566897681 OBDUTCTime_Hours 12000;
BA_REL_ "GenSigTimeoutTime" BU_SG_REL_ ECM SG_ 2566897681 OBDUTCTime_Hours 3000;
BA_REL_ "GenSigFirstTimeoutTime" BU_SG_REL_ ACM SG_ 2566897681 OBDUTCTime_Hours 12000;
BA_REL_ "GenSigTimeoutTime" BU_SG_REL_ ACM SG_ 2566897681 OBDUTCTime_Hours 3000;
BA_REL_ "GenSigFirstTimeoutTime" BU_SG_REL_ ECM SG_ 2566897681 OBDUTCTime_Minutes 12000;
BA_REL_ "GenSigTimeoutTime" BU_SG_REL_ ECM SG_ 2566897681 OBDUTCTime_Minutes 3000;
BA_REL_ "GenSigFirstTimeoutTime" BU_SG_REL_ ACM SG_ 2566897681 OBDUTCTime_Minutes 12000;
BA_REL_ "GenSigTimeoutTime" BU_SG_REL_ ACM SG_ 2566897681 OBDUTCTime_Minutes 3000;
BA_REL_ "GenSigFirstTimeoutTime" BU_SG_REL_ ACM SG_ 2566897681 OBDUTCTime_Day 12000;
BA_REL_ "GenSigTimeoutTime" BU_SG_REL_ ACM SG_ 2566897681 OBDUTCTime_Day 3000;
BA_REL_ "GenSigFirstTimeoutTime" BU_SG_REL_ ECM SG_ 2566897681 OBDUTCTime_Day 12000;
BA_REL_ "GenSigTimeoutTime" BU_SG_REL_ ECM SG_ 2566897681 OBDUTCTime_Day 3000;
BA_REL_ "GenSigFirstTimeoutTime" BU_SG_REL_ EBS SG_ 2365535249 DrvAxlBrkPressure_SqC 3000;
BA_REL_ "GenSigTimeoutTime" BU_SG_REL_ EBS SG_ 2365535249 DrvAxlBrkPressure_SqC 300;
BA_REL_ "GenSigFirstTimeoutTime" BU_SG_REL_ EBS SG_ 2365535249 DrvAxlBrkPressure_Rqst 3000;
BA_REL_ "GenSigTimeoutTime" BU_SG_REL_ EBS SG_ 2365535249 DrvAxlBrkPressure_Rqst 300;
BA_REL_ "GenSigFirstTimeoutTime" BU_SG_REL_ EBS SG_ 2365535249 TrailerBrkPressure_SqC 3000;
BA_REL_ "GenSigTimeoutTime" BU_SG_REL_ EBS SG_ 2365535249 TrailerBrkPressure_SqC 300;
BA_REL_ "GenSigFirstTimeoutTime" BU_SG_REL_ EBS SG_ 2365535249 TrailerBrkPressure_Rqst 3000;
BA_REL_ "GenSigTimeoutTime" BU_SG_REL_ EBS SG_ 2365535249 TrailerBrkPressure_Rqst 300;
BA_REL_ "GenSigFirstTimeoutTime" BU_SG_REL_ EBS SG_ 2365535249 DrvAxlBrkPressure_CRC 3000;
BA_REL_ "GenSigTimeoutTime" BU_SG_REL_ EBS SG_ 2365535249 DrvAxlBrkPressure_CRC 300;
BA_REL_ "GenSigFirstTimeoutTime" BU_SG_REL_ EBS SG_ 2365535249 TrailerBrkPressure_CRC 3000;
BA_REL_ "GenSigTimeoutTime" BU_SG_REL_ EBS SG_ 2365535249 TrailerBrkPressure_CRC 300;
BA_REL_ "GenSigFirstTimeoutTime" BU_SG_REL_ TCM SG_ 2499788567 DrvrRetarderBrakeBlending_rqst_I 3000;
BA_REL_ "GenSigTimeoutTime" BU_SG_REL_ TCM SG_ 2499788567 DrvrRetarderBrakeBlending_rqst_I 450;
BA_REL_ "GenSigFirstTimeoutTime" BU_SG_REL_ EBS SG_ 2499788567 DrvrRetarderBrakeBlending_rqst_I 3000;
BA_REL_ "GenSigTimeoutTime" BU_SG_REL_ EBS SG_ 2499788567 DrvrRetarderBrakeBlending_rqst_I 450;
BA_REL_ "GenSigFirstTimeoutTime" BU_SG_REL_ EBS SG_ 2499788567 Trailer2LiftAxle2PosReq 3000;
BA_REL_ "GenSigTimeoutTime" BU_SG_REL_ EBS SG_ 2499788567 Trailer2LiftAxle2PosReq 450;
BA_REL_ "GenSigFirstTimeoutTime" BU_SG_REL_ EBS SG_ 2499788567 Trailer4LiftAxle2PosReq 3000;
BA_REL_ "GenSigTimeoutTime" BU_SG_REL_ EBS SG_ 2499788567 Trailer4LiftAxle2PosReq 450;
BA_REL_ "GenSigFirstTimeoutTime" BU_SG_REL_ TCM SG_ 2499788567 GearLeverPositionBackup 3000;
BA_REL_ "GenSigTimeoutTime" BU_SG_REL_ TCM SG_ 2499788567 GearLeverPositionBackup 450;
BA_REL_ "GenSigFirstTimeoutTime" BU_SG_REL_ EBS SG_ 2499788567 Trailer2LiftAxle1PosReq 3000;
BA_REL_ "GenSigTimeoutTime" BU_SG_REL_ EBS SG_ 2499788567 Trailer2LiftAxle1PosReq 450;
BA_REL_ "GenSigFirstTimeoutTime" BU_SG_REL_ EBS SG_ 2499788567 Trailer5LiftAxle2PosReq 3000;
BA_REL_ "GenSigTimeoutTime" BU_SG_REL_ EBS SG_ 2499788567 Trailer5LiftAxle2PosReq 450;
BA_REL_ "GenSigFirstTimeoutTime" BU_SG_REL_ TCM SG_ 2499788567 GearLeverPos2Backup_CRC 3000;
BA_REL_ "GenSigTimeoutTime" BU_SG_REL_ TCM SG_ 2499788567 GearLeverPos2Backup_CRC 450;
BA_REL_ "GenSigFirstTimeoutTime" BU_SG_REL_ EBS SG_ 2499788567 DriverRetarderRequest_ISig_1 3000;
BA_REL_ "GenSigTimeoutTime" BU_SG_REL_ EBS SG_ 2499788567 DriverRetarderRequest_ISig_1 450;
BA_REL_ "GenSigFirstTimeoutTime" BU_SG_REL_ ECM SG_ 2499788567 DriverRetarderRequest_ISig_1 3000;
BA_REL_ "GenSigTimeoutTime" BU_SG_REL_ ECM SG_ 2499788567 DriverRetarderRequest_ISig_1 450;
BA_REL_ "GenSigFirstTimeoutTime" BU_SG_REL_ TCM SG_ 2499788567 DriverRetarderRequest_ISig_1 3000;
BA_REL_ "GenSigTimeoutTime" BU_SG_REL_ TCM SG_ 2499788567 DriverRetarderRequest_ISig_1 450;
BA_REL_ "GenSigFirstTimeoutTime" BU_SG_REL_ ACM SG_ 2499788567 DriverRetarderRequest_ISig_1 3000;
BA_REL_ "GenSigTimeoutTime" BU_SG_REL_ ACM SG_ 2499788567 DriverRetarderRequest_ISig_1 450;
BA_REL_ "GenSigFirstTimeoutTime" BU_SG_REL_ EBS SG_ 2499788567 Trailer1LiftAxl2ePosReq 3000;
BA_REL_ "GenSigTimeoutTime" BU_SG_REL_ EBS SG_ 2499788567 Trailer1LiftAxl2ePosReq 450;
BA_REL_ "GenSigFirstTimeoutTime" BU_SG_REL_ TCM SG_ 2499788567 GearLeverPos2Backup_SqC 3000;
BA_REL_ "GenSigTimeoutTime" BU_SG_REL_ TCM SG_ 2499788567 GearLeverPos2Backup_SqC 450;
BA_REL_ "GenSigFirstTimeoutTime" BU_SG_REL_ EBS SG_ 2499788567 Trailer1LiftAxle1PosReq 3000;
BA_REL_ "GenSigTimeoutTime" BU_SG_REL_ EBS SG_ 2499788567 Trailer1LiftAxle1PosReq 450;
BA_REL_ "GenSigFirstTimeoutTime" BU_SG_REL_ TCM SG_ 2499788567 DrvrRetarderBrakeProgram_rqst_IS 3000;
BA_REL_ "GenSigTimeoutTime" BU_SG_REL_ TCM SG_ 2499788567 DrvrRetarderBrakeProgram_rqst_IS 450;
BA_REL_ "GenSigFirstTimeoutTime" BU_SG_REL_ EBS SG_ 2499788567 Trailer4LiftAxle1PosReq 3000;
BA_REL_ "GenSigTimeoutTime" BU_SG_REL_ EBS SG_ 2499788567 Trailer4LiftAxle1PosReq 450;
BA_REL_ "GenSigFirstTimeoutTime" BU_SG_REL_ EBS SG_ 2499788567 EHERearAxleSteeringFuncStatus 3000;
BA_REL_ "GenSigTimeoutTime" BU_SG_REL_ EBS SG_ 2499788567 EHERearAxleSteeringFuncStatus 450;
BA_REL_ "GenSigFirstTimeoutTime" BU_SG_REL_ EBS SG_ 2499788567 EHRearAxleSteeringFuncStatus 3000;
BA_REL_ "GenSigTimeoutTime" BU_SG_REL_ EBS SG_ 2499788567 EHRearAxleSteeringFuncStatus 450;
BA_REL_ "GenSigFirstTimeoutTime" BU_SG_REL_ EBS SG_ 2499788567 Trailer5LiftAxle1PosReq 3000;
BA_REL_ "GenSigTimeoutTime" BU_SG_REL_ EBS SG_ 2499788567 Trailer5LiftAxle1PosReq 450;
BA_REL_ "GenSigFirstTimeoutTime" BU_SG_REL_ EBS SG_ 2499788567 Trailer3LiftAxle1PosReq 3000;
BA_REL_ "GenSigTimeoutTime" BU_SG_REL_ EBS SG_ 2499788567 Trailer3LiftAxle1PosReq 450;
BA_REL_ "GenSigFirstTimeoutTime" BU_SG_REL_ TCM SG_ 2499788567 GearLeverPos2Backup_Rqst 3000;
BA_REL_ "GenSigTimeoutTime" BU_SG_REL_ TCM SG_ 2499788567 GearLeverPos2Backup_Rqst 450;
BA_REL_ "GenSigFirstTimeoutTime" BU_SG_REL_ EBS SG_ 2499788567 Trailer3LiftAxle2PosReq 3000;
BA_REL_ "GenSigTimeoutTime" BU_SG_REL_ EBS SG_ 2499788567 Trailer3LiftAxle2PosReq 450;
BA_REL_ "GenSigFirstTimeoutTime" BU_SG_REL_ EBS SG_ 2566899729 LoadCalibFail_WrongHeight 24000;
BA_REL_ "GenSigTimeoutTime" BU_SG_REL_ EBS SG_ 2566899729 LoadCalibFail_WrongHeight 6000;
BA_REL_ "GenSigFirstTimeoutTime" BU_SG_REL_ EBS SG_ 2566899729 Trailer5CalibStoreReq_ScaleLoad 24000;
BA_REL_ "GenSigTimeoutTime" BU_SG_REL_ EBS SG_ 2566899729 Trailer5CalibStoreReq_ScaleLoad 6000;
BA_REL_ "GenSigFirstTimeoutTime" BU_SG_REL_ EBS SG_ 2566899729 LoadCalibrationFeedback_ISig_1 24000;
BA_REL_ "GenSigTimeoutTime" BU_SG_REL_ EBS SG_ 2566899729 LoadCalibrationFeedback_ISig_1 6000;
BA_REL_ "GenSigFirstTimeoutTime" BU_SG_REL_ EBS SG_ 2566899729 LoadCalibFail_InternalFailure 24000;
BA_REL_ "GenSigTimeoutTime" BU_SG_REL_ EBS SG_ 2566899729 LoadCalibFail_InternalFailure 6000;
BA_REL_ "GenSigFirstTimeoutTime" BU_SG_REL_ EBS SG_ 2566899729 Trailer5CalibStoreReq_CalibType 24000;
BA_REL_ "GenSigTimeoutTime" BU_SG_REL_ EBS SG_ 2566899729 Trailer5CalibStoreReq_CalibType 6000;
BA_REL_ "GenSigFirstTimeoutTime" BU_SG_REL_ EBS SG_ 2566899729 LoadCalibFail_Range 24000;
BA_REL_ "GenSigTimeoutTime" BU_SG_REL_ EBS SG_ 2566899729 LoadCalibFail_Range 6000;
BA_REL_ "GenSigFirstTimeoutTime" BU_SG_REL_ EBS SG_ 2566899729 LoadCalibFail_InMotion 24000;
BA_REL_ "GenSigTimeoutTime" BU_SG_REL_ EBS SG_ 2566899729 LoadCalibFail_InMotion 6000;
BA_REL_ "GenSigFirstTimeoutTime" BU_SG_REL_ EBS SG_ 2566899729 Trailer5CalibStoreReq_AxleId 24000;
BA_REL_ "GenSigTimeoutTime" BU_SG_REL_ EBS SG_ 2566899729 Trailer5CalibStoreReq_AxleId 6000;
BA_REL_ "GenSigFirstTimeoutTime" BU_SG_REL_ EBS SG_ 2566899729 LoadCalibFail_WrongVM 24000;
BA_REL_ "GenSigTimeoutTime" BU_SG_REL_ EBS SG_ 2566899729 LoadCalibFail_WrongVM 6000;
BA_REL_ "GenSigFirstTimeoutTime" BU_SG_REL_ EBS SG_ 2566899729 LoadCalibFail_OutOfMemory 24000;
BA_REL_ "GenSigTimeoutTime" BU_SG_REL_ EBS SG_ 2566899729 LoadCalibFail_OutOfMemory 6000;
BA_REL_ "GenSigFirstTimeoutTime" BU_SG_REL_ EBS SG_ 2566899473 Trailer3CalibStoreReq_CalibType 24000;
BA_REL_ "GenSigTimeoutTime" BU_SG_REL_ EBS SG_ 2566899473 Trailer3CalibStoreReq_CalibType 6000;
BA_REL_ "GenSigFirstTimeoutTime" BU_SG_REL_ EBS SG_ 2566899473 Trailer4CalibStoreReq_CalibType 24000;
BA_REL_ "GenSigTimeoutTime" BU_SG_REL_ EBS SG_ 2566899473 Trailer4CalibStoreReq_CalibType 6000;
BA_REL_ "GenSigFirstTimeoutTime" BU_SG_REL_ EBS SG_ 2566899473 Trailer4CalibStoreReq_AxleId 24000;
BA_REL_ "GenSigTimeoutTime" BU_SG_REL_ EBS SG_ 2566899473 Trailer4CalibStoreReq_AxleId 6000;
BA_REL_ "GenSigFirstTimeoutTime" BU_SG_REL_ EBS SG_ 2566899473 Trailer3CalibStoreReq_AxleId 24000;
BA_REL_ "GenSigTimeoutTime" BU_SG_REL_ EBS SG_ 2566899473 Trailer3CalibStoreReq_AxleId 6000;
BA_REL_ "GenSigFirstTimeoutTime" BU_SG_REL_ EBS SG_ 2566899473 Trailer4CalibStoreReq_ScaleLoad 24000;
BA_REL_ "GenSigTimeoutTime" BU_SG_REL_ EBS SG_ 2566899473 Trailer4CalibStoreReq_ScaleLoad 6000;
BA_REL_ "GenSigFirstTimeoutTime" BU_SG_REL_ EBS SG_ 2566899473 Trailer3CalibStoreReq_ScaleLoad 24000;
BA_REL_ "GenSigTimeoutTime" BU_SG_REL_ EBS SG_ 2566899473 Trailer3CalibStoreReq_ScaleLoad 6000;
BA_REL_ "GenSigFirstTimeoutTime" BU_SG_REL_ EBS SG_ 2566899217 Trailer1CalibStoreReq_AxleId 24000;
BA_REL_ "GenSigTimeoutTime" BU_SG_REL_ EBS SG_ 2566899217 Trailer1CalibStoreReq_AxleId 6000;
BA_REL_ "GenSigFirstTimeoutTime" BU_SG_REL_ EBS SG_ 2566899217 Trailer1CalibStoreReq_ScaleLoad 24000;
BA_REL_ "GenSigTimeoutTime" BU_SG_REL_ EBS SG_ 2566899217 Trailer1CalibStoreReq_ScaleLoad 6000;
BA_REL_ "GenSigFirstTimeoutTime" BU_SG_REL_ EBS SG_ 2566899217 Trailer2CalibStoreReq_ScaleLoad 24000;
BA_REL_ "GenSigTimeoutTime" BU_SG_REL_ EBS SG_ 2566899217 Trailer2CalibStoreReq_ScaleLoad 6000;
BA_REL_ "GenSigFirstTimeoutTime" BU_SG_REL_ EBS SG_ 2566899217 Trailer1CalibStoreReq_CalibType 24000;
BA_REL_ "GenSigTimeoutTime" BU_SG_REL_ EBS SG_ 2566899217 Trailer1CalibStoreReq_CalibType 6000;
BA_REL_ "GenSigFirstTimeoutTime" BU_SG_REL_ EBS SG_ 2566899217 Trailer2CalibStoreReq_AxleId 24000;
BA_REL_ "GenSigTimeoutTime" BU_SG_REL_ EBS SG_ 2566899217 Trailer2CalibStoreReq_AxleId 6000;
BA_REL_ "GenSigFirstTimeoutTime" BU_SG_REL_ EBS SG_ 2566899217 Trailer2CalibStoreReq_CalibType 24000;
BA_REL_ "GenSigTimeoutTime" BU_SG_REL_ EBS SG_ 2566899217 Trailer2CalibStoreReq_CalibType 6000;
BA_REL_ "GenSigFirstTimeoutTime" BU_SG_REL_ ECM SG_ 2499751697 EngineStopReqBackup 3000;
BA_REL_ "GenSigTimeoutTime" BU_SG_REL_ ECM SG_ 2499751697 EngineStopReqBackup 600;
BA_REL_ "GenSigFirstTimeoutTime" BU_SG_REL_ ECM SG_ 2499751697 TrailerWithoutABS_ISig_1 3000;
BA_REL_ "GenSigTimeoutTime" BU_SG_REL_ ECM SG_ 2499751697 TrailerWithoutABS_ISig_1 600;
BA_REL_ "GenSigFirstTimeoutTime" BU_SG_REL_ TCM SG_ 2499751697 TrailerWithoutABS_ISig_1 3000;
BA_REL_ "GenSigTimeoutTime" BU_SG_REL_ TCM SG_ 2499751697 TrailerWithoutABS_ISig_1 600;
BA_REL_ "GenSigFirstTimeoutTime" BU_SG_REL_ EBS SG_ 2499751697 TrailerWithoutABS_ISig_1 3000;
BA_REL_ "GenSigTimeoutTime" BU_SG_REL_ EBS SG_ 2499751697 TrailerWithoutABS_ISig_1 600;
BA_REL_ "GenSigFirstTimeoutTime" BU_SG_REL_ ECM SG_ 2499751697 LowAirPressureAlert_ISig_1 3000;
BA_REL_ "GenSigTimeoutTime" BU_SG_REL_ ECM SG_ 2499751697 LowAirPressureAlert_ISig_1 600;
BA_REL_ "GenSigFirstTimeoutTime" BU_SG_REL_ EBS SG_ 2499751697 ACC_SGO_Status_ISig_1 3000;
BA_REL_ "GenSigTimeoutTime" BU_SG_REL_ EBS SG_ 2499751697 ACC_SGO_Status_ISig_1 600;
BA_REL_ "GenSigFirstTimeoutTime" BU_SG_REL_ TCM SG_ 2499751697 ACC_SGO_Status_ISig_1 3000;
BA_REL_ "GenSigTimeoutTime" BU_SG_REL_ TCM SG_ 2499751697 ACC_SGO_Status_ISig_1 600;
BA_REL_ "GenSigFirstTimeoutTime" BU_SG_REL_ EBS SG_ 2499751697 DifferentialLockStateFrAxle2 3000;
BA_REL_ "GenSigTimeoutTime" BU_SG_REL_ EBS SG_ 2499751697 DifferentialLockStateFrAxle2 600;
BA_REL_ "GenSigFirstTimeoutTime" BU_SG_REL_ EBS SG_ 2499751697 SetHSAOperation_ISig_1 3000;
BA_REL_ "GenSigTimeoutTime" BU_SG_REL_ EBS SG_ 2499751697 SetHSAOperation_ISig_1 600;
BA_REL_ "GenSigFirstTimeoutTime" BU_SG_REL_ EBS SG_ 2499751697 CtaBs_HSABbRequest 3000;
BA_REL_ "GenSigTimeoutTime" BU_SG_REL_ EBS SG_ 2499751697 CtaBs_HSABbRequest 600;
BA_REL_ "GenSigFirstTimeoutTime" BU_SG_REL_ ECM SG_ 2499751697 AWBEnableRequest_ISig_1 3000;
BA_REL_ "GenSigTimeoutTime" BU_SG_REL_ ECM SG_ 2499751697 AWBEnableRequest_ISig_1 600;
BA_REL_ "GenSigFirstTimeoutTime" BU_SG_REL_ TCM SG_ 2499751697 AWBEnableRequest_ISig_1 3000;
BA_REL_ "GenSigTimeoutTime" BU_SG_REL_ TCM SG_ 2499751697 AWBEnableRequest_ISig_1 600;
BA_REL_ "GenSigFirstTimeoutTime" BU_SG_REL_ TCM SG_ 2499751697 RearPropulsionStat_Rear2Axle_ISi 3000;
BA_REL_ "GenSigTimeoutTime" BU_SG_REL_ TCM SG_ 2499751697 RearPropulsionStat_Rear2Axle_ISi 600;
BA_REL_ "GenSigFirstTimeoutTime" BU_SG_REL_ ECM SG_ 2499751697 RearPropulsionStat_Rear2Axle_ISi 3000;
BA_REL_ "GenSigTimeoutTime" BU_SG_REL_ ECM SG_ 2499751697 RearPropulsionStat_Rear2Axle_ISi 600;
BA_REL_ "GenSigFirstTimeoutTime" BU_SG_REL_ EBS SG_ 2499751697 RearPropulsionStat_Rear2Axle_ISi 3000;
BA_REL_ "GenSigTimeoutTime" BU_SG_REL_ EBS SG_ 2499751697 RearPropulsionStat_Rear2Axle_ISi 600;
BA_REL_ "GenSigFirstTimeoutTime" BU_SG_REL_ TCM SG_ 2499751697 DifferentialLockStateCentral_ISi 3000;
BA_REL_ "GenSigTimeoutTime" BU_SG_REL_ TCM SG_ 2499751697 DifferentialLockStateCentral_ISi 600;
BA_REL_ "GenSigFirstTimeoutTime" BU_SG_REL_ ECM SG_ 2499751697 DifferentialLockStateCentral_ISi 3000;
BA_REL_ "GenSigTimeoutTime" BU_SG_REL_ ECM SG_ 2499751697 DifferentialLockStateCentral_ISi 600;
BA_REL_ "GenSigFirstTimeoutTime" BU_SG_REL_ EBS SG_ 2499751697 DifferentialLockStateCentral_ISi 3000;
BA_REL_ "GenSigTimeoutTime" BU_SG_REL_ EBS SG_ 2499751697 DifferentialLockStateCentral_ISi 600;
BA_REL_ "GenSigFirstTimeoutTime" BU_SG_REL_ TCM SG_ 2499751697 CentralRearDiffLock_stat_ISig_1 3000;
BA_REL_ "GenSigTimeoutTime" BU_SG_REL_ TCM SG_ 2499751697 CentralRearDiffLock_stat_ISig_1 600;
BA_REL_ "GenSigFirstTimeoutTime" BU_SG_REL_ EBS SG_ 2499751697 ACCHSARequest 3000;
BA_REL_ "GenSigTimeoutTime" BU_SG_REL_ EBS SG_ 2499751697 ACCHSARequest 600;
BA_REL_ "GenSigFirstTimeoutTime" BU_SG_REL_ EBS SG_ 2499751697 DifferentialLockStateFrAxle1_ISi 3000;
BA_REL_ "GenSigTimeoutTime" BU_SG_REL_ EBS SG_ 2499751697 DifferentialLockStateFrAxle1_ISi 600;
BA_REL_ "GenSigFirstTimeoutTime" BU_SG_REL_ TCM SG_ 2499751697 RearAxle2DiffLock_stat_ISig_1 3000;
BA_REL_ "GenSigTimeoutTime" BU_SG_REL_ TCM SG_ 2499751697 RearAxle2DiffLock_stat_ISig_1 600;
BA_REL_ "GenSigFirstTimeoutTime" BU_SG_REL_ EBS SG_ 2499751697 TrailerConnected_ISig_1 3000;
BA_REL_ "GenSigTimeoutTime" BU_SG_REL_ EBS SG_ 2499751697 TrailerConnected_ISig_1 600;
BA_REL_ "GenSigFirstTimeoutTime" BU_SG_REL_ EBS SG_ 2499751697 DifferentialLockStateCentral2 3000;
BA_REL_ "GenSigTimeoutTime" BU_SG_REL_ EBS SG_ 2499751697 DifferentialLockStateCentral2 600;
BA_REL_ "GenSigFirstTimeoutTime" BU_SG_REL_ EBS SG_ 2499751697 RearPropulsionStat_Rear3Axle_ISi 3000;
BA_REL_ "GenSigTimeoutTime" BU_SG_REL_ EBS SG_ 2499751697 RearPropulsionStat_Rear3Axle_ISi 600;
BA_REL_ "GenSigFirstTimeoutTime" BU_SG_REL_ ECM SG_ 2499751697 RearPropulsionStat_Rear3Axle_ISi 3000;
BA_REL_ "GenSigTimeoutTime" BU_SG_REL_ ECM SG_ 2499751697 RearPropulsionStat_Rear3Axle_ISi 600;
BA_REL_ "GenSigFirstTimeoutTime" BU_SG_REL_ TCM SG_ 2499751697 RearPropulsionStat_Rear3Axle_ISi 3000;
BA_REL_ "GenSigTimeoutTime" BU_SG_REL_ TCM SG_ 2499751697 RearPropulsionStat_Rear3Axle_ISi 600;
BA_REL_ "GenSigFirstTimeoutTime" BU_SG_REL_ EBS SG_ 2499751697 RearPropulsionStat_Rear1Axle_ISi 3000;
BA_REL_ "GenSigTimeoutTime" BU_SG_REL_ EBS SG_ 2499751697 RearPropulsionStat_Rear1Axle_ISi 600;
BA_REL_ "GenSigFirstTimeoutTime" BU_SG_REL_ ECM SG_ 2499751697 RearPropulsionStat_Rear1Axle_ISi 3000;
BA_REL_ "GenSigTimeoutTime" BU_SG_REL_ ECM SG_ 2499751697 RearPropulsionStat_Rear1Axle_ISi 600;
BA_REL_ "GenSigFirstTimeoutTime" BU_SG_REL_ TCM SG_ 2499751697 RearPropulsionStat_Rear1Axle_ISi 3000;
BA_REL_ "GenSigTimeoutTime" BU_SG_REL_ TCM SG_ 2499751697 RearPropulsionStat_Rear1Axle_ISi 600;
BA_REL_ "GenSigFirstTimeoutTime" BU_SG_REL_ TCM SG_ 2499751697 RearAxle1DiffLock_stat_ISig_1 3000;
BA_REL_ "GenSigTimeoutTime" BU_SG_REL_ TCM SG_ 2499751697 RearAxle1DiffLock_stat_ISig_1 600;
BA_REL_ "GenSigFirstTimeoutTime" BU_SG_REL_ EBS SG_ 2566897425 StaticTrailerBrake_rqst 12000;
BA_REL_ "GenSigTimeoutTime" BU_SG_REL_ EBS SG_ 2566897425 StaticTrailerBrake_rqst 3000;
BA_REL_ "GenSigFirstTimeoutTime" BU_SG_REL_ EBS SG_ 2566897425 OBD_Timestamp_ISig_1 12000;
BA_REL_ "GenSigTimeoutTime" BU_SG_REL_ EBS SG_ 2566897425 OBD_Timestamp_ISig_1 3000;
BA_REL_ "GenSigFirstTimeoutTime" BU_SG_REL_ EBS SG_ 2566897425 StretchBrakeEnable_rqst 12000;
BA_REL_ "GenSigTimeoutTime" BU_SG_REL_ EBS SG_ 2566897425 StretchBrakeEnable_rqst 3000;
BA_REL_ "GenSigFirstTimeoutTime" BU_SG_REL_ TCM SG_ 2566897425 AxleLoadStatus_ISig_1 12000;
BA_REL_ "GenSigTimeoutTime" BU_SG_REL_ TCM SG_ 2566897425 AxleLoadStatus_ISig_1 3000;
BA_REL_ "GenSigFirstTimeoutTime" BU_SG_REL_ EBS SG_ 2566897425 AxleLoadStatus_ISig_1 12000;
BA_REL_ "GenSigTimeoutTime" BU_SG_REL_ EBS SG_ 2566897425 AxleLoadStatus_ISig_1 3000;
BA_REL_ "GenSigFirstTimeoutTime" BU_SG_REL_ ECM SG_ 2566897425 FuelLevel_ISig_1 12000;
BA_REL_ "GenSigTimeoutTime" BU_SG_REL_ ECM SG_ 2566897425 FuelLevel_ISig_1 3000;
BA_REL_ "GenSigFirstTimeoutTime" BU_SG_REL_ EBS SG_ 2566897425 FuelLevel_ISig_1 12000;
BA_REL_ "GenSigTimeoutTime" BU_SG_REL_ EBS SG_ 2566897425 FuelLevel_ISig_1 3000;
BA_REL_ "GenSigFirstTimeoutTime" BU_SG_REL_ EBS SG_ 2298429457 AcceleratorPedalPosition1_ISig_1 3000;
BA_REL_ "GenSigTimeoutTime" BU_SG_REL_ EBS SG_ 2298429457 AcceleratorPedalPosition1_ISig_1 60;
BA_REL_ "GenSigFirstTimeoutTime" BU_SG_REL_ TCM SG_ 2298429457 AcceleratorPedalPosition1_ISig_1 3000;
BA_REL_ "GenSigTimeoutTime" BU_SG_REL_ TCM SG_ 2298429457 AcceleratorPedalPosition1_ISig_1 60;
BA_REL_ "GenSigFirstTimeoutTime" BU_SG_REL_ ECM SG_ 2298429457 AcceleratorPedalPosition1_ISig_1 3000;
BA_REL_ "GenSigTimeoutTime" BU_SG_REL_ ECM SG_ 2298429457 AcceleratorPedalPosition1_ISig_1 60;
BA_REL_ "GenSigFirstTimeoutTime" BU_SG_REL_ EBS SG_ 2298429457 SWBrakeSwitch_ISig_1 3000;
BA_REL_ "GenSigTimeoutTime" BU_SG_REL_ EBS SG_ 2298429457 SWBrakeSwitch_ISig_1 500;
BA_REL_ "GenSigFirstTimeoutTime" BU_SG_REL_ TCM SG_ 2298429457 AcceleratorPedalLowIdleSwitch_IS 3000;
BA_REL_ "GenSigTimeoutTime" BU_SG_REL_ TCM SG_ 2298429457 AcceleratorPedalLowIdleSwitch_IS 60;
BA_REL_ "GenSigFirstTimeoutTime" BU_SG_REL_ TCM SG_ 2298429457 BrakePedalPosition_ISig_1 3000;
BA_REL_ "GenSigTimeoutTime" BU_SG_REL_ TCM SG_ 2298429457 BrakePedalPosition_ISig_1 60;
BA_REL_ "GenSigFirstTimeoutTime" BU_SG_REL_ EBS SG_ 2298429457 BrakePedalPosition_ISig_1 3000;
BA_REL_ "GenSigTimeoutTime" BU_SG_REL_ EBS SG_ 2298429457 BrakePedalPosition_ISig_1 60;
BA_REL_ "GenSigFirstTimeoutTime" BU_SG_REL_ ACM SG_ 2298429457 VehicleMode_ISig_1 3000;
BA_REL_ "GenSigTimeoutTime" BU_SG_REL_ ACM SG_ 2298429457 VehicleMode_ISig_1 60;
BA_REL_ "GenSigFirstTimeoutTime" BU_SG_REL_ TCM SG_ 2298429457 VehicleMode_ISig_1 3000;
BA_REL_ "GenSigTimeoutTime" BU_SG_REL_ TCM SG_ 2298429457 VehicleMode_ISig_1 60;
BA_REL_ "GenSigFirstTimeoutTime" BU_SG_REL_ ECM SG_ 2298429457 VehicleMode_ISig_1 3000;
BA_REL_ "GenSigTimeoutTime" BU_SG_REL_ ECM SG_ 2298429457 VehicleMode_ISig_1 60;
BA_REL_ "GenSigFirstTimeoutTime" BU_SG_REL_ EBS SG_ 2298429457 VehicleMode_ISig_1 3000;
BA_REL_ "GenSigTimeoutTime" BU_SG_REL_ EBS SG_ 2298429457 VehicleMode_ISig_1 60;
BA_REL_ "GenSigFirstTimeoutTime" BU_SG_REL_ EBS SG_ 2298429457 BrakePressureSensorDemand_ISig_1 3000;
BA_REL_ "GenSigTimeoutTime" BU_SG_REL_ EBS SG_ 2298429457 BrakePressureSensorDemand_ISig_1 500;
BA_REL_ "GenSigFirstTimeoutTime" BU_SG_REL_ EBS SG_ 2298429457 VehicleMode_UB_ISig_1 3000;
BA_REL_ "GenSigTimeoutTime" BU_SG_REL_ EBS SG_ 2298429457 VehicleMode_UB_ISig_1 60;
BA_REL_ "GenSigFirstTimeoutTime" BU_SG_REL_ TCM SG_ 2298429457 AcctrPedalKickDownSw_stat 3000;
BA_REL_ "GenSigTimeoutTime" BU_SG_REL_ TCM SG_ 2298429457 AcctrPedalKickDownSw_stat 60;
BA_REL_ "GenSigFirstTimeoutTime" BU_SG_REL_ ECM SG_ 2298429457 AcctrPedalKickDownSw_stat 3000;
BA_REL_ "GenSigTimeoutTime" BU_SG_REL_ ECM SG_ 2298429457 AcctrPedalKickDownSw_stat 60;
BA_REL_ "GenSigFirstTimeoutTime" BU_SG_REL_ ECM SG_ 2298429457 TransmissionOutputShaftSpeed 3000;
BA_REL_ "GenSigTimeoutTime" BU_SG_REL_ ECM SG_ 2298429457 TransmissionOutputShaftSpeed 60;
BA_REL_ "GenSigFirstTimeoutTime" BU_SG_REL_ ACM SG_ 2298429457 TransmissionOutputShaftSpeed 3000;
BA_REL_ "GenSigTimeoutTime" BU_SG_REL_ ACM SG_ 2298429457 TransmissionOutputShaftSpeed 60;
BA_REL_ "GenSigFirstTimeoutTime" BU_SG_REL_ EBS SG_ 2298429457 ClutchPedalPosition 3000;
BA_REL_ "GenSigTimeoutTime" BU_SG_REL_ EBS SG_ 2298429457 ClutchPedalPosition 60;
BA_REL_ "GenSigFirstTimeoutTime" BU_SG_REL_ TCM SG_ 2566832401 TotalVehicleDistanceHighRes_ISig 24000;
BA_REL_ "GenSigTimeoutTime" BU_SG_REL_ TCM SG_ 2566832401 TotalVehicleDistanceHighRes_ISig 6000;
BA_REL_ "GenSigFirstTimeoutTime" BU_SG_REL_ EBS SG_ 2566832401 TotalVehicleDistanceHighRes_ISig 24000;
BA_REL_ "GenSigTimeoutTime" BU_SG_REL_ EBS SG_ 2566832401 TotalVehicleDistanceHighRes_ISig 6000;
BA_REL_ "GenSigFirstTimeoutTime" BU_SG_REL_ ACM SG_ 2566832401 TotalVehicleDistanceHighRes_ISig 24000;
BA_REL_ "GenSigTimeoutTime" BU_SG_REL_ ACM SG_ 2566832401 TotalVehicleDistanceHighRes_ISig 6000;
BA_REL_ "GenSigFirstTimeoutTime" BU_SG_REL_ ECM SG_ 2566832401 TotalVehicleDistanceHighRes_ISig 24000;
BA_REL_ "GenSigTimeoutTime" BU_SG_REL_ ECM SG_ 2566832401 TotalVehicleDistanceHighRes_ISig 6000;
BA_REL_ "GenSigFirstTimeoutTime" BU_SG_REL_ ECM SG_ 2364541195 SteeringWheelAngle_ISig_1 3000;
BA_REL_ "GenSigTimeoutTime" BU_SG_REL_ ECM SG_ 2364541195 SteeringWheelAngle_ISig_1 60;
BA_REL_ "GenSigFirstTimeoutTime" BU_SG_REL_ TCM SG_ 2364541195 YawRate_ISig_1 3000;
BA_REL_ "GenSigTimeoutTime" BU_SG_REL_ TCM SG_ 2364541195 YawRate_ISig_1 60;
BA_REL_ "GenSigFirstTimeoutTime" BU_SG_REL_ TCM SG_ 2566803211 ROPEngineControlActive 3000;
BA_REL_ "GenSigTimeoutTime" BU_SG_REL_ TCM SG_ 2566803211 ROPEngineControlActive 600;
BA_REL_ "GenSigFirstTimeoutTime" BU_SG_REL_ VCM SG_ 2566803211 ROPEngineControlActive 3000;
BA_REL_ "GenSigTimeoutTime" BU_SG_REL_ VCM SG_ 2566803211 ROPEngineControlActive 600;
BA_REL_ "GenSigFirstTimeoutTime" BU_SG_REL_ VCM SG_ 2566803211 VDCFullyOperational 3000;
BA_REL_ "GenSigTimeoutTime" BU_SG_REL_ VCM SG_ 2566803211 VDCFullyOperational 600;
BA_REL_ "GenSigFirstTimeoutTime" BU_SG_REL_ VCM SG_ 2566803211 ROPBrakeControlActive 3000;
BA_REL_ "GenSigTimeoutTime" BU_SG_REL_ VCM SG_ 2566803211 ROPBrakeControlActive 600;
BA_REL_ "GenSigFirstTimeoutTime" BU_SG_REL_ TCM SG_ 2566803211 ROPBrakeControlActive 3000;
BA_REL_ "GenSigTimeoutTime" BU_SG_REL_ TCM SG_ 2566803211 ROPBrakeControlActive 600;
BA_REL_ "GenSigFirstTimeoutTime" BU_SG_REL_ VCM SG_ 2566803211 ESCHealthStatus_ISig_1 3000;
BA_REL_ "GenSigTimeoutTime" BU_SG_REL_ VCM SG_ 2566803211 ESCHealthStatus_ISig_1 600;
BA_REL_ "GenSigFirstTimeoutTime" BU_SG_REL_ TCM SG_ 2566803211 YCBrakeControlActive 3000;
BA_REL_ "GenSigTimeoutTime" BU_SG_REL_ TCM SG_ 2566803211 YCBrakeControlActive 600;
BA_REL_ "GenSigFirstTimeoutTime" BU_SG_REL_ VCM SG_ 2566803211 YCBrakeControlActive 3000;
BA_REL_ "GenSigTimeoutTime" BU_SG_REL_ VCM SG_ 2566803211 YCBrakeControlActive 600;
BA_REL_ "GenSigFirstTimeoutTime" BU_SG_REL_ TCM SG_ 2566803211 YCEngineControlActive 3000;
BA_REL_ "GenSigTimeoutTime" BU_SG_REL_ TCM SG_ 2566803211 YCEngineControlActive 600;
BA_REL_ "GenSigFirstTimeoutTime" BU_SG_REL_ VCM SG_ 2566803211 YCEngineControlActive 3000;
BA_REL_ "GenSigTimeoutTime" BU_SG_REL_ VCM SG_ 2566803211 YCEngineControlActive 600;
BA_REL_ "GenSigFirstTimeoutTime" BU_SG_REL_ EBS SG_ 2365524497 DoorsAjar_stat_ISig_1 3000;
BA_REL_ "GenSigTimeoutTime" BU_SG_REL_ EBS SG_ 2365524497 DoorsAjar_stat_ISig_1 150;
BA_REL_ "GenSigFirstTimeoutTime" BU_SG_REL_ ACM SG_ 2348814353 TSC1RECUVMCU_OvrdCtrlMPr 3000;
BA_REL_ "GenSigTimeoutTime" BU_SG_REL_ ACM SG_ 2348814353 TSC1RECUVMCU_OvrdCtrlMPr 300;
BA_REL_ "GenSigFirstTimeoutTime" BU_SG_REL_ EBS SG_ 2348814353 TSC1RECUVMCU_OvrdCtrlMPr 3000;
BA_REL_ "GenSigTimeoutTime" BU_SG_REL_ EBS SG_ 2348814353 TSC1RECUVMCU_OvrdCtrlMPr 300;
BA_REL_ "GenSigFirstTimeoutTime" BU_SG_REL_ EBS SG_ 2348814353 TSC1RECUVMCU_EnRSpdSpdLm 3000;
BA_REL_ "GenSigTimeoutTime" BU_SG_REL_ EBS SG_ 2348814353 TSC1RECUVMCU_EnRSpdSpdLm 300;
BA_REL_ "GenSigFirstTimeoutTime" BU_SG_REL_ ACM SG_ 2348814353 TSC1RECUVMCU_EnRSpdSpdLm 3000;
BA_REL_ "GenSigTimeoutTime" BU_SG_REL_ ACM SG_ 2348814353 TSC1RECUVMCU_EnRSpdSpdLm 300;
BA_REL_ "GenSigFirstTimeoutTime" BU_SG_REL_ EBS SG_ 2348814353 TSC1RECUVMCU_EnRSpdCtrlC 3000;
BA_REL_ "GenSigTimeoutTime" BU_SG_REL_ EBS SG_ 2348814353 TSC1RECUVMCU_EnRSpdCtrlC 300;
BA_REL_ "GenSigFirstTimeoutTime" BU_SG_REL_ ACM SG_ 2348814353 TSC1RECUVMCU_EnRSpdCtrlC 3000;
BA_REL_ "GenSigTimeoutTime" BU_SG_REL_ ACM SG_ 2348814353 TSC1RECUVMCU_EnRSpdCtrlC 300;
BA_REL_ "GenSigFirstTimeoutTime" BU_SG_REL_ EBS SG_ 2348814353 TSC1RECUVMCU_EnOvrdCtrlM 3000;
BA_REL_ "GenSigTimeoutTime" BU_SG_REL_ EBS SG_ 2348814353 TSC1RECUVMCU_EnOvrdCtrlM 300;
BA_REL_ "GenSigFirstTimeoutTime" BU_SG_REL_ ACM SG_ 2348814353 TSC1RECUVMCU_EnOvrdCtrlM 3000;
BA_REL_ "GenSigTimeoutTime" BU_SG_REL_ ACM SG_ 2348814353 TSC1RECUVMCU_EnOvrdCtrlM 300;
BA_REL_ "GenSigFirstTimeoutTime" BU_SG_REL_ EBS SG_ 2348814353 TSC1RECUVMCU_EnRTrqTrqLm 3000;
BA_REL_ "GenSigTimeoutTime" BU_SG_REL_ EBS SG_ 2348814353 TSC1RECUVMCU_EnRTrqTrqLm 300;
BA_REL_ "GenSigFirstTimeoutTime" BU_SG_REL_ ACM SG_ 2348814353 TSC1RECUVMCU_EnRTrqTrqLm 3000;
BA_REL_ "GenSigTimeoutTime" BU_SG_REL_ ACM SG_ 2348814353 TSC1RECUVMCU_EnRTrqTrqLm 300;
BA_REL_ "GenSigFirstTimeoutTime" BU_SG_REL_ VCM SG_ 2348814339 TSC1RECUTECU_EnRTrqTrqLm 3000;
BA_REL_ "GenSigTimeoutTime" BU_SG_REL_ VCM SG_ 2348814339 TSC1RECUTECU_EnRTrqTrqLm 300;
BA_REL_ "GenSigFirstTimeoutTime" BU_SG_REL_ ECM SG_ 2348814339 TSC1RECUTECU_EnRTrqTrqLm 3000;
BA_REL_ "GenSigTimeoutTime" BU_SG_REL_ ECM SG_ 2348814339 TSC1RECUTECU_EnRTrqTrqLm 300;
BA_REL_ "GenSigFirstTimeoutTime" BU_SG_REL_ ACM SG_ 2348814339 TSC1RECUTECU_EnRTrqTrqLm 3000;
BA_REL_ "GenSigTimeoutTime" BU_SG_REL_ ACM SG_ 2348814339 TSC1RECUTECU_EnRTrqTrqLm 300;
BA_REL_ "GenSigFirstTimeoutTime" BU_SG_REL_ ECM SG_ 2348814339 TSC1RECUTECU_EnOvrdCtrlM 3000;
BA_REL_ "GenSigTimeoutTime" BU_SG_REL_ ECM SG_ 2348814339 TSC1RECUTECU_EnOvrdCtrlM 300;
BA_REL_ "GenSigFirstTimeoutTime" BU_SG_REL_ ACM SG_ 2348814339 TSC1RECUTECU_EnOvrdCtrlM 3000;
BA_REL_ "GenSigTimeoutTime" BU_SG_REL_ ACM SG_ 2348814339 TSC1RECUTECU_EnOvrdCtrlM 300;
BA_REL_ "GenSigFirstTimeoutTime" BU_SG_REL_ VCM SG_ 2348814339 TSC1RECUTECU_EnOvrdCtrlM 3000;
BA_REL_ "GenSigTimeoutTime" BU_SG_REL_ VCM SG_ 2348814339 TSC1RECUTECU_EnOvrdCtrlM 300;
BA_REL_ "GenSigFirstTimeoutTime" BU_SG_REL_ ECM SG_ 2348814339 TSC1RECUTECU_OvrdCtrlMPr 3000;
BA_REL_ "GenSigTimeoutTime" BU_SG_REL_ ECM SG_ 2348814339 TSC1RECUTECU_OvrdCtrlMPr 300;
BA_REL_ "GenSigFirstTimeoutTime" BU_SG_REL_ VCM SG_ 2348814339 TSC1RECUTECU_OvrdCtrlMPr 3000;
BA_REL_ "GenSigTimeoutTime" BU_SG_REL_ VCM SG_ 2348814339 TSC1RECUTECU_OvrdCtrlMPr 300;
BA_REL_ "GenSigFirstTimeoutTime" BU_SG_REL_ ACM SG_ 2348814339 TSC1RECUTECU_OvrdCtrlMPr 3000;
BA_REL_ "GenSigTimeoutTime" BU_SG_REL_ ACM SG_ 2348814339 TSC1RECUTECU_OvrdCtrlMPr 300;
BA_REL_ "GenSigFirstTimeoutTime" BU_SG_REL_ VCM SG_ 2348814339 TSC1RECUTECU_EnRSpdSpdLm 3000;
BA_REL_ "GenSigTimeoutTime" BU_SG_REL_ VCM SG_ 2348814339 TSC1RECUTECU_EnRSpdSpdLm 300;
BA_REL_ "GenSigFirstTimeoutTime" BU_SG_REL_ ACM SG_ 2348814339 TSC1RECUTECU_EnRSpdSpdLm 3000;
BA_REL_ "GenSigTimeoutTime" BU_SG_REL_ ACM SG_ 2348814339 TSC1RECUTECU_EnRSpdSpdLm 300;
BA_REL_ "GenSigFirstTimeoutTime" BU_SG_REL_ ECM SG_ 2348814339 TSC1RECUTECU_EnRSpdSpdLm 3000;
BA_REL_ "GenSigTimeoutTime" BU_SG_REL_ ECM SG_ 2348814339 TSC1RECUTECU_EnRSpdSpdLm 300;
BA_REL_ "GenSigFirstTimeoutTime" BU_SG_REL_ ACM SG_ 2348814339 TSC1RECUTECU_EnRSpdCtrlC 3000;
BA_REL_ "GenSigTimeoutTime" BU_SG_REL_ ACM SG_ 2348814339 TSC1RECUTECU_EnRSpdCtrlC 300;
BA_REL_ "GenSigFirstTimeoutTime" BU_SG_REL_ VCM SG_ 2348814339 TSC1RECUTECU_EnRSpdCtrlC 3000;
BA_REL_ "GenSigTimeoutTime" BU_SG_REL_ VCM SG_ 2348814339 TSC1RECUTECU_EnRSpdCtrlC 300;
BA_REL_ "GenSigFirstTimeoutTime" BU_SG_REL_ ECM SG_ 2348814339 TSC1RECUTECU_EnRSpdCtrlC 3000;
BA_REL_ "GenSigTimeoutTime" BU_SG_REL_ ECM SG_ 2348814339 TSC1RECUTECU_EnRSpdCtrlC 300;
BA_REL_ "GenSigFirstTimeoutTime" BU_SG_REL_ ACM SG_ 2348814337 TSC1RECUEMSdap_EnRTrqTrqLm 3000;
BA_REL_ "GenSigTimeoutTime" BU_SG_REL_ ACM SG_ 2348814337 TSC1RECUEMSdap_EnRTrqTrqLm 300;
BA_REL_ "GenSigFirstTimeoutTime" BU_SG_REL_ VCM SG_ 2348814337 TSC1RECUEMSdap_EnRTrqTrqLm 3000;
BA_REL_ "GenSigTimeoutTime" BU_SG_REL_ VCM SG_ 2348814337 TSC1RECUEMSdap_EnRTrqTrqLm 300;
BA_REL_ "GenSigFirstTimeoutTime" BU_SG_REL_ ACM SG_ 2348814337 TSC1RECUEMSdap_OvrdCtrlMPr 3000;
BA_REL_ "GenSigTimeoutTime" BU_SG_REL_ ACM SG_ 2348814337 TSC1RECUEMSdap_OvrdCtrlMPr 300;
BA_REL_ "GenSigFirstTimeoutTime" BU_SG_REL_ VCM SG_ 2348814337 TSC1RECUEMSdap_OvrdCtrlMPr 3000;
BA_REL_ "GenSigTimeoutTime" BU_SG_REL_ VCM SG_ 2348814337 TSC1RECUEMSdap_OvrdCtrlMPr 300;
BA_REL_ "GenSigFirstTimeoutTime" BU_SG_REL_ VCM SG_ 2348814337 TSC1RECUEMSdap_EnRSpdSpdLm 3000;
BA_REL_ "GenSigTimeoutTime" BU_SG_REL_ VCM SG_ 2348814337 TSC1RECUEMSdap_EnRSpdSpdLm 300;
BA_REL_ "GenSigFirstTimeoutTime" BU_SG_REL_ ACM SG_ 2348814337 TSC1RECUEMSdap_EnRSpdSpdLm 3000;
BA_REL_ "GenSigTimeoutTime" BU_SG_REL_ ACM SG_ 2348814337 TSC1RECUEMSdap_EnRSpdSpdLm 300;
BA_REL_ "GenSigFirstTimeoutTime" BU_SG_REL_ ACM SG_ 2348814337 TSC1RECUEMSdap_EnRSpdCtrlC 3000;
BA_REL_ "GenSigTimeoutTime" BU_SG_REL_ ACM SG_ 2348814337 TSC1RECUEMSdap_EnRSpdCtrlC 300;
BA_REL_ "GenSigFirstTimeoutTime" BU_SG_REL_ VCM SG_ 2348814337 TSC1RECUEMSdap_EnRSpdCtrlC 3000;
BA_REL_ "GenSigTimeoutTime" BU_SG_REL_ VCM SG_ 2348814337 TSC1RECUEMSdap_EnRSpdCtrlC 300;
BA_REL_ "GenSigFirstTimeoutTime" BU_SG_REL_ VCM SG_ 2348814337 TSC1RECUEMSdap_EnOvrdCtrlM 3000;
BA_REL_ "GenSigTimeoutTime" BU_SG_REL_ VCM SG_ 2348814337 TSC1RECUEMSdap_EnOvrdCtrlM 300;
BA_REL_ "GenSigFirstTimeoutTime" BU_SG_REL_ ACM SG_ 2348814337 TSC1RECUEMSdap_EnOvrdCtrlM 3000;
BA_REL_ "GenSigTimeoutTime" BU_SG_REL_ ACM SG_ 2348814337 TSC1RECUEMSdap_EnOvrdCtrlM 300;
BA_REL_ "GenSigFirstTimeoutTime" BU_SG_REL_ ACM SG_ 2348814336 TSC1RECUEMSccb_OvrdCtrlMPr 3000;
BA_REL_ "GenSigTimeoutTime" BU_SG_REL_ ACM SG_ 2348814336 TSC1RECUEMSccb_OvrdCtrlMPr 300;
BA_REL_ "GenSigFirstTimeoutTime" BU_SG_REL_ VCM SG_ 2348814336 TSC1RECUEMSccb_OvrdCtrlMPr 3000;
BA_REL_ "GenSigTimeoutTime" BU_SG_REL_ VCM SG_ 2348814336 TSC1RECUEMSccb_OvrdCtrlMPr 300;
BA_REL_ "GenSigFirstTimeoutTime" BU_SG_REL_ VCM SG_ 2348814336 TSC1RECUEMSccb_EnRSpdCtrlC 3000;
BA_REL_ "GenSigTimeoutTime" BU_SG_REL_ VCM SG_ 2348814336 TSC1RECUEMSccb_EnRSpdCtrlC 300;
BA_REL_ "GenSigFirstTimeoutTime" BU_SG_REL_ ACM SG_ 2348814336 TSC1RECUEMSccb_EnRSpdCtrlC 3000;
BA_REL_ "GenSigTimeoutTime" BU_SG_REL_ ACM SG_ 2348814336 TSC1RECUEMSccb_EnRSpdCtrlC 300;
BA_REL_ "GenSigFirstTimeoutTime" BU_SG_REL_ ACM SG_ 2348814336 TSC1RECUEMSccb_EnRTrqTrqLm 3000;
BA_REL_ "GenSigTimeoutTime" BU_SG_REL_ ACM SG_ 2348814336 TSC1RECUEMSccb_EnRTrqTrqLm 300;
BA_REL_ "GenSigFirstTimeoutTime" BU_SG_REL_ VCM SG_ 2348814336 TSC1RECUEMSccb_EnRTrqTrqLm 3000;
BA_REL_ "GenSigTimeoutTime" BU_SG_REL_ VCM SG_ 2348814336 TSC1RECUEMSccb_EnRTrqTrqLm 300;
BA_REL_ "GenSigFirstTimeoutTime" BU_SG_REL_ VCM SG_ 2348814336 TSC1RECUEMSccb_EnOvrdCtrlM 3000;
BA_REL_ "GenSigTimeoutTime" BU_SG_REL_ VCM SG_ 2348814336 TSC1RECUEMSccb_EnOvrdCtrlM 300;
BA_REL_ "GenSigFirstTimeoutTime" BU_SG_REL_ ACM SG_ 2348814336 TSC1RECUEMSccb_EnOvrdCtrlM 3000;
BA_REL_ "GenSigTimeoutTime" BU_SG_REL_ ACM SG_ 2348814336 TSC1RECUEMSccb_EnOvrdCtrlM 300;
BA_REL_ "GenSigFirstTimeoutTime" BU_SG_REL_ ACM SG_ 2348814336 TSC1RECUEMSccb_EnRSpdSpdLm 3000;
BA_REL_ "GenSigTimeoutTime" BU_SG_REL_ ACM SG_ 2348814336 TSC1RECUEMSccb_EnRSpdSpdLm 300;
BA_REL_ "GenSigFirstTimeoutTime" BU_SG_REL_ VCM SG_ 2348814336 TSC1RECUEMSccb_EnRSpdSpdLm 3000;
BA_REL_ "GenSigTimeoutTime" BU_SG_REL_ VCM SG_ 2348814336 TSC1RECUEMSccb_EnRSpdSpdLm 300;
BA_REL_ "GenSigFirstTimeoutTime" BU_SG_REL_ TCM SG_ 2348814347 TSC1RECUABS_EnOvrdCtrlM 3000;
BA_REL_ "GenSigTimeoutTime" BU_SG_REL_ TCM SG_ 2348814347 TSC1RECUABS_EnOvrdCtrlM 300;
BA_REL_ "GenSigFirstTimeoutTime" BU_SG_REL_ ACM SG_ 2348814347 TSC1RECUABS_EnOvrdCtrlM 3000;
BA_REL_ "GenSigTimeoutTime" BU_SG_REL_ ACM SG_ 2348814347 TSC1RECUABS_EnOvrdCtrlM 300;
BA_REL_ "GenSigFirstTimeoutTime" BU_SG_REL_ ACM SG_ 2348814347 TSC1RECUABS_EnRTrqTrqLm 3000;
BA_REL_ "GenSigTimeoutTime" BU_SG_REL_ ACM SG_ 2348814347 TSC1RECUABS_EnRTrqTrqLm 300;
BA_REL_ "GenSigFirstTimeoutTime" BU_SG_REL_ TCM SG_ 2348814347 TSC1RECUABS_EnRTrqTrqLm 3000;
BA_REL_ "GenSigTimeoutTime" BU_SG_REL_ TCM SG_ 2348814347 TSC1RECUABS_EnRTrqTrqLm 300;
BA_REL_ "GenSigFirstTimeoutTime" BU_SG_REL_ ACM SG_ 2348814347 TSC1RECUABS_OvrdCtrlMPr 3000;
BA_REL_ "GenSigTimeoutTime" BU_SG_REL_ ACM SG_ 2348814347 TSC1RECUABS_OvrdCtrlMPr 300;
BA_REL_ "GenSigFirstTimeoutTime" BU_SG_REL_ TCM SG_ 2348814347 TSC1RECUABS_OvrdCtrlMPr 3000;
BA_REL_ "GenSigTimeoutTime" BU_SG_REL_ TCM SG_ 2348814347 TSC1RECUABS_OvrdCtrlMPr 300;
BA_REL_ "GenSigFirstTimeoutTime" BU_SG_REL_ ACM SG_ 2348814347 TSC1RECUABS_EnRSpdSpdLm 3000;
BA_REL_ "GenSigTimeoutTime" BU_SG_REL_ ACM SG_ 2348814347 TSC1RECUABS_EnRSpdSpdLm 300;
BA_REL_ "GenSigFirstTimeoutTime" BU_SG_REL_ TCM SG_ 2348814347 TSC1RECUABS_EnRSpdSpdLm 3000;
BA_REL_ "GenSigTimeoutTime" BU_SG_REL_ TCM SG_ 2348814347 TSC1RECUABS_EnRSpdSpdLm 300;
BA_REL_ "GenSigFirstTimeoutTime" BU_SG_REL_ ACM SG_ 2348814347 TSC1RECUABS_EnRSpdCtrlC 3000;
BA_REL_ "GenSigTimeoutTime" BU_SG_REL_ ACM SG_ 2348814347 TSC1RECUABS_EnRSpdCtrlC 300;
BA_REL_ "GenSigFirstTimeoutTime" BU_SG_REL_ TCM SG_ 2348814347 TSC1RECUABS_EnRSpdCtrlC 3000;
BA_REL_ "GenSigTimeoutTime" BU_SG_REL_ TCM SG_ 2348814347 TSC1RECUABS_EnRSpdCtrlC 300;
BA_REL_ "GenSigFirstTimeoutTime" BU_SG_REL_ ECM SG_ 2348810257 TSC1EMSVMCUtr_EnRSpdCtrlC 3000;
BA_REL_ "GenSigTimeoutTime" BU_SG_REL_ ECM SG_ 2348810257 TSC1EMSVMCUtr_EnRSpdCtrlC 120;
BA_REL_ "GenSigFirstTimeoutTime" BU_SG_REL_ ECM SG_ 2348810257 TSC1EMSVMCUtr_EnRSpdSpdLm 3000;
BA_REL_ "GenSigTimeoutTime" BU_SG_REL_ ECM SG_ 2348810257 TSC1EMSVMCUtr_EnRSpdSpdLm 120;
BA_REL_ "GenSigFirstTimeoutTime" BU_SG_REL_ ECM SG_ 2348810257 TSC1EMSVMCUtr_EnOvrdCtrlM 3000;
BA_REL_ "GenSigTimeoutTime" BU_SG_REL_ ECM SG_ 2348810257 TSC1EMSVMCUtr_EnOvrdCtrlM 120;
BA_REL_ "GenSigFirstTimeoutTime" BU_SG_REL_ ECM SG_ 2348810257 TSC1EMSVMCUtr_OvrdCtrlMPr 3000;
BA_REL_ "GenSigTimeoutTime" BU_SG_REL_ ECM SG_ 2348810257 TSC1EMSVMCUtr_OvrdCtrlMPr 120;
BA_REL_ "GenSigFirstTimeoutTime" BU_SG_REL_ ECM SG_ 2348810257 TSC1EMSVMCUtr_EnRTrqTrqLm 3000;
BA_REL_ "GenSigTimeoutTime" BU_SG_REL_ ECM SG_ 2348810257 TSC1EMSVMCUtr_EnRTrqTrqLm 120;
BA_REL_ "GenSigFirstTimeoutTime" BU_SG_REL_ TCM SG_ 2348810288 TSC1EMSVMCUes_EnRSpdSpdLm 3000;
BA_REL_ "GenSigTimeoutTime" BU_SG_REL_ TCM SG_ 2348810288 TSC1EMSVMCUes_EnRSpdSpdLm 120;
BA_REL_ "GenSigFirstTimeoutTime" BU_SG_REL_ ECM SG_ 2348810288 TSC1EMSVMCUes_EnRSpdSpdLm 3000;
BA_REL_ "GenSigTimeoutTime" BU_SG_REL_ ECM SG_ 2348810288 TSC1EMSVMCUes_EnRSpdSpdLm 120;
BA_REL_ "GenSigFirstTimeoutTime" BU_SG_REL_ ECM SG_ 2348810288 TSC1EMSVMCUes_OvrdCtrlMPr 3000;
BA_REL_ "GenSigTimeoutTime" BU_SG_REL_ ECM SG_ 2348810288 TSC1EMSVMCUes_OvrdCtrlMPr 120;
BA_REL_ "GenSigFirstTimeoutTime" BU_SG_REL_ TCM SG_ 2348810288 TSC1EMSVMCUes_OvrdCtrlMPr 3000;
BA_REL_ "GenSigTimeoutTime" BU_SG_REL_ TCM SG_ 2348810288 TSC1EMSVMCUes_OvrdCtrlMPr 120;
BA_REL_ "GenSigFirstTimeoutTime" BU_SG_REL_ ECM SG_ 2348810288 TSC1EMSVMCUes_EnRSpdCtrlC 3000;
BA_REL_ "GenSigTimeoutTime" BU_SG_REL_ ECM SG_ 2348810288 TSC1EMSVMCUes_EnRSpdCtrlC 120;
BA_REL_ "GenSigFirstTimeoutTime" BU_SG_REL_ TCM SG_ 2348810288 TSC1EMSVMCUes_EnRSpdCtrlC 3000;
BA_REL_ "GenSigTimeoutTime" BU_SG_REL_ TCM SG_ 2348810288 TSC1EMSVMCUes_EnRSpdCtrlC 120;
BA_REL_ "GenSigFirstTimeoutTime" BU_SG_REL_ ECM SG_ 2348810288 TSC1EMSVMCUes_EnOvrdCtrlM 3000;
BA_REL_ "GenSigTimeoutTime" BU_SG_REL_ ECM SG_ 2348810288 TSC1EMSVMCUes_EnOvrdCtrlM 120;
BA_REL_ "GenSigFirstTimeoutTime" BU_SG_REL_ TCM SG_ 2348810288 TSC1EMSVMCUes_EnOvrdCtrlM 3000;
BA_REL_ "GenSigTimeoutTime" BU_SG_REL_ TCM SG_ 2348810288 TSC1EMSVMCUes_EnOvrdCtrlM 120;
BA_REL_ "GenSigFirstTimeoutTime" BU_SG_REL_ ECM SG_ 2348810288 TSC1EMSVMCUes_EnRTrqTrqLm 3000;
BA_REL_ "GenSigTimeoutTime" BU_SG_REL_ ECM SG_ 2348810288 TSC1EMSVMCUes_EnRTrqTrqLm 120;
BA_REL_ "GenSigFirstTimeoutTime" BU_SG_REL_ TCM SG_ 2348810288 TSC1EMSVMCUes_EnRTrqTrqLm 3000;
BA_REL_ "GenSigTimeoutTime" BU_SG_REL_ TCM SG_ 2348810288 TSC1EMSVMCUes_EnRTrqTrqLm 120;
BA_REL_ "GenSigFirstTimeoutTime" BU_SG_REL_ VCM SG_ 2348810243 TSC1EMSTECU_EnRSpdCtrlC 3000;
BA_REL_ "GenSigTimeoutTime" BU_SG_REL_ VCM SG_ 2348810243 TSC1EMSTECU_EnRSpdCtrlC 100;
BA_REL_ "GenSigFirstTimeoutTime" BU_SG_REL_ ECM SG_ 2348810243 TSC1EMSTECU_EnRSpdCtrlC 3000;
BA_REL_ "GenSigTimeoutTime" BU_SG_REL_ ECM SG_ 2348810243 TSC1EMSTECU_EnRSpdCtrlC 60;
BA_REL_ "GenSigFirstTimeoutTime" BU_SG_REL_ VCM SG_ 2348810243 TSC1EMSTECU_EnRSpdSpdLm 3000;
BA_REL_ "GenSigTimeoutTime" BU_SG_REL_ VCM SG_ 2348810243 TSC1EMSTECU_EnRSpdSpdLm 100;
BA_REL_ "GenSigFirstTimeoutTime" BU_SG_REL_ ECM SG_ 2348810243 TSC1EMSTECU_EnRSpdSpdLm 3000;
BA_REL_ "GenSigTimeoutTime" BU_SG_REL_ ECM SG_ 2348810243 TSC1EMSTECU_EnRSpdSpdLm 60;
BA_REL_ "GenSigFirstTimeoutTime" BU_SG_REL_ VCM SG_ 2348810243 TSC1EMSTECU_OvrdCtrlMPr 3000;
BA_REL_ "GenSigTimeoutTime" BU_SG_REL_ VCM SG_ 2348810243 TSC1EMSTECU_OvrdCtrlMPr 100;
BA_REL_ "GenSigFirstTimeoutTime" BU_SG_REL_ ECM SG_ 2348810243 TSC1EMSTECU_OvrdCtrlMPr 3000;
BA_REL_ "GenSigTimeoutTime" BU_SG_REL_ ECM SG_ 2348810243 TSC1EMSTECU_OvrdCtrlMPr 60;
BA_REL_ "GenSigFirstTimeoutTime" BU_SG_REL_ VCM SG_ 2348810243 TSC1EMSTECU_EnRTrqTrqLm 3000;
BA_REL_ "GenSigTimeoutTime" BU_SG_REL_ VCM SG_ 2348810243 TSC1EMSTECU_EnRTrqTrqLm 100;
BA_REL_ "GenSigFirstTimeoutTime" BU_SG_REL_ ECM SG_ 2348810243 TSC1EMSTECU_EnRTrqTrqLm 3000;
BA_REL_ "GenSigTimeoutTime" BU_SG_REL_ ECM SG_ 2348810243 TSC1EMSTECU_EnRTrqTrqLm 60;
BA_REL_ "GenSigFirstTimeoutTime" BU_SG_REL_ VCM SG_ 2348810243 TSC1EMSTECU_EnOvrdCtrlM 3000;
BA_REL_ "GenSigTimeoutTime" BU_SG_REL_ VCM SG_ 2348810243 TSC1EMSTECU_EnOvrdCtrlM 100;
BA_REL_ "GenSigFirstTimeoutTime" BU_SG_REL_ ECM SG_ 2348810243 TSC1EMSTECU_EnOvrdCtrlM 3000;
BA_REL_ "GenSigTimeoutTime" BU_SG_REL_ ECM SG_ 2348810243 TSC1EMSTECU_EnOvrdCtrlM 60;
BA_REL_ "GenSigFirstTimeoutTime" BU_SG_REL_ ECM SG_ 2348810251 TSC1EMSABS_EnRSpdSpdLm 3000;
BA_REL_ "GenSigTimeoutTime" BU_SG_REL_ ECM SG_ 2348810251 TSC1EMSABS_EnRSpdSpdLm 60;
BA_REL_ "GenSigFirstTimeoutTime" BU_SG_REL_ ECM SG_ 2348810251 TSC1EMSABS_EnOvrdCtrlM 3000;
BA_REL_ "GenSigTimeoutTime" BU_SG_REL_ ECM SG_ 2348810251 TSC1EMSABS_EnOvrdCtrlM 60;
BA_REL_ "GenSigFirstTimeoutTime" BU_SG_REL_ ECM SG_ 2348810251 TSC1EMSABS_OvrdCtrlMPr 3000;
BA_REL_ "GenSigTimeoutTime" BU_SG_REL_ ECM SG_ 2348810251 TSC1EMSABS_OvrdCtrlMPr 60;
BA_REL_ "GenSigFirstTimeoutTime" BU_SG_REL_ ECM SG_ 2348810251 TSC1EMSABS_EnRTrqTrqLm 3000;
BA_REL_ "GenSigTimeoutTime" BU_SG_REL_ ECM SG_ 2348810251 TSC1EMSABS_EnRTrqTrqLm 60;
BA_REL_ "GenSigFirstTimeoutTime" BU_SG_REL_ ECM SG_ 2348810251 TSC1EMSABS_EnRSpdCtrlC 3000;
BA_REL_ "GenSigTimeoutTime" BU_SG_REL_ ECM SG_ 2348810251 TSC1EMSABS_EnRSpdCtrlC 60;
BA_REL_ "GenSigFirstTimeoutTime" BU_SG_REL_ ECM SG_ 2348810413 TSC1EMSDACU_EnRSpdSpdLm 3000;
BA_REL_ "GenSigTimeoutTime" BU_SG_REL_ ECM SG_ 2348810413 TSC1EMSDACU_EnRSpdSpdLm 120;
BA_REL_ "GenSigFirstTimeoutTime" BU_SG_REL_ ECM SG_ 2348810413 TSC1EMSDACU_EnOvrdCtrlM 3000;
BA_REL_ "GenSigTimeoutTime" BU_SG_REL_ ECM SG_ 2348810413 TSC1EMSDACU_EnOvrdCtrlM 120;
BA_REL_ "GenSigFirstTimeoutTime" BU_SG_REL_ ECM SG_ 2348810413 TSC1EMSDACU_EnRSpdCtrlC 3000;
BA_REL_ "GenSigTimeoutTime" BU_SG_REL_ ECM SG_ 2348810413 TSC1EMSDACU_EnRSpdCtrlC 120;
BA_REL_ "GenSigFirstTimeoutTime" BU_SG_REL_ ECM SG_ 2348810413 TSC1EMSDACU_OvrdCtrlMPr 3000;
BA_REL_ "GenSigTimeoutTime" BU_SG_REL_ ECM SG_ 2348810413 TSC1EMSDACU_OvrdCtrlMPr 120;
BA_REL_ "GenSigFirstTimeoutTime" BU_SG_REL_ ECM SG_ 2348810413 TSC1EMSDACU_EnRTrqTrqLm 3000;
BA_REL_ "GenSigTimeoutTime" BU_SG_REL_ ECM SG_ 2348810413 TSC1EMSDACU_EnRTrqTrqLm 120;
VAL_ 2349075203 XBRTECU_EBIMode 3 "XBREBIMode_NotDefined" 2 "XBREBIMode_EnduranceBrakeIntegrationAllowed" 1 "XBREBIMode_OnlyEnduranceBrakesAllowed" 0 "XBREBIMode_NoEnduranceBrakeIntegrationAllowed" ;
VAL_ 2349075203 XBRTECU_ControlMode 3 "XBRControlMode_NotDefined" 2 "XBRControlMode_AccelerationControlWithMaximumMode" 1 "XBRControlMode_AccelerationControlWithAdditionMode" 0 "XBRControlMode_OverrideDisabled" ;
VAL_ 2349075203 XBRTECU_Priority 3 "Priority_LowPriority" 2 "Priority_MediumPriority" 1 "Priority_HighPriority" 0 "Priority_HighestPriority" ;
VAL_ 2349075200 XBREMS_EBIMode 3 "XBREBIMode_NotDefined" 2 "XBREBIMode_EnduranceBrakeIntegrationAllowed" 1 "XBREBIMode_OnlyEnduranceBrakesAllowed" 0 "XBREBIMode_NoEnduranceBrakeIntegrationAllowed" ;
VAL_ 2349075200 XBREMS_Priority 3 "Priority_LowPriority" 2 "Priority_MediumPriority" 1 "Priority_HighPriority" 0 "Priority_HighestPriority" ;
VAL_ 2349075200 XBREMS_ControlMode 3 "XBRControlMode_NotDefined" 2 "XBRControlMode_AccelerationControlWithMaximumMode" 1 "XBRControlMode_AccelerationControlWithAdditionMode" 0 "XBRControlMode_OverrideDisabled" ;
VAL_ 2349075373 XBRDACU_Priority 3 "Priority_LowPriority" 2 "Priority_MediumPriority" 1 "Priority_HighPriority" 0 "Priority_HighestPriority" ;
VAL_ 2349075373 XBRDACU_EBIMode 3 "XBREBIMode_NotDefined" 2 "XBREBIMode_EnduranceBrakeIntegrationAllowed" 1 "XBREBIMode_OnlyEnduranceBrakesAllowed" 0 "XBREBIMode_NoEnduranceBrakeIntegrationAllowed" ;
VAL_ 2349075373 XBRDACU_ControlMode 3 "XBRControlMode_NotDefined" 2 "XBRControlMode_AccelerationControlWithMaximumMode" 1 "XBRControlMode_AccelerationControlWithAdditionMode" 0 "XBRControlMode_OverrideDisabled" ;
VAL_ 2566848256 WaterInFuelAlarm 3 "NoYes_NotAvailable" 2 "NoYes_Error" 1 "NoYes_Yes" 0 "NoYes_No" ;
VAL_ 2499788567 DrvrRetarderBrakeBlending_rqst_I 3 "OffOn_NotAvailable" 2 "OffOn_Error" 1 "OffOn_On" 0 "OffOn_Off" ;
VAL_ 2499788567 Trailer2LiftAxle2PosReq 3 "TrailerLiftAxlePosReq_TakeNoAction" 2 "TrailerLiftAxlePosReq_Reserved" 1 "TrailerLiftAxlePosReq_RequestToLiftTheLiftAxle" 0 "TrailerLiftAxlePosReq_RequestToLowerTheLiftAxle" ;
VAL_ 2499788567 Trailer4LiftAxle2PosReq 3 "TrailerLiftAxlePosReq_TakeNoAction" 2 "TrailerLiftAxlePosReq_Reserved" 1 "TrailerLiftAxlePosReq_RequestToLiftTheLiftAxle" 0 "TrailerLiftAxlePosReq_RequestToLowerTheLiftAxle" ;
VAL_ 2499788567 GearLeverPositionBackup 15 "GearLeverPosition_NotAvailable" 14 "GearLeverPosition_Error" 13 "GearLeverPosition_SpareValue_06" 12 "GearLeverPosition_SpareValue_05" 11 "GearLeverPosition_SpareValue_04" 10 "GearLeverPosition_SpareValue_03" 9 "GearLeverPosition_SpareValue_02" 8 "GearLeverPosition_SpareValue_01" 7 "GearLeverPosition_SpareValue" 6 "GearLeverPosition_SEG6" 5 "GearLeverPosition_LowGear" 4 "GearLeverPosition_Manual" 3 "GearLeverPosition_Automatic" 2 "GearLeverPosition_Neutral" 1 "GearLeverPosition_Reverse" 0 "GearLeverPosition_GearFoldedAway" ;
VAL_ 2499788567 Trailer2LiftAxle1PosReq 3 "TrailerLiftAxlePosReq_TakeNoAction" 2 "TrailerLiftAxlePosReq_Reserved" 1 "TrailerLiftAxlePosReq_RequestToLiftTheLiftAxle" 0 "TrailerLiftAxlePosReq_RequestToLowerTheLiftAxle" ;
VAL_ 2499788567 Trailer5LiftAxle2PosReq 3 "TrailerLiftAxlePosReq_TakeNoAction" 2 "TrailerLiftAxlePosReq_Reserved" 1 "TrailerLiftAxlePosReq_RequestToLiftTheLiftAxle" 0 "TrailerLiftAxlePosReq_RequestToLowerTheLiftAxle" ;
VAL_ 2499788567 DriverRetarderRequest_ISig_1 7 "DriverRetarderRequest_NotAvailable" 6 "DriverRetarderRequest_Error" 5 "DriverRetarderRequest_Level5" 4 "DriverRetarderRequest_Level4" 3 "DriverRetarderRequest_Level3" 2 "DriverRetarderRequest_Level2" 1 "DriverRetarderRequest_Level1" 0 "DriverRetarderRequest_NoRequest" ;
VAL_ 2499788567 Trailer1LiftAxl2ePosReq 3 "TrailerLiftAxlePosReq_TakeNoAction" 2 "TrailerLiftAxlePosReq_Reserved" 1 "TrailerLiftAxlePosReq_RequestToLiftTheLiftAxle" 0 "TrailerLiftAxlePosReq_RequestToLowerTheLiftAxle" ;
VAL_ 2499788567 Trailer1LiftAxle1PosReq 3 "TrailerLiftAxlePosReq_TakeNoAction" 2 "TrailerLiftAxlePosReq_Reserved" 1 "TrailerLiftAxlePosReq_RequestToLiftTheLiftAxle" 0 "TrailerLiftAxlePosReq_RequestToLowerTheLiftAxle" ;
VAL_ 2499788567 DrvrRetarderBrakeProgram_rqst_IS 3 "OffOn_NotAvailable" 2 "OffOn_Error" 1 "OffOn_On" 0 "OffOn_Off" ;
VAL_ 2499788567 Trailer4LiftAxle1PosReq 3 "TrailerLiftAxlePosReq_TakeNoAction" 2 "TrailerLiftAxlePosReq_Reserved" 1 "TrailerLiftAxlePosReq_RequestToLiftTheLiftAxle" 0 "TrailerLiftAxlePosReq_RequestToLowerTheLiftAxle" ;
VAL_ 2499788567 EHERearAxleSteeringFuncStatus 7 "FunctionStatus3bit_NotAvailable" 6 "FunctionStatus3bit_Error" 5 "FunctionStatus3bit_SafeMode" 4 "FunctionStatus3bit_Ready" 3 "FunctionStatus3bit_ActivelyCentered" 2 "FunctionStatus3bit_PassiveMode" 1 "FunctionStatus3bit_DegradedMode" 0 "FunctionStatus3bit_ActiveSteering" ;
VAL_ 2499788567 EHRearAxleSteeringFuncStatus 7 "FunctionStatus3bit_NotAvailable" 6 "FunctionStatus3bit_Error" 5 "FunctionStatus3bit_SafeMode" 4 "FunctionStatus3bit_Ready" 3 "FunctionStatus3bit_ActivelyCentered" 2 "FunctionStatus3bit_PassiveMode" 1 "FunctionStatus3bit_DegradedMode" 0 "FunctionStatus3bit_ActiveSteering" ;
VAL_ 2499788567 Trailer5LiftAxle1PosReq 3 "TrailerLiftAxlePosReq_TakeNoAction" 2 "TrailerLiftAxlePosReq_Reserved" 1 "TrailerLiftAxlePosReq_RequestToLiftTheLiftAxle" 0 "TrailerLiftAxlePosReq_RequestToLowerTheLiftAxle" ;
VAL_ 2499788567 Trailer3LiftAxle1PosReq 3 "TrailerLiftAxlePosReq_TakeNoAction" 2 "TrailerLiftAxlePosReq_Reserved" 1 "TrailerLiftAxlePosReq_RequestToLiftTheLiftAxle" 0 "TrailerLiftAxlePosReq_RequestToLowerTheLiftAxle" ;
VAL_ 2499788567 GearLeverPos2Backup_Rqst 15 "GearLeverPosition_NotAvailable" 14 "GearLeverPosition_Error" 13 "GearLeverPosition_SpareValue_06" 12 "GearLeverPosition_SpareValue_05" 11 "GearLeverPosition_SpareValue_04" 10 "GearLeverPosition_SpareValue_03" 9 "GearLeverPosition_SpareValue_02" 8 "GearLeverPosition_SpareValue_01" 7 "GearLeverPosition_SpareValue" 6 "GearLeverPosition_SEG6" 5 "GearLeverPosition_LowGear" 4 "GearLeverPosition_Manual" 3 "GearLeverPosition_Automatic" 2 "GearLeverPosition_Neutral" 1 "GearLeverPosition_Reverse" 0 "GearLeverPosition_GearFoldedAway" ;
VAL_ 2499788567 Trailer3LiftAxle2PosReq 3 "TrailerLiftAxlePosReq_TakeNoAction" 2 "TrailerLiftAxlePosReq_Reserved" 1 "TrailerLiftAxlePosReq_RequestToLiftTheLiftAxle" 0 "TrailerLiftAxlePosReq_RequestToLowerTheLiftAxle" ;
VAL_ 2566899729 LoadCalibFail_WrongHeight 3 "InactiveActiveSpare_NotAvailable" 2 "InactiveActiveSpare_Spare" 1 "InactiveActiveSpare_Active" 0 "InactiveActiveSpare_Inactive" ;
VAL_ 2566899729 LoadCalibrationFeedback_ISig_1 7 "LoadCalibrationFeedback_NotAvailable" 6 "LoadCalibrationFeedback_Spare3" 5 "LoadCalibrationFeedback_Spare2" 4 "LoadCalibrationFeedback_Spare1" 3 "LoadCalibrationFeedback_NOK" 2 "LoadCalibrationFeedback_OK" 1 "LoadCalibrationFeedback_InProgress" 0 "LoadCalibrationFeedback_NotRequested" ;
VAL_ 2566899729 LoadCalibFail_InternalFailure 3 "InactiveActiveSpare_NotAvailable" 2 "InactiveActiveSpare_Spare" 1 "InactiveActiveSpare_Active" 0 "InactiveActiveSpare_Inactive" ;
VAL_ 2566899729 Trailer5CalibStoreReq_CalibType 3 "CalibType_TakeNoAction" 2 "CalibType_Spare" 1 "CalibType_StoreAxleLoadCalibrationUsingVehicleScaleSequence" 0 "CalibType_StoreAxleLoadCalibrationUsingIndividualAxleScale" ;
VAL_ 2566899729 LoadCalibFail_Range 3 "InactiveActiveSpare_NotAvailable" 2 "InactiveActiveSpare_Spare" 1 "InactiveActiveSpare_Active" 0 "InactiveActiveSpare_Inactive" ;
VAL_ 2566899729 LoadCalibFail_InMotion 3 "InactiveActiveSpare_NotAvailable" 2 "InactiveActiveSpare_Spare" 1 "InactiveActiveSpare_Active" 0 "InactiveActiveSpare_Inactive" ;
VAL_ 2566899729 LoadCalibFail_WrongVM 3 "InactiveActiveSpare_NotAvailable" 2 "InactiveActiveSpare_Spare" 1 "InactiveActiveSpare_Active" 0 "InactiveActiveSpare_Inactive" ;
VAL_ 2566899729 LoadCalibFail_OutOfMemory 3 "InactiveActiveSpare_NotAvailable" 2 "InactiveActiveSpare_Spare" 1 "InactiveActiveSpare_Active" 0 "InactiveActiveSpare_Inactive" ;
VAL_ 2566899473 Trailer3CalibStoreReq_CalibType 3 "CalibType_TakeNoAction" 2 "CalibType_Spare" 1 "CalibType_StoreAxleLoadCalibrationUsingVehicleScaleSequence" 0 "CalibType_StoreAxleLoadCalibrationUsingIndividualAxleScale" ;
VAL_ 2566899473 Trailer4CalibStoreReq_CalibType 3 "CalibType_TakeNoAction" 2 "CalibType_Spare" 1 "CalibType_StoreAxleLoadCalibrationUsingVehicleScaleSequence" 0 "CalibType_StoreAxleLoadCalibrationUsingIndividualAxleScale" ;
VAL_ 2566899217 Trailer1CalibStoreReq_CalibType 3 "CalibType_TakeNoAction" 2 "CalibType_Spare" 1 "CalibType_StoreAxleLoadCalibrationUsingVehicleScaleSequence" 0 "CalibType_StoreAxleLoadCalibrationUsingIndividualAxleScale" ;
VAL_ 2566899217 Trailer2CalibStoreReq_CalibType 3 "CalibType_TakeNoAction" 2 "CalibType_Spare" 1 "CalibType_StoreAxleLoadCalibrationUsingVehicleScaleSequence" 0 "CalibType_StoreAxleLoadCalibrationUsingIndividualAxleScale" ;
VAL_ 2499751697 EngineStopReqBackup 3 "Request_NotAvailable" 2 "Request_Error" 1 "Request_RequestActive" 0 "Request_NotRequested" ;
VAL_ 2499751697 TrailerWithoutABS_ISig_1 3 "TrailerWithoutABS_NotAvailableOrNotInstalled" 2 "TrailerWithoutABS_ErrorIndicator" 1 "TrailerWithoutABS_YesTrailerWithoutABS" 0 "TrailerWithoutABS_NoNoTrailerPresentOraTrailerWithABS" ;
VAL_ 2499751697 LowAirPressureAlert_ISig_1 3 "LowAirPressureAlert_NotAvailable" 2 "LowAirPressureAlert_Error" 1 "LowAirPressureAlert_LowPressure" 0 "LowAirPressureAlert_NormalPressure" ;
VAL_ 2499751697 ACC_SGO_Status_ISig_1 15 "ACC_SGO_Status_NotAvailable" 14 "ACC_SGO_Status_Error" 13 "ACC_SGO_Status_Spare7" 12 "ACC_SGO_Status_Spare6" 11 "ACC_SGO_Status_Spare5" 10 "ACC_SGO_Status_Spare4" 9 "ACC_SGO_Status_Spare3" 8 "ACC_SGO_Status_Spare2" 7 "ACC_SGO_Status_Spare1" 6 "ACC_SGO_Status_ACC_SGO_Active_TakeOffRequest" 5 "ACC_SGO_Status_ACC_SGO_Active_Hold" 4 "ACC_SGO_Status_ACC_SGO_Active_Stationary" 3 "ACC_SGO_Status_ACC_SGO_Stopping" 2 "ACC_SGO_Status_ACC_SGO_Active_Driving" 1 "ACC_SGO_Status_ACC_SGO_Inactive" 0 "ACC_SGO_Status_ACC_SGO_OFF" ;
VAL_ 2499751697 DifferentialLockStateFrAxle2 3 "DisengagedEngaged_NotAvailable" 2 "DisengagedEngaged_Error" 1 "DisengagedEngaged_Engaged" 0 "DisengagedEngaged_Disengaged" ;
VAL_ 2499751697 SetHSAOperation_ISig_1 7 "SetHSAOperation_NotAvailable" 6 "SetHSAOperation_Error" 5 "SetHSAOperation_Spare2" 4 "SetHSAOperation_Spare1" 3 "SetHSAOperation_Forbid_HSA_WithCaution" 2 "SetHSAOperation_Forbid_HSA_Activation" 1 "SetHSAOperation_Allow_HSA_WithCaution" 0 "SetHSAOperation_Allow_HSA_Activation" ;
VAL_ 2499751697 CtaBs_HSABbRequest 3 "Request_NotAvailable" 2 "Request_Error" 1 "Request_RequestActive" 0 "Request_NotRequested" ;
VAL_ 2499751697 AWBEnableRequest_ISig_1 3 "DisableEnable_NotAvailable" 2 "DisableEnable_Error" 1 "DisableEnable_Enable" 0 "DisableEnable_Disable" ;
VAL_ 2499751697 RearPropulsionStat_Rear2Axle_ISi 15 "AxlePropulsionStatus_NotAvailable" 14 "AxlePropulsionStatus_Error" 13 "AxlePropulsionStatus_Spare6" 12 "AxlePropulsionStatus_Spare5" 11 "AxlePropulsionStatus_Spare4" 10 "AxlePropulsionStatus_Spare3" 9 "AxlePropulsionStatus_Spare2" 8 "AxlePropulsionStatus_Spare1" 7 "AxlePropulsionStatus_LoweredInterAxleStatusUnknown" 6 "AxlePropulsionStatus_LiftedInterAxleStatusUnknown" 5 "AxlePropulsionStatus_PositionUnknownDriven" 4 "AxlePropulsionStatus_PositionUnknownNonDriven" 3 "AxlePropulsionStatus_LoweredDifferentialLocked" 2 "AxlePropulsionStatus_LoweredDriven" 1 "AxlePropulsionStatus_LoweredNonDriven" 0 "AxlePropulsionStatus_LiftedNonDriven" ;
VAL_ 2499751697 DifferentialLockStateCentral_ISi 3 "DisengageEngage_NotAvailable" 2 "DisengageEngage_Error" 1 "DisengageEngage_Engage" 0 "DisengageEngage_Disengage" ;
VAL_ 2499751697 CentralRearDiffLock_stat_ISig_1 3 "DisengageEngage_NotAvailable" 2 "DisengageEngage_Error" 1 "DisengageEngage_Engage" 0 "DisengageEngage_Disengage" ;
VAL_ 2499751697 ACCHSARequest 7 "ACCHSARequest_NotAvailable" 6 "ACCHSARequest_Error" 5 "ACCHSARequest_Spare3" 4 "ACCHSARequest_Spare2" 3 "ACCHSARequest_Spare1" 2 "ACCHSARequest_BrakingRequested_ACCInFollowingOrHoldControlMode" 1 "ACCHSARequest_NoBrakingRequested_ReleaseBrakesWhenSuitable" 0 "ACCHSARequest_NoBrakingRequested_ReleaseBrakesImmediately" ;
VAL_ 2499751697 DifferentialLockStateFrAxle1_ISi 3 "DisengageEngage_NotAvailable" 2 "DisengageEngage_Error" 1 "DisengageEngage_Engage" 0 "DisengageEngage_Disengage" ;
VAL_ 2499751697 RearAxle2DiffLock_stat_ISig_1 3 "OffOn_NotAvailable" 2 "OffOn_Error" 1 "OffOn_On" 0 "OffOn_Off" ;
VAL_ 2499751697 TrailerConnected_ISig_1 3 "NoYes_NotAvailable" 2 "NoYes_Error" 1 "NoYes_Yes" 0 "NoYes_No" ;
VAL_ 2499751697 DifferentialLockStateCentral2 3 "DisengagedEngaged_NotAvailable" 2 "DisengagedEngaged_Error" 1 "DisengagedEngaged_Engaged" 0 "DisengagedEngaged_Disengaged" ;
VAL_ 2499751697 RearPropulsionStat_Rear3Axle_ISi 15 "AxlePropulsionStatus_NotAvailable" 14 "AxlePropulsionStatus_Error" 13 "AxlePropulsionStatus_Spare6" 12 "AxlePropulsionStatus_Spare5" 11 "AxlePropulsionStatus_Spare4" 10 "AxlePropulsionStatus_Spare3" 9 "AxlePropulsionStatus_Spare2" 8 "AxlePropulsionStatus_Spare1" 7 "AxlePropulsionStatus_LoweredInterAxleStatusUnknown" 6 "AxlePropulsionStatus_LiftedInterAxleStatusUnknown" 5 "AxlePropulsionStatus_PositionUnknownDriven" 4 "AxlePropulsionStatus_PositionUnknownNonDriven" 3 "AxlePropulsionStatus_LoweredDifferentialLocked" 2 "AxlePropulsionStatus_LoweredDriven" 1 "AxlePropulsionStatus_LoweredNonDriven" 0 "AxlePropulsionStatus_LiftedNonDriven" ;
VAL_ 2499751697 RearPropulsionStat_Rear1Axle_ISi 15 "AxlePropulsionStatus_NotAvailable" 14 "AxlePropulsionStatus_Error" 13 "AxlePropulsionStatus_Spare6" 12 "AxlePropulsionStatus_Spare5" 11 "AxlePropulsionStatus_Spare4" 10 "AxlePropulsionStatus_Spare3" 9 "AxlePropulsionStatus_Spare2" 8 "AxlePropulsionStatus_Spare1" 7 "AxlePropulsionStatus_LoweredInterAxleStatusUnknown" 6 "AxlePropulsionStatus_LiftedInterAxleStatusUnknown" 5 "AxlePropulsionStatus_PositionUnknownDriven" 4 "AxlePropulsionStatus_PositionUnknownNonDriven" 3 "AxlePropulsionStatus_LoweredDifferentialLocked" 2 "AxlePropulsionStatus_LoweredDriven" 1 "AxlePropulsionStatus_LoweredNonDriven" 0 "AxlePropulsionStatus_LiftedNonDriven" ;
VAL_ 2499751697 RearAxle1DiffLock_stat_ISig_1 3 "OffOn_NotAvailable" 2 "OffOn_Error" 1 "OffOn_On" 0 "OffOn_Off" ;
VAL_ 2566897425 StaticTrailerBrake_rqst 3 "DeactivateActivate_NotAvailable" 2 "DeactivateActivate_Error" 1 "DeactivateActivate_Activate" 0 "DeactivateActivate_Deactivate" ;
VAL_ 2566897425 StretchBrakeEnable_rqst 7 "StretchBrakeEnable_rqst_NotAvailable" 6 "StretchBrakeEnable_rqst_Error" 5 "StretchBrakeEnable_rqst_Spare_2" 4 "StretchBrakeEnable_rqst_Spare_1" 3 "StretchBrakeEnable_rqst_Enable_PulseLevel3" 2 "StretchBrakeEnable_rqst_Enable_PulseLevel2" 1 "StretchBrakeEnable_rqst_Enable_PulseLevel1" 0 "StretchBrakeEnable_rqst_Disabled" ;
VAL_ 2566897425 AxleLoadStatus_ISig_1 7 "AxleLoadStatus_NotAvailable" 6 "AxleLoadStatus_Error" 5 "AxleLoadStatus_Spare2" 4 "AxleLoadStatus_Spare1" 3 "AxleLoadStatus_Overload" 2 "AxleLoadStatus_HighLoad2" 1 "AxleLoadStatus_HighLoad1" 0 "AxleLoadStatus_NormalLoad" ;
VAL_ 2298429457 SWBrakeSwitch_ISig_1 3 "BrakeSwitch_NotAvailable" 2 "BrakeSwitch_Error" 1 "BrakeSwitch_BrakePedalDepressed" 0 "BrakeSwitch_BrakePedalReleased" ;
VAL_ 2298429457 AcceleratorPedalLowIdleSwitch_IS 3 "AcceleratorPedalLowIdleSwitch_NotAvailable" 2 "AcceleratorPedalLowIdleSwitch_Error" 1 "AcceleratorPedalLowIdleSwitch_INLowIdleCondition" 0 "AcceleratorPedalLowIdleSwitch_NotInLowIdleCondition" ;
VAL_ 2298429457 VehicleMode_ISig_1 15 "VehicleMode_NotAvailable" 14 "VehicleMode_Error" 13 "VehicleMode_Spare_7" 12 "VehicleMode_Spare_6" 11 "VehicleMode_Spare_5" 10 "VehicleMode_Spare_4" 9 "VehicleMode_Spare_3" 8 "VehicleMode_Spare_2" 7 "VehicleMode_Spare_1" 6 "VehicleMode_Running" 5 "VehicleMode_Cranking" 4 "VehicleMode_PreRunning" 3 "VehicleMode_Accessory" 2 "VehicleMode_Living" 1 "VehicleMode_Parked" 0 "VehicleMode_Hibernate" ;
VAL_ 2298429457 AcctrPedalKickDownSw_stat 3 "PassiveActive_NotAvailable" 2 "PassiveActive_Error" 1 "PassiveActive_Active" 0 "PassiveActive_Passive" ;
VAL_ 2566803211 ROPEngineControlActive 3 "PassiveActive2_DontCareTakeNoAction" 2 "PassiveActive2_Reserved" 1 "PassiveActive2_Active" 0 "PassiveActive2_PassiveButInstalled" ;
VAL_ 2566803211 VDCFullyOperational 3 "FullyOperational_NotAvailable" 2 "FullyOperational_Reserved" 1 "FullyOperational_FullyOperational" 0 "FullyOperational_NotFullyOperational" ;
VAL_ 2566803211 ROPBrakeControlActive 3 "PassiveActive2_DontCareTakeNoAction" 2 "PassiveActive2_Reserved" 1 "PassiveActive2_Active" 0 "PassiveActive2_PassiveButInstalled" ;
VAL_ 2566803211 ESCHealthStatus_ISig_1 3 "OffOnSpare_NotAvailable" 2 "OffOnSpare_Spare" 1 "OffOnSpare_On" 0 "OffOnSpare_Off" ;
VAL_ 2566803211 YCBrakeControlActive 3 "PassiveActive2_DontCareTakeNoAction" 2 "PassiveActive2_Reserved" 1 "PassiveActive2_Active" 0 "PassiveActive2_PassiveButInstalled" ;
VAL_ 2566803211 YCEngineControlActive 3 "PassiveActive2_DontCareTakeNoAction" 2 "PassiveActive2_Reserved" 1 "PassiveActive2_Active" 0 "PassiveActive2_PassiveButInstalled" ;
VAL_ 2365524497 DoorsAjar_stat_ISig_1 7 "DoorsAjar_stat_NotAvailable" 6 "DoorsAjar_stat_Error" 5 "DoorsAjar_stat_Spare" 4 "DoorsAjar_stat_BothDoorsAreOpen" 3 "DoorsAjar_stat_PassengerDoorIsOpen" 2 "DoorsAjar_stat_DriverDoorIsOpen" 1 "DoorsAjar_stat_BothDoorsAreClosed" 0 "DoorsAjar_stat_Idle" ;
VAL_ 2348814353 TSC1RECUVMCU_OvrdCtrlMPr 3 "Priority_LowPriority" 2 "Priority_MediumPriority" 1 "Priority_HighPriority" 0 "Priority_HighestPriority" ;
VAL_ 2348814353 TSC1RECUVMCU_EnRSpdCtrlC 3 "TSC1EngReqSpeedCtrlCond_StabilityOptDrvlnEngLockup2" 2 "TSC1EngReqSpeedCtrlCond_StabilityOptDrvlnEngLockup1" 1 "TSC1EngReqSpeedCtrlCond_StabilityOptDrvlnDisengNonLockup" 0 "TSC1EngReqSpeedCtrlCond_TransientOptimized" ;
VAL_ 2348814353 TSC1RECUVMCU_EnOvrdCtrlM 3 "TSC1EngOverrideCtrlMode_SpeedTorqueLimitControl" 2 "TSC1EngOverrideCtrlMode_TorqueControl" 1 "TSC1EngOverrideCtrlMode_SpeedControl" 0 "TSC1EngOverrideCtrlMode_OverrideDisabled" ;
VAL_ 2348814339 TSC1RECUTECU_EnOvrdCtrlM 3 "TSC1EngOverrideCtrlMode_SpeedTorqueLimitControl" 2 "TSC1EngOverrideCtrlMode_TorqueControl" 1 "TSC1EngOverrideCtrlMode_SpeedControl" 0 "TSC1EngOverrideCtrlMode_OverrideDisabled" ;
VAL_ 2348814339 TSC1RECUTECU_OvrdCtrlMPr 3 "Priority_LowPriority" 2 "Priority_MediumPriority" 1 "Priority_HighPriority" 0 "Priority_HighestPriority" ;
VAL_ 2348814339 TSC1RECUTECU_EnRSpdCtrlC 3 "TSC1EngReqSpeedCtrlCond_StabilityOptDrvlnEngLockup2" 2 "TSC1EngReqSpeedCtrlCond_StabilityOptDrvlnEngLockup1" 1 "TSC1EngReqSpeedCtrlCond_StabilityOptDrvlnDisengNonLockup" 0 "TSC1EngReqSpeedCtrlCond_TransientOptimized" ;
VAL_ 2348814337 TSC1RECUEMSdap_OvrdCtrlMPr 3 "Priority_LowPriority" 2 "Priority_MediumPriority" 1 "Priority_HighPriority" 0 "Priority_HighestPriority" ;
VAL_ 2348814337 TSC1RECUEMSdap_EnRSpdCtrlC 3 "TSC1EngReqSpeedCtrlCond_StabilityOptDrvlnEngLockup2" 2 "TSC1EngReqSpeedCtrlCond_StabilityOptDrvlnEngLockup1" 1 "TSC1EngReqSpeedCtrlCond_StabilityOptDrvlnDisengNonLockup" 0 "TSC1EngReqSpeedCtrlCond_TransientOptimized" ;
VAL_ 2348814337 TSC1RECUEMSdap_EnOvrdCtrlM 3 "TSC1EngOverrideCtrlMode_SpeedTorqueLimitControl" 2 "TSC1EngOverrideCtrlMode_TorqueControl" 1 "TSC1EngOverrideCtrlMode_SpeedControl" 0 "TSC1EngOverrideCtrlMode_OverrideDisabled" ;
VAL_ 2348814336 TSC1RECUEMSccb_OvrdCtrlMPr 3 "Priority_LowPriority" 2 "Priority_MediumPriority" 1 "Priority_HighPriority" 0 "Priority_HighestPriority" ;
VAL_ 2348814336 TSC1RECUEMSccb_EnRSpdCtrlC 3 "TSC1EngReqSpeedCtrlCond_StabilityOptDrvlnEngLockup2" 2 "TSC1EngReqSpeedCtrlCond_StabilityOptDrvlnEngLockup1" 1 "TSC1EngReqSpeedCtrlCond_StabilityOptDrvlnDisengNonLockup" 0 "TSC1EngReqSpeedCtrlCond_TransientOptimized" ;
VAL_ 2348814336 TSC1RECUEMSccb_EnOvrdCtrlM 3 "TSC1EngOverrideCtrlMode_SpeedTorqueLimitControl" 2 "TSC1EngOverrideCtrlMode_TorqueControl" 1 "TSC1EngOverrideCtrlMode_SpeedControl" 0 "TSC1EngOverrideCtrlMode_OverrideDisabled" ;
VAL_ 2348814347 TSC1RECUABS_EnOvrdCtrlM 3 "TSC1EngOverrideCtrlMode_SpeedTorqueLimitControl" 2 "TSC1EngOverrideCtrlMode_TorqueControl" 1 "TSC1EngOverrideCtrlMode_SpeedControl" 0 "TSC1EngOverrideCtrlMode_OverrideDisabled" ;
VAL_ 2348814347 TSC1RECUABS_OvrdCtrlMPr 3 "Priority_LowPriority" 2 "Priority_MediumPriority" 1 "Priority_HighPriority" 0 "Priority_HighestPriority" ;
VAL_ 2348814347 TSC1RECUABS_EnRSpdCtrlC 3 "TSC1EngReqSpeedCtrlCond_StabilityOptDrvlnEngLockup2" 2 "TSC1EngReqSpeedCtrlCond_StabilityOptDrvlnEngLockup1" 1 "TSC1EngReqSpeedCtrlCond_StabilityOptDrvlnDisengNonLockup" 0 "TSC1EngReqSpeedCtrlCond_TransientOptimized" ;
VAL_ 2348810257 TSC1EMSVMCUtr_EnRSpdCtrlC 3 "TSC1EngReqSpeedCtrlCond_StabilityOptDrvlnEngLockup2" 2 "TSC1EngReqSpeedCtrlCond_StabilityOptDrvlnEngLockup1" 1 "TSC1EngReqSpeedCtrlCond_StabilityOptDrvlnDisengNonLockup" 0 "TSC1EngReqSpeedCtrlCond_TransientOptimized" ;
VAL_ 2348810257 TSC1EMSVMCUtr_EnOvrdCtrlM 3 "TSC1EngOverrideCtrlMode_SpeedTorqueLimitControl" 2 "TSC1EngOverrideCtrlMode_TorqueControl" 1 "TSC1EngOverrideCtrlMode_SpeedControl" 0 "TSC1EngOverrideCtrlMode_OverrideDisabled" ;
VAL_ 2348810257 TSC1EMSVMCUtr_OvrdCtrlMPr 3 "Priority_LowPriority" 2 "Priority_MediumPriority" 1 "Priority_HighPriority" 0 "Priority_HighestPriority" ;
VAL_ 2348810288 TSC1EMSVMCUes_OvrdCtrlMPr 3 "Priority_LowPriority" 2 "Priority_MediumPriority" 1 "Priority_HighPriority" 0 "Priority_HighestPriority" ;
VAL_ 2348810288 TSC1EMSVMCUes_EnRSpdCtrlC 3 "TSC1EngReqSpeedCtrlCond_StabilityOptDrvlnEngLockup2" 2 "TSC1EngReqSpeedCtrlCond_StabilityOptDrvlnEngLockup1" 1 "TSC1EngReqSpeedCtrlCond_StabilityOptDrvlnDisengNonLockup" 0 "TSC1EngReqSpeedCtrlCond_TransientOptimized" ;
VAL_ 2348810288 TSC1EMSVMCUes_EnOvrdCtrlM 3 "TSC1EngOverrideCtrlMode_SpeedTorqueLimitControl" 2 "TSC1EngOverrideCtrlMode_TorqueControl" 1 "TSC1EngOverrideCtrlMode_SpeedControl" 0 "TSC1EngOverrideCtrlMode_OverrideDisabled" ;
VAL_ 2348810243 TSC1EMSTECU_EnRSpdCtrlC 3 "TSC1EngReqSpeedCtrlCond_StabilityOptDrvlnEngLockup2" 2 "TSC1EngReqSpeedCtrlCond_StabilityOptDrvlnEngLockup1" 1 "TSC1EngReqSpeedCtrlCond_StabilityOptDrvlnDisengNonLockup" 0 "TSC1EngReqSpeedCtrlCond_TransientOptimized" ;
VAL_ 2348810243 TSC1EMSTECU_OvrdCtrlMPr 3 "Priority_LowPriority" 2 "Priority_MediumPriority" 1 "Priority_HighPriority" 0 "Priority_HighestPriority" ;
VAL_ 2348810243 TSC1EMSTECU_EnOvrdCtrlM 3 "TSC1EngOverrideCtrlMode_SpeedTorqueLimitControl" 2 "TSC1EngOverrideCtrlMode_TorqueControl" 1 "TSC1EngOverrideCtrlMode_SpeedControl" 0 "TSC1EngOverrideCtrlMode_OverrideDisabled" ;
VAL_ 2348810251 TSC1EMSABS_EnOvrdCtrlM 3 "TSC1EngOverrideCtrlMode_SpeedTorqueLimitControl" 2 "TSC1EngOverrideCtrlMode_TorqueControl" 1 "TSC1EngOverrideCtrlMode_SpeedControl" 0 "TSC1EngOverrideCtrlMode_OverrideDisabled" ;
VAL_ 2348810251 TSC1EMSABS_OvrdCtrlMPr 3 "Priority_LowPriority" 2 "Priority_MediumPriority" 1 "Priority_HighPriority" 0 "Priority_HighestPriority" ;
VAL_ 2348810251 TSC1EMSABS_EnRSpdCtrlC 3 "TSC1EngReqSpeedCtrlCond_StabilityOptDrvlnEngLockup2" 2 "TSC1EngReqSpeedCtrlCond_StabilityOptDrvlnEngLockup1" 1 "TSC1EngReqSpeedCtrlCond_StabilityOptDrvlnDisengNonLockup" 0 "TSC1EngReqSpeedCtrlCond_TransientOptimized" ;
VAL_ 2348810413 TSC1EMSDACU_EnOvrdCtrlM 3 "TSC1EngOverrideCtrlMode_SpeedTorqueLimitControl" 2 "TSC1EngOverrideCtrlMode_TorqueControl" 1 "TSC1EngOverrideCtrlMode_SpeedControl" 0 "TSC1EngOverrideCtrlMode_OverrideDisabled" ;
VAL_ 2348810413 TSC1EMSDACU_EnRSpdCtrlC 3 "TSC1EngReqSpeedCtrlCond_StabilityOptDrvlnEngLockup2" 2 "TSC1EngReqSpeedCtrlCond_StabilityOptDrvlnEngLockup1" 1 "TSC1EngReqSpeedCtrlCond_StabilityOptDrvlnDisengNonLockup" 0 "TSC1EngReqSpeedCtrlCond_TransientOptimized" ;
VAL_ 2348810413 TSC1EMSDACU_OvrdCtrlMPr 3 "Priority_LowPriority" 2 "Priority_MediumPriority" 1 "Priority_HighPriority" 0 "Priority_HighestPriority" ;
SIG_GROUP_ 2349075203 XBRTECU_sg 1 : XBRTECU_EBIMode XBRTECU_MsgCounter XBRTECU_MsgChecksum XBRTECU_ControlMode XBRTECU_ExtAccelDemand XBRTECU_Urgency XBRTECU_Priority;
SIG_GROUP_ 2349075200 XBREMS_sg 1 : XBREMS_ExtAccelDemand XBREMS_Urgency XBREMS_EBIMode XBREMS_MsgCounter XBREMS_Priority XBREMS_MsgChecksum XBREMS_ControlMode;
SIG_GROUP_ 2349075373 XBRDACU_sg 1 : XBRDACU_Priority XBRDACU_MsgChecksum XBRDACU_MsgCounter XBRDACU_EBIMode XBRDACU_ExtAccelDemand XBRDACU_Urgency XBRDACU_ControlMode;
SIG_GROUP_ 2566845201 VehiclePosSAE_sg 1 : VehiclePosSAE_Longitude VehiclePosSAE_Latitude;
SIG_GROUP_ 2566881297 WheelBasedVehicleSpd_sg_ISig_1 1 : WheelBasedVehicleSpd_CRC_ISig_1 WheelBasedVehicleSpd_SqC_ISig_1 WheelBasedVehicleSpd_Value_ISig_;
SIG_GROUP_ 2566897681 OBDUTCTime_sg 1 : OBDUTCTime_Month OBDUTCTime_Seconds OBDUTCTime_Year OBDUTCTime_Hours OBDUTCTime_Minutes OBDUTCTime_Day;
SIG_GROUP_ 2365535249 DrvAxlBrkPressure_sg 1 : DrvAxlBrkPressure_SqC DrvAxlBrkPressure_Rqst DrvAxlBrkPressure_CRC;
SIG_GROUP_ 2365535249 TrailerBrkPressure_sg 1 : TrailerBrkPressure_SqC TrailerBrkPressure_Rqst TrailerBrkPressure_CRC;
SIG_GROUP_ 2499788567 GearLeverPos2Backup_sg 1 : GearLeverPos2Backup_CRC GearLeverPos2Backup_SqC GearLeverPos2Backup_Rqst;
SIG_GROUP_ 2566899729 LoadCalibFail_sg 1 : LoadCalibFail_WrongHeight LoadCalibFail_InternalFailure LoadCalibFail_Range LoadCalibFail_InMotion LoadCalibFail_WrongVM LoadCalibFail_OutOfMemory;
SIG_GROUP_ 2566899729 Trailer5CalibStoreReq_sg 1 : Trailer5CalibStoreReq_ScaleLoad Trailer5CalibStoreReq_CalibType Trailer5CalibStoreReq_AxleId;
SIG_GROUP_ 2566899473 Trailer4CalibStoreReq_sg 1 : Trailer4CalibStoreReq_CalibType Trailer4CalibStoreReq_AxleId Trailer4CalibStoreReq_ScaleLoad;
SIG_GROUP_ 2566899473 Trailer3CalibStoreReq_sg 1 : Trailer3CalibStoreReq_CalibType Trailer3CalibStoreReq_AxleId Trailer3CalibStoreReq_ScaleLoad;
SIG_GROUP_ 2566899217 Trailer1CalibStoreReq_sg 1 : Trailer1CalibStoreReq_AxleId Trailer1CalibStoreReq_ScaleLoad Trailer1CalibStoreReq_CalibType;
SIG_GROUP_ 2566899217 Trailer2CalibStoreReq_sg 1 : Trailer2CalibStoreReq_ScaleLoad Trailer2CalibStoreReq_AxleId Trailer2CalibStoreReq_CalibType;
SIG_GROUP_ 2499751697 RearPropulsionStat_sg_ISig_1 1 : RearPropulsionStat_Rear2Axle_ISi RearPropulsionStat_Rear3Axle_ISi RearPropulsionStat_Rear1Axle_ISi;
SIG_GROUP_ 2348814353 TSC1RECUVMCU_sg 1 : TSC1RECUVMCU_OvrdCtrlMPr TSC1RECUVMCU_EnRSpdSpdLm TSC1RECUVMCU_EnRSpdCtrlC TSC1RECUVMCU_EnOvrdCtrlM TSC1RECUVMCU_EnRTrqTrqLm;
SIG_GROUP_ 2348814339 TSC1RECUTECU_sg 1 : TSC1RECUTECU_EnRTrqTrqLm TSC1RECUTECU_EnOvrdCtrlM TSC1RECUTECU_OvrdCtrlMPr TSC1RECUTECU_EnRSpdSpdLm TSC1RECUTECU_EnRSpdCtrlC;
SIG_GROUP_ 2348814337 TSC1RECUEMSdap_sg 1 : TSC1RECUEMSdap_EnRTrqTrqLm TSC1RECUEMSdap_OvrdCtrlMPr TSC1RECUEMSdap_EnRSpdSpdLm TSC1RECUEMSdap_EnRSpdCtrlC TSC1RECUEMSdap_EnOvrdCtrlM;
SIG_GROUP_ 2348814336 TSC1RECUEMSccb_sg 1 : TSC1RECUEMSccb_OvrdCtrlMPr TSC1RECUEMSccb_EnRSpdCtrlC TSC1RECUEMSccb_EnRTrqTrqLm TSC1RECUEMSccb_EnOvrdCtrlM TSC1RECUEMSccb_EnRSpdSpdLm;
SIG_GROUP_ 2348814347 TSC1RECUABS_sg 1 : TSC1RECUABS_EnOvrdCtrlM TSC1RECUABS_EnRTrqTrqLm TSC1RECUABS_OvrdCtrlMPr TSC1RECUABS_EnRSpdSpdLm TSC1RECUABS_EnRSpdCtrlC;
SIG_GROUP_ 2348810257 TSC1EMSVMCUtr_sg 1 : TSC1EMSVMCUtr_EnRSpdCtrlC TSC1EMSVMCUtr_EnRSpdSpdLm TSC1EMSVMCUtr_EnOvrdCtrlM TSC1EMSVMCUtr_OvrdCtrlMPr TSC1EMSVMCUtr_EnRTrqTrqLm;
SIG_GROUP_ 2348810288 TSC1EMSVMCUes_sg 1 : TSC1EMSVMCUes_EnRSpdSpdLm TSC1EMSVMCUes_OvrdCtrlMPr TSC1EMSVMCUes_EnRSpdCtrlC TSC1EMSVMCUes_EnOvrdCtrlM TSC1EMSVMCUes_EnRTrqTrqLm;
SIG_GROUP_ 2348810243 TSC1EMSTECU_sg 1 : TSC1EMSTECU_EnRSpdCtrlC TSC1EMSTECU_EnRSpdSpdLm TSC1EMSTECU_OvrdCtrlMPr TSC1EMSTECU_EnRTrqTrqLm TSC1EMSTECU_EnOvrdCtrlM;
SIG_GROUP_ 2348810251 TSC1EMSABS_sg 1 : TSC1EMSABS_EnRSpdSpdLm TSC1EMSABS_EnOvrdCtrlM TSC1EMSABS_OvrdCtrlMPr TSC1EMSABS_EnRTrqTrqLm TSC1EMSABS_EnRSpdCtrlC;
SIG_GROUP_ 2348810413 TSC1EMSDACU_sg 1 : TSC1EMSDACU_EnRSpdSpdLm TSC1EMSDACU_EnOvrdCtrlM TSC1EMSDACU_EnRSpdCtrlC TSC1EMSDACU_OvrdCtrlMPr TSC1EMSDACU_EnRTrqTrqLm;
